VERSION ""

NS_ :

BS_:

BU_: wBMS

VAL_TABLE_ Cell_Balancing_Status 0 "IDLE" 1 "BALANCING" ;
VAL_TABLE_ Battery_Status 0 "INIT" 1 "READY" 2 "ACTIVE" 3 "FAILURE" ;

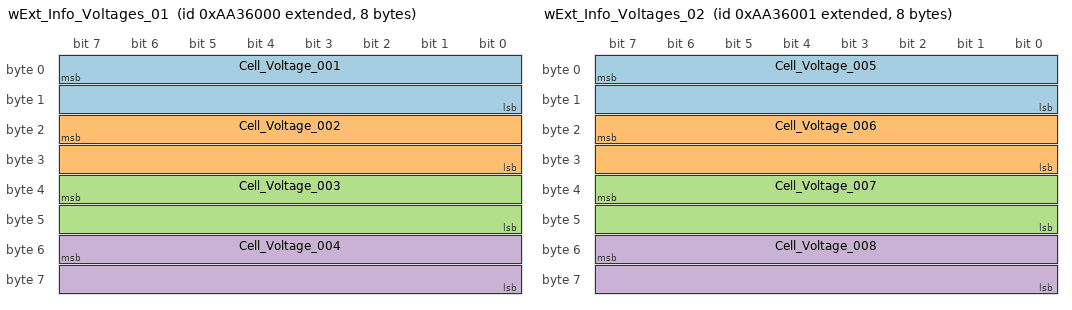
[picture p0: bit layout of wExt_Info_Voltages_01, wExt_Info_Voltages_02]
BO_ 2325962752 wExt_Info_Voltages_01: 8 wBMS
 SG_ Cell_Voltage_001 : 7|16@0+ (0.001,0) [0|0] "V" Vector__XXX
 SG_ Cell_Voltage_002 : 23|16@0+ (0.001,0) [0|0] "V" Vector__XXX
 SG_ Cell_Voltage_003 : 39|16@0+ (0.001,0) [0|0] "V" Vector__XXX
 SG_ Cell_Voltage_004 : 55|16@0+ (0.001,0) [0|0] "V" Vector__XXX

BO_ 2325962753 wExt_Info_Voltages_02: 8 wBMS
 SG_ Cell_Voltage_005 : 7|16@0+ (0.001,0) [0|0] "V" Vector__XXX
 SG_ Cell_Voltage_006 : 23|16@0+ (0.001,0) [0|0] "V" Vector__XXX
 SG_ Cell_Voltage_007 : 39|16@0+ (0.001,0) [0|0] "V" Vector__XXX
 SG_ Cell_Voltage_008 : 55|16@0+ (0.001,0) [0|0] "V" Vector__XXX

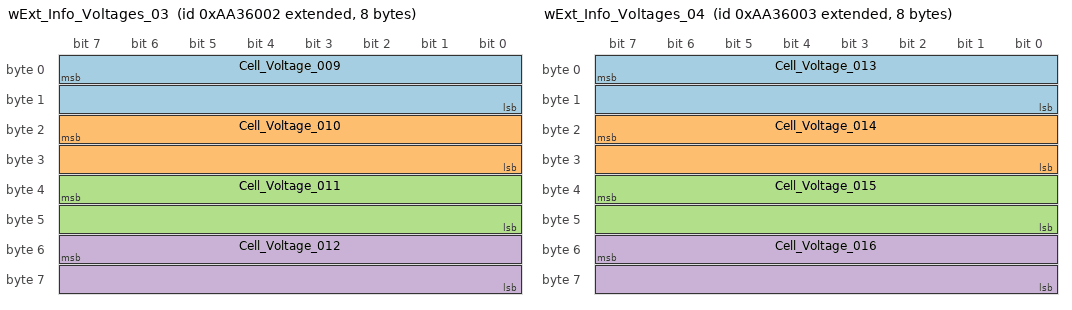
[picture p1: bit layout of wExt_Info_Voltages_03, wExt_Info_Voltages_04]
BO_ 2325962754 wExt_Info_Voltages_03: 8 wBMS
 SG_ Cell_Voltage_009 : 7|16@0+ (0.001,0) [0|0] "V" Vector__XXX
 SG_ Cell_Voltage_010 : 23|16@0+ (0.001,0) [0|0] "V" Vector__XXX
 SG_ Cell_Voltage_011 : 39|16@0+ (0.001,0) [0|0] "V" Vector__XXX
 SG_ Cell_Voltage_012 : 55|16@0+ (0.001,0) [0|0] "V" Vector__XXX

BO_ 2325962755 wExt_Info_Voltages_04: 8 wBMS
 SG_ Cell_Voltage_013 : 7|16@0+ (0.001,0) [0|0] "V" Vector__XXX
 SG_ Cell_Voltage_014 : 23|16@0+ (0.001,0) [0|0] "V" Vector__XXX
 SG_ Cell_Voltage_015 : 39|16@0+ (0.001,0) [0|0] "V" Vector__XXX
 SG_ Cell_Voltage_016 : 55|16@0+ (0.001,0) [0|0] "V" Vector__XXX

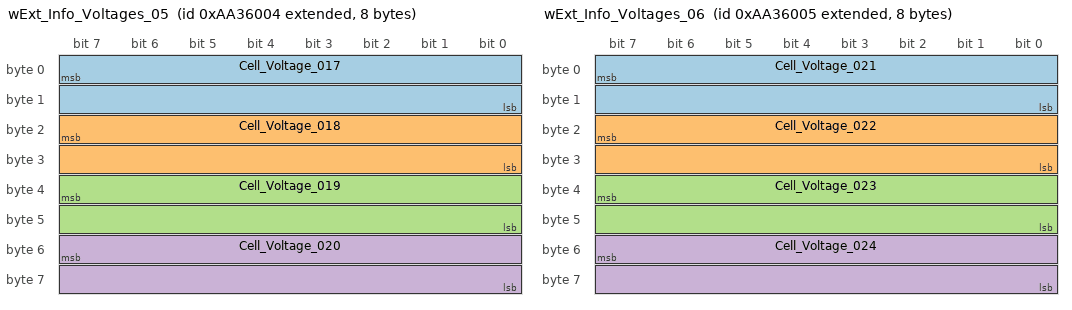
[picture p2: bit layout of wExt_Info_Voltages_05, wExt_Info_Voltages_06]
BO_ 2325962756 wExt_Info_Voltages_05: 8 wBMS
 SG_ Cell_Voltage_017 : 7|16@0+ (0.001,0) [0|0] "V" Vector__XXX
 SG_ Cell_Voltage_018 : 23|16@0+ (0.001,0) [0|0] "V" Vector__XXX
 SG_ Cell_Voltage_019 : 39|16@0+ (0.001,0) [0|0] "V" Vector__XXX
 SG_ Cell_Voltage_020 : 55|16@0+ (0.001,0) [0|0] "V" Vector__XXX

BO_ 2325962757 wExt_Info_Voltages_06: 8 wBMS
 SG_ Cell_Voltage_021 : 7|16@0+ (0.001,0) [0|0] "V" Vector__XXX
 SG_ Cell_Voltage_022 : 23|16@0+ (0.001,0) [0|0] "V" Vector__XXX
 SG_ Cell_Voltage_023 : 39|16@0+ (0.001,0) [0|0] "V" Vector__XXX
 SG_ Cell_Voltage_024 : 55|16@0+ (0.001,0) [0|0] "V" Vector__XXX

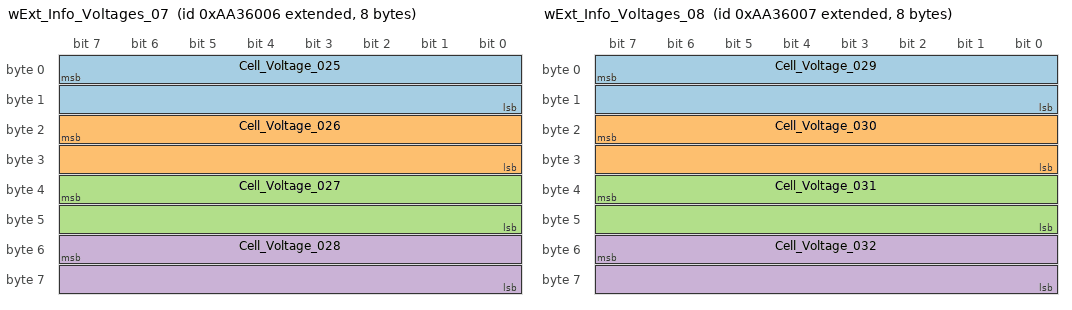
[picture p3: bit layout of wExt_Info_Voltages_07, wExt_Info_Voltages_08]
BO_ 2325962758 wExt_Info_Voltages_07: 8 wBMS
 SG_ Cell_Voltage_025 : 7|16@0+ (0.001,0) [0|0] "V" Vector__XXX
 SG_ Cell_Voltage_026 : 23|16@0+ (0.001,0) [0|0] "V" Vector__XXX
 SG_ Cell_Voltage_027 : 39|16@0+ (0.001,0) [0|0] "V" Vector__XXX
 SG_ Cell_Voltage_028 : 55|16@0+ (0.001,0) [0|0] "V" Vector__XXX

BO_ 2325962759 wExt_Info_Voltages_08: 8 wBMS
 SG_ Cell_Voltage_029 : 7|16@0+ (0.001,0) [0|0] "V" Vector__XXX
 SG_ Cell_Voltage_030 : 23|16@0+ (0.001,0) [0|0] "V" Vector__XXX
 SG_ Cell_Voltage_031 : 39|16@0+ (0.001,0) [0|0] "V" Vector__XXX
 SG_ Cell_Voltage_032 : 55|16@0+ (0.001,0) [0|0] "V" Vector__XXX

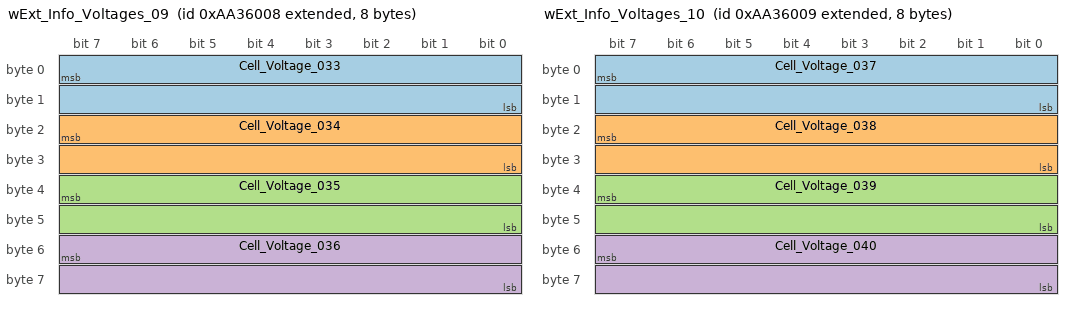
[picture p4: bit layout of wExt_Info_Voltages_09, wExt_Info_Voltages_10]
BO_ 2325962760 wExt_Info_Voltages_09: 8 wBMS
 SG_ Cell_Voltage_033 : 7|16@0+ (0.001,0) [0|0] "V" Vector__XXX
 SG_ Cell_Voltage_034 : 23|16@0+ (0.001,0) [0|0] "V" Vector__XXX
 SG_ Cell_Voltage_035 : 39|16@0+ (0.001,0) [0|0] "V" Vector__XXX
 SG_ Cell_Voltage_036 : 55|16@0+ (0.001,0) [0|0] "V" Vector__XXX

BO_ 2325962761 wExt_Info_Voltages_10: 8 wBMS
 SG_ Cell_Voltage_037 : 7|16@0+ (0.001,0) [0|0] "V" Vector__XXX
 SG_ Cell_Voltage_038 : 23|16@0+ (0.001,0) [0|0] "V" Vector__XXX
 SG_ Cell_Voltage_039 : 39|16@0+ (0.001,0) [0|0] "V" Vector__XXX
 SG_ Cell_Voltage_040 : 55|16@0+ (0.001,0) [0|0] "V" Vector__XXX

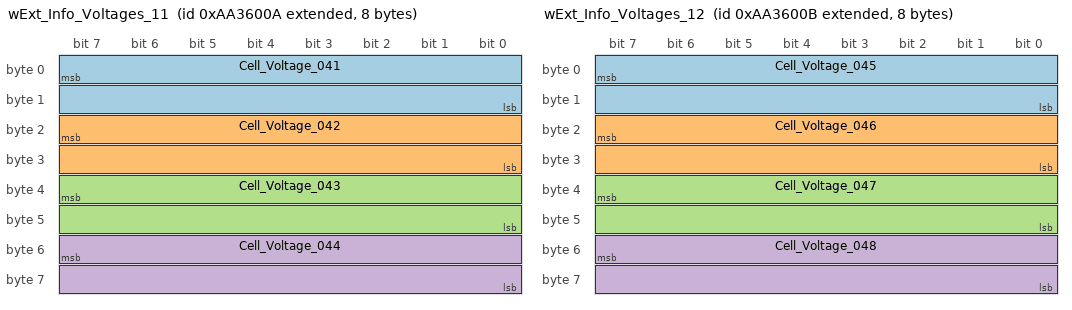
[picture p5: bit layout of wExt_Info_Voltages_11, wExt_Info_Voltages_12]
BO_ 2325962762 wExt_Info_Voltages_11: 8 wBMS
 SG_ Cell_Voltage_041 : 7|16@0+ (0.001,0) [0|0] "V" Vector__XXX
 SG_ Cell_Voltage_042 : 23|16@0+ (0.001,0) [0|0] "V" Vector__XXX
 SG_ Cell_Voltage_043 : 39|16@0+ (0.001,0) [0|0] "V" Vector__XXX
 SG_ Cell_Voltage_044 : 55|16@0+ (0.001,0) [0|0] "V" Vector__XXX

BO_ 2325962763 wExt_Info_Voltages_12: 8 wBMS
 SG_ Cell_Voltage_045 : 7|16@0+ (0.001,0) [0|0] "V" Vector__XXX
 SG_ Cell_Voltage_046 : 23|16@0+ (0.001,0) [0|0] "V" Vector__XXX
 SG_ Cell_Voltage_047 : 39|16@0+ (0.001,0) [0|0] "V" Vector__XXX
 SG_ Cell_Voltage_048 : 55|16@0+ (0.001,0) [0|0] "V" Vector__XXX

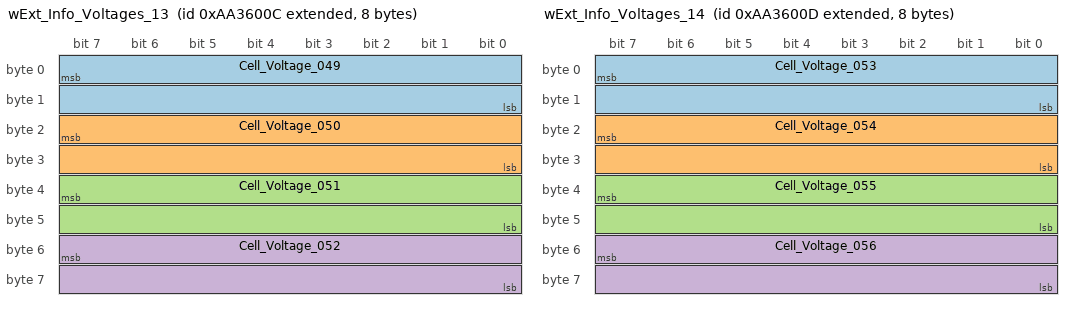
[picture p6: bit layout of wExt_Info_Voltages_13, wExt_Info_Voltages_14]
BO_ 2325962764 wExt_Info_Voltages_13: 8 wBMS
 SG_ Cell_Voltage_049 : 7|16@0+ (0.001,0) [0|0] "V" Vector__XXX
 SG_ Cell_Voltage_050 : 23|16@0+ (0.001,0) [0|0] "V" Vector__XXX
 SG_ Cell_Voltage_051 : 39|16@0+ (0.001,0) [0|0] "V" Vector__XXX
 SG_ Cell_Voltage_052 : 55|16@0+ (0.001,0) [0|0] "V" Vector__XXX

BO_ 2325962765 wExt_Info_Voltages_14: 8 wBMS
 SG_ Cell_Voltage_053 : 7|16@0+ (0.001,0) [0|0] "V" Vector__XXX
 SG_ Cell_Voltage_054 : 23|16@0+ (0.001,0) [0|0] "V" Vector__XXX
 SG_ Cell_Voltage_055 : 39|16@0+ (0.001,0) [0|0] "V" Vector__XXX
 SG_ Cell_Voltage_056 : 55|16@0+ (0.001,0) [0|0] "V" Vector__XXX

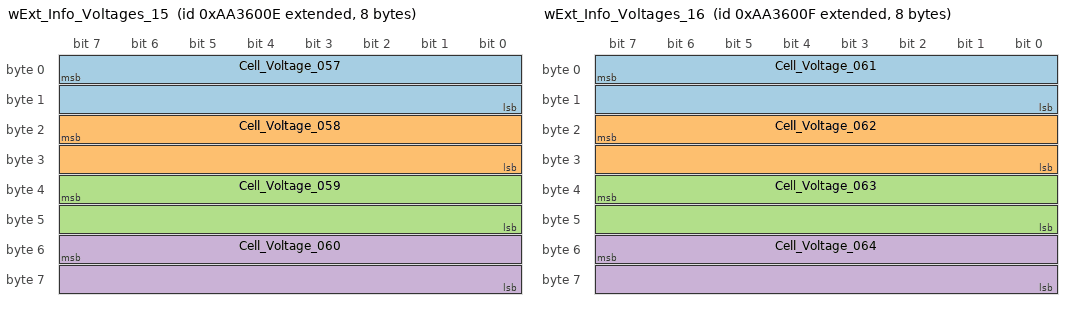
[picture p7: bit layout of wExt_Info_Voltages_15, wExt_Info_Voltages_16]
BO_ 2325962766 wExt_Info_Voltages_15: 8 wBMS
 SG_ Cell_Voltage_057 : 7|16@0+ (0.001,0) [0|0] "V" Vector__XXX
 SG_ Cell_Voltage_058 : 23|16@0+ (0.001,0) [0|0] "V" Vector__XXX
 SG_ Cell_Voltage_059 : 39|16@0+ (0.001,0) [0|0] "V" Vector__XXX
 SG_ Cell_Voltage_060 : 55|16@0+ (0.001,0) [0|0] "V" Vector__XXX

BO_ 2325962767 wExt_Info_Voltages_16: 8 wBMS
 SG_ Cell_Voltage_061 : 7|16@0+ (0.001,0) [0|0] "V" Vector__XXX
 SG_ Cell_Voltage_062 : 23|16@0+ (0.001,0) [0|0] "V" Vector__XXX
 SG_ Cell_Voltage_063 : 39|16@0+ (0.001,0) [0|0] "V" Vector__XXX
 SG_ Cell_Voltage_064 : 55|16@0+ (0.001,0) [0|0] "V" Vector__XXX

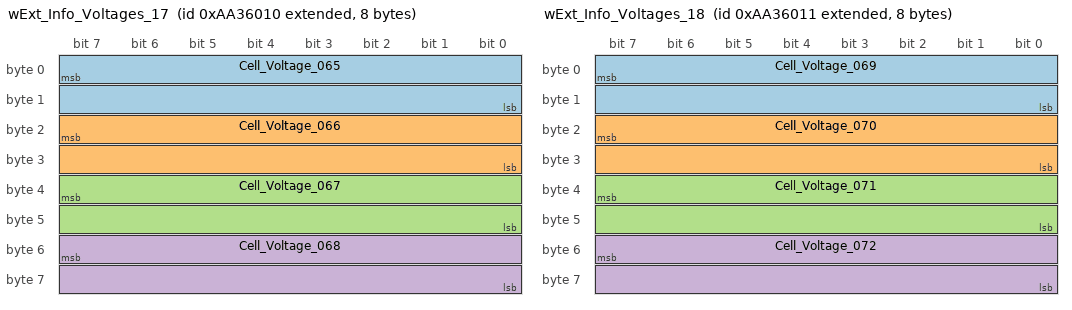
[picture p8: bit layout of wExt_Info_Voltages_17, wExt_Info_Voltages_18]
BO_ 2325962768 wExt_Info_Voltages_17: 8 wBMS
 SG_ Cell_Voltage_065 : 7|16@0+ (0.001,0) [0|0] "V" Vector__XXX
 SG_ Cell_Voltage_066 : 23|16@0+ (0.001,0) [0|0] "V" Vector__XXX
 SG_ Cell_Voltage_067 : 39|16@0+ (0.001,0) [0|0] "V" Vector__XXX
 SG_ Cell_Voltage_068 : 55|16@0+ (0.001,0) [0|0] "V" Vector__XXX

BO_ 2325962769 wExt_Info_Voltages_18: 8 wBMS
 SG_ Cell_Voltage_069 : 7|16@0+ (0.001,0) [0|0] "V" Vector__XXX
 SG_ Cell_Voltage_070 : 23|16@0+ (0.001,0) [0|0] "V" Vector__XXX
 SG_ Cell_Voltage_071 : 39|16@0+ (0.001,0) [0|0] "V" Vector__XXX
 SG_ Cell_Voltage_072 : 55|16@0+ (0.001,0) [0|0] "V" Vector__XXX

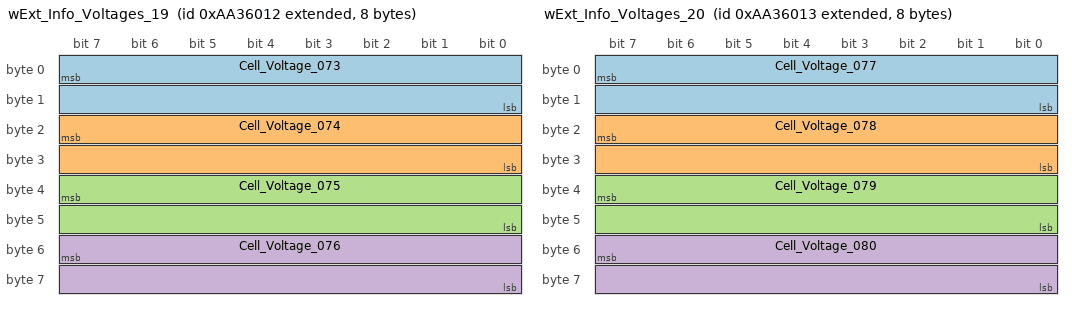
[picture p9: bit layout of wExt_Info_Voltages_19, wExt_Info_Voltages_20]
BO_ 2325962770 wExt_Info_Voltages_19: 8 wBMS
 SG_ Cell_Voltage_073 : 7|16@0+ (0.001,0) [0|0] "V" Vector__XXX
 SG_ Cell_Voltage_074 : 23|16@0+ (0.001,0) [0|0] "V" Vector__XXX
 SG_ Cell_Voltage_075 : 39|16@0+ (0.001,0) [0|0] "V" Vector__XXX
 SG_ Cell_Voltage_076 : 55|16@0+ (0.001,0) [0|0] "V" Vector__XXX

BO_ 2325962771 wExt_Info_Voltages_20: 8 wBMS
 SG_ Cell_Voltage_077 : 7|16@0+ (0.001,0) [0|0] "V" Vector__XXX
 SG_ Cell_Voltage_078 : 23|16@0+ (0.001,0) [0|0] "V" Vector__XXX
 SG_ Cell_Voltage_079 : 39|16@0+ (0.001,0) [0|0] "V" Vector__XXX
 SG_ Cell_Voltage_080 : 55|16@0+ (0.001,0) [0|0] "V" Vector__XXX

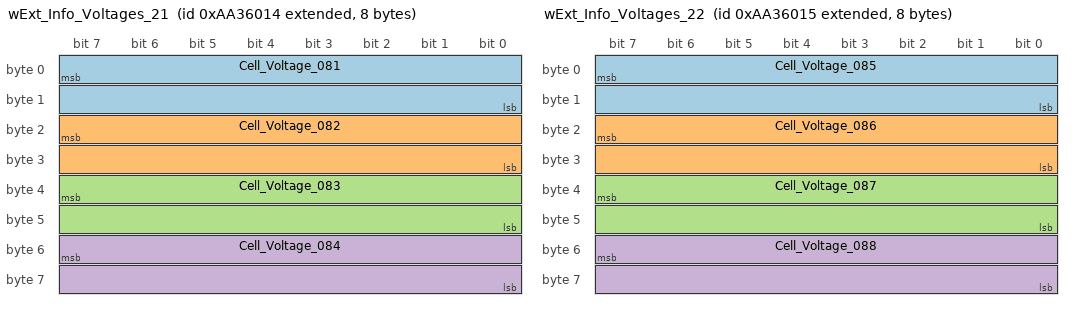
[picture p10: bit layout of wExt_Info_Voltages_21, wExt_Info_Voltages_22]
BO_ 2325962772 wExt_Info_Voltages_21: 8 wBMS
 SG_ Cell_Voltage_081 : 7|16@0+ (0.001,0) [0|0] "V" Vector__XXX
 SG_ Cell_Voltage_082 : 23|16@0+ (0.001,0) [0|0] "V" Vector__XXX
 SG_ Cell_Voltage_083 : 39|16@0+ (0.001,0) [0|0] "V" Vector__XXX
 SG_ Cell_Voltage_084 : 55|16@0+ (0.001,0) [0|0] "V" Vector__XXX

BO_ 2325962773 wExt_Info_Voltages_22: 8 wBMS
 SG_ Cell_Voltage_085 : 7|16@0+ (0.001,0) [0|0] "V" Vector__XXX
 SG_ Cell_Voltage_086 : 23|16@0+ (0.001,0) [0|0] "V" Vector__XXX
 SG_ Cell_Voltage_087 : 39|16@0+ (0.001,0) [0|0] "V" Vector__XXX
 SG_ Cell_Voltage_088 : 55|16@0+ (0.001,0) [0|0] "V" Vector__XXX

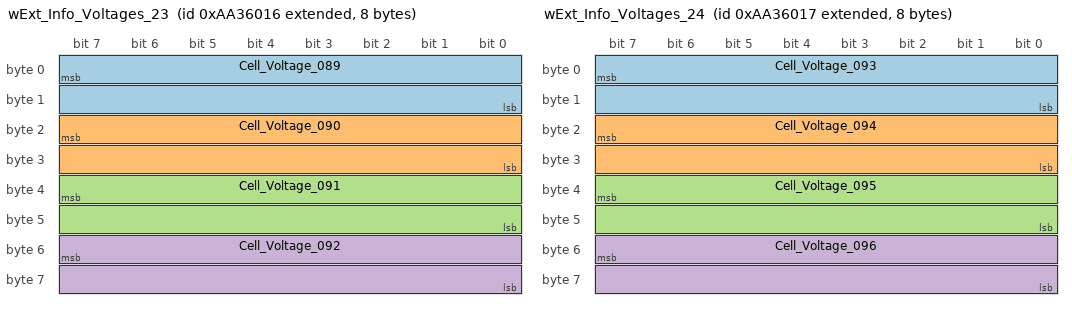
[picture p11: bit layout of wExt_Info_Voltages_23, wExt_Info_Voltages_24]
BO_ 2325962774 wExt_Info_Voltages_23: 8 wBMS
 SG_ Cell_Voltage_089 : 7|16@0+ (0.001,0) [0|0] "V" Vector__XXX
 SG_ Cell_Voltage_090 : 23|16@0+ (0.001,0) [0|0] "V" Vector__XXX
 SG_ Cell_Voltage_091 : 39|16@0+ (0.001,0) [0|0] "V" Vector__XXX
 SG_ Cell_Voltage_092 : 55|16@0+ (0.001,0) [0|0] "V" Vector__XXX

BO_ 2325962775 wExt_Info_Voltages_24: 8 wBMS
 SG_ Cell_Voltage_093 : 7|16@0+ (0.001,0) [0|0] "V" Vector__XXX
 SG_ Cell_Voltage_094 : 23|16@0+ (0.001,0) [0|0] "V" Vector__XXX
 SG_ Cell_Voltage_095 : 39|16@0+ (0.001,0) [0|0] "V" Vector__XXX
 SG_ Cell_Voltage_096 : 55|16@0+ (0.001,0) [0|0] "V" Vector__XXX

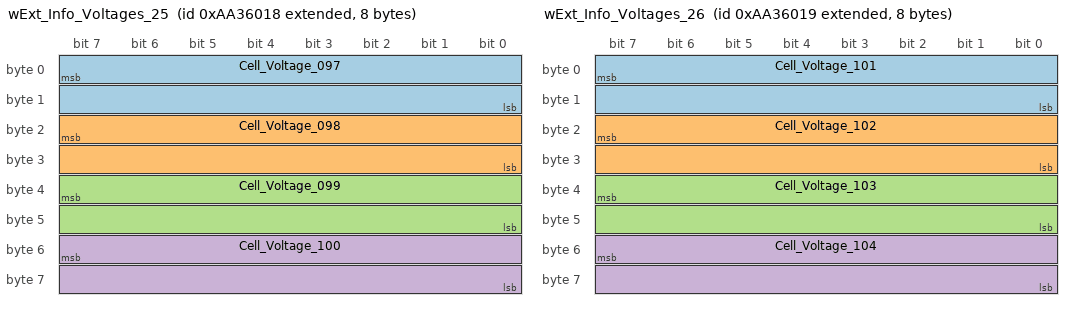
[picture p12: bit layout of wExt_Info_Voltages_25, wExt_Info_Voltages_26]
BO_ 2325962776 wExt_Info_Voltages_25: 8 wBMS
 SG_ Cell_Voltage_097 : 7|16@0+ (0.001,0) [0|0] "V" Vector__XXX
 SG_ Cell_Voltage_098 : 23|16@0+ (0.001,0) [0|0] "V" Vector__XXX
 SG_ Cell_Voltage_099 : 39|16@0+ (0.001,0) [0|0] "V" Vector__XXX
 SG_ Cell_Voltage_100 : 55|16@0+ (0.001,0) [0|0] "V" Vector__XXX

BO_ 2325962777 wExt_Info_Voltages_26: 8 wBMS
 SG_ Cell_Voltage_101 : 7|16@0+ (0.001,0) [0|0] "V" Vector__XXX
 SG_ Cell_Voltage_102 : 23|16@0+ (0.001,0) [0|0] "V" Vector__XXX
 SG_ Cell_Voltage_103 : 39|16@0+ (0.001,0) [0|0] "V" Vector__XXX
 SG_ Cell_Voltage_104 : 55|16@0+ (0.001,0) [0|0] "V" Vector__XXX

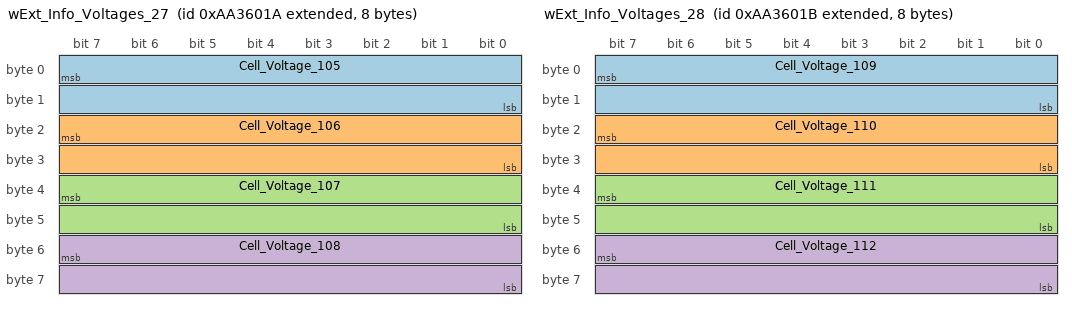
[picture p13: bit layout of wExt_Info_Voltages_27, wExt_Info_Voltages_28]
BO_ 2325962778 wExt_Info_Voltages_27: 8 wBMS
 SG_ Cell_Voltage_105 : 7|16@0+ (0.001,0) [0|0] "V" Vector__XXX
 SG_ Cell_Voltage_106 : 23|16@0+ (0.001,0) [0|0] "V" Vector__XXX
 SG_ Cell_Voltage_107 : 39|16@0+ (0.001,0) [0|0] "V" Vector__XXX
 SG_ Cell_Voltage_108 : 55|16@0+ (0.001,0) [0|0] "V" Vector__XXX

BO_ 2325962779 wExt_Info_Voltages_28: 8 wBMS
 SG_ Cell_Voltage_109 : 7|16@0+ (0.001,0) [0|0] "V" Vector__XXX
 SG_ Cell_Voltage_110 : 23|16@0+ (0.001,0) [0|0] "V" Vector__XXX
 SG_ Cell_Voltage_111 : 39|16@0+ (0.001,0) [0|0] "V" Vector__XXX
 SG_ Cell_Voltage_112 : 55|16@0+ (0.001,0) [0|0] "V" Vector__XXX

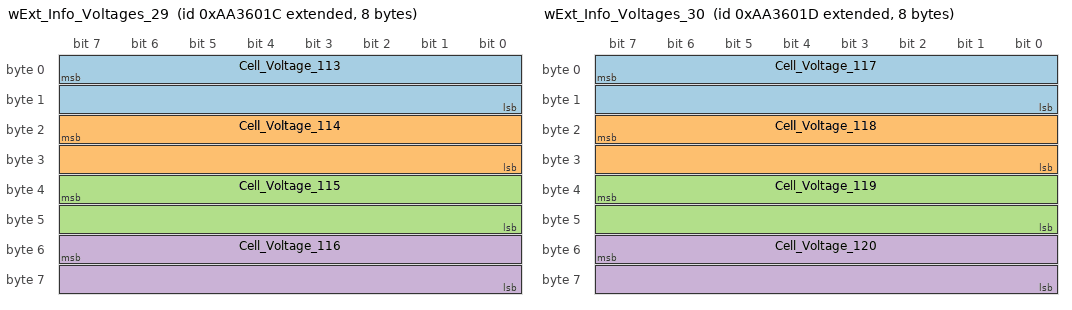
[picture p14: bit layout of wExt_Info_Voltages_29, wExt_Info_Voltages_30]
BO_ 2325962780 wExt_Info_Voltages_29: 8 wBMS
 SG_ Cell_Voltage_113 : 7|16@0+ (0.001,0) [0|0] "V" Vector__XXX
 SG_ Cell_Voltage_114 : 23|16@0+ (0.001,0) [0|0] "V" Vector__XXX
 SG_ Cell_Voltage_115 : 39|16@0+ (0.001,0) [0|0] "V" Vector__XXX
 SG_ Cell_Voltage_116 : 55|16@0+ (0.001,0) [0|0] "V" Vector__XXX

BO_ 2325962781 wExt_Info_Voltages_30: 8 wBMS
 SG_ Cell_Voltage_117 : 7|16@0+ (0.001,0) [0|0] "V" Vector__XXX
 SG_ Cell_Voltage_118 : 23|16@0+ (0.001,0) [0|0] "V" Vector__XXX
 SG_ Cell_Voltage_119 : 39|16@0+ (0.001,0) [0|0] "V" Vector__XXX
 SG_ Cell_Voltage_120 : 55|16@0+ (0.001,0) [0|0] "V" Vector__XXX

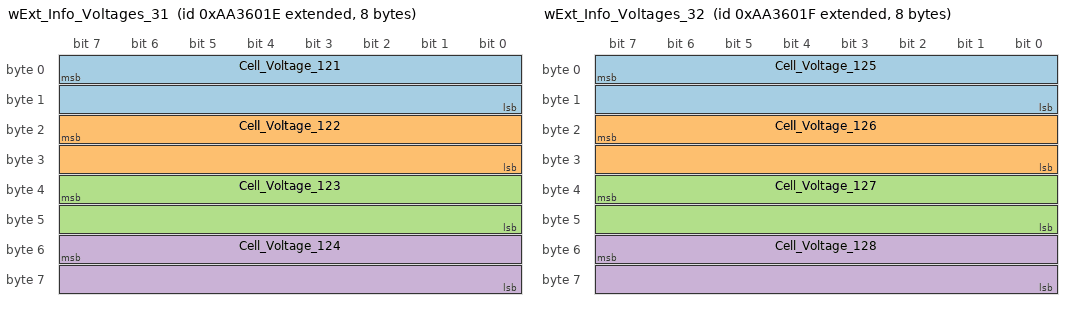
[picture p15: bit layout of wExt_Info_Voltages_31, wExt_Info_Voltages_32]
BO_ 2325962782 wExt_Info_Voltages_31: 8 wBMS
 SG_ Cell_Voltage_121 : 7|16@0+ (0.001,0) [0|0] "V" Vector__XXX
 SG_ Cell_Voltage_122 : 23|16@0+ (0.001,0) [0|0] "V" Vector__XXX
 SG_ Cell_Voltage_123 : 39|16@0+ (0.001,0) [0|0] "V" Vector__XXX
 SG_ Cell_Voltage_124 : 55|16@0+ (0.001,0) [0|0] "V" Vector__XXX

BO_ 2325962783 wExt_Info_Voltages_32: 8 wBMS
 SG_ Cell_Voltage_125 : 7|16@0+ (0.001,0) [0|0] "V" Vector__XXX
 SG_ Cell_Voltage_126 : 23|16@0+ (0.001,0) [0|0] "V" Vector__XXX
 SG_ Cell_Voltage_127 : 39|16@0+ (0.001,0) [0|0] "V" Vector__XXX
 SG_ Cell_Voltage_128 : 55|16@0+ (0.001,0) [0|0] "V" Vector__XXX

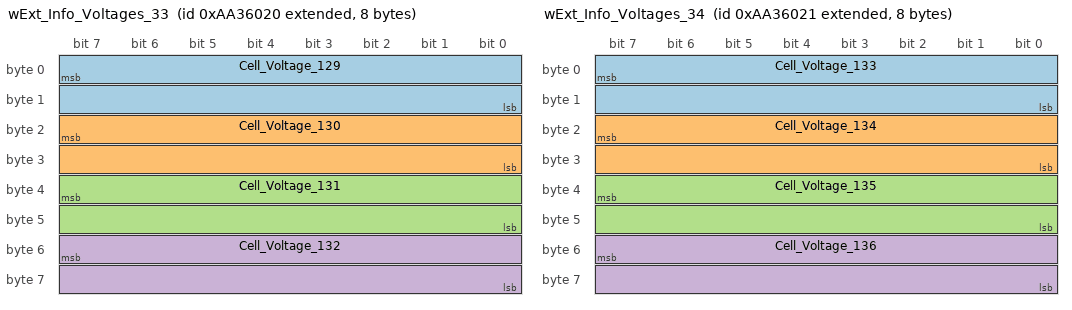
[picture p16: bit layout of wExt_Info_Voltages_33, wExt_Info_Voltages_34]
BO_ 2325962784 wExt_Info_Voltages_33: 8 wBMS
 SG_ Cell_Voltage_129 : 7|16@0+ (0.001,0) [0|0] "V" Vector__XXX
 SG_ Cell_Voltage_130 : 23|16@0+ (0.001,0) [0|0] "V" Vector__XXX
 SG_ Cell_Voltage_131 : 39|16@0+ (0.001,0) [0|0] "V" Vector__XXX
 SG_ Cell_Voltage_132 : 55|16@0+ (0.001,0) [0|0] "V" Vector__XXX

BO_ 2325962785 wExt_Info_Voltages_34: 8 wBMS
 SG_ Cell_Voltage_133 : 7|16@0+ (0.001,0) [0|0] "V" Vector__XXX
 SG_ Cell_Voltage_134 : 23|16@0+ (0.001,0) [0|0] "V" Vector__XXX
 SG_ Cell_Voltage_135 : 39|16@0+ (0.001,0) [0|0] "V" Vector__XXX
 SG_ Cell_Voltage_136 : 55|16@0+ (0.001,0) [0|0] "V" Vector__XXX

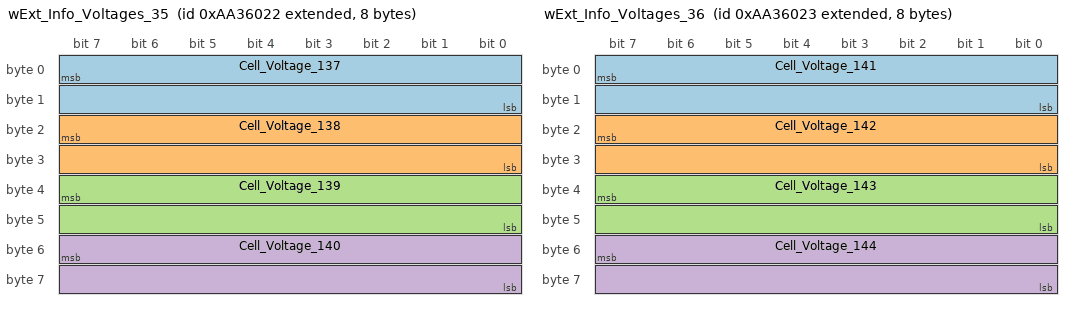
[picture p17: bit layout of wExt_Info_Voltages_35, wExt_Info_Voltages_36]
BO_ 2325962786 wExt_Info_Voltages_35: 8 wBMS
 SG_ Cell_Voltage_137 : 7|16@0+ (0.001,0) [0|0] "V" Vector__XXX
 SG_ Cell_Voltage_138 : 23|16@0+ (0.001,0) [0|0] "V" Vector__XXX
 SG_ Cell_Voltage_139 : 39|16@0+ (0.001,0) [0|0] "V" Vector__XXX
 SG_ Cell_Voltage_140 : 55|16@0+ (0.001,0) [0|0] "V" Vector__XXX

BO_ 2325962787 wExt_Info_Voltages_36: 8 wBMS
 SG_ Cell_Voltage_141 : 7|16@0+ (0.001,0) [0|0] "V" Vector__XXX
 SG_ Cell_Voltage_142 : 23|16@0+ (0.001,0) [0|0] "V" Vector__XXX
 SG_ Cell_Voltage_143 : 39|16@0+ (0.001,0) [0|0] "V" Vector__XXX
 SG_ Cell_Voltage_144 : 55|16@0+ (0.001,0) [0|0] "V" Vector__XXX

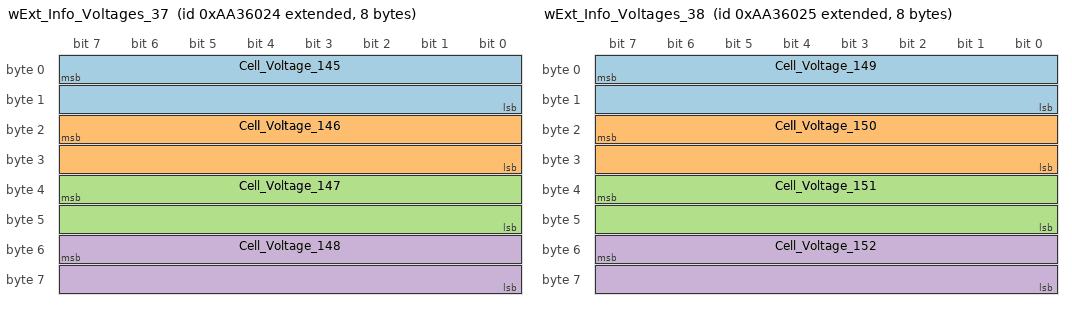
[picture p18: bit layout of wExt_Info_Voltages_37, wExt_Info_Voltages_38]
BO_ 2325962788 wExt_Info_Voltages_37: 8 wBMS
 SG_ Cell_Voltage_145 : 7|16@0+ (0.001,0) [0|0] "V" Vector__XXX
 SG_ Cell_Voltage_146 : 23|16@0+ (0.001,0) [0|0] "V" Vector__XXX
 SG_ Cell_Voltage_147 : 39|16@0+ (0.001,0) [0|0] "V" Vector__XXX
 SG_ Cell_Voltage_148 : 55|16@0+ (0.001,0) [0|0] "V" Vector__XXX

BO_ 2325962789 wExt_Info_Voltages_38: 8 wBMS
 SG_ Cell_Voltage_149 : 7|16@0+ (0.001,0) [0|0] "V" Vector__XXX
 SG_ Cell_Voltage_150 : 23|16@0+ (0.001,0) [0|0] "V" Vector__XXX
 SG_ Cell_Voltage_151 : 39|16@0+ (0.001,0) [0|0] "V" Vector__XXX
 SG_ Cell_Voltage_152 : 55|16@0+ (0.001,0) [0|0] "V" Vector__XXX

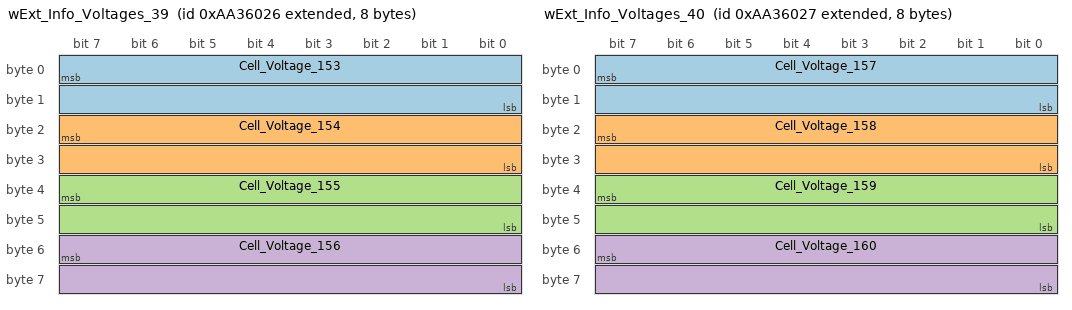
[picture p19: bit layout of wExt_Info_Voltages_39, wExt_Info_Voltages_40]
BO_ 2325962790 wExt_Info_Voltages_39: 8 wBMS
 SG_ Cell_Voltage_153 : 7|16@0+ (0.001,0) [0|0] "V" Vector__XXX
 SG_ Cell_Voltage_154 : 23|16@0+ (0.001,0) [0|0] "V" Vector__XXX
 SG_ Cell_Voltage_155 : 39|16@0+ (0.001,0) [0|0] "V" Vector__XXX
 SG_ Cell_Voltage_156 : 55|16@0+ (0.001,0) [0|0] "V" Vector__XXX

BO_ 2325962791 wExt_Info_Voltages_40: 8 wBMS
 SG_ Cell_Voltage_157 : 7|16@0+ (0.001,0) [0|0] "V" Vector__XXX
 SG_ Cell_Voltage_158 : 23|16@0+ (0.001,0) [0|0] "V" Vector__XXX
 SG_ Cell_Voltage_159 : 39|16@0+ (0.001,0) [0|0] "V" Vector__XXX
 SG_ Cell_Voltage_160 : 55|16@0+ (0.001,0) [0|0] "V" Vector__XXX

BO_ 2325962792 wExt_Info_Voltages_41: 8 wBMS
 SG_ Cell_Voltage_161 : 7|16@0+ (0.001,0) [0|0] "V" Vector__XXX
 SG_ Cell_Voltage_162 : 23|16@0+ (0.001,0) [0|0] "V" Vector__XXX
 SG_ Cell_Voltage_163 : 39|16@0+ (0.001,0) [0|0] "V" Vector__XXX
 SG_ Cell_Voltage_164 : 55|16@0+ (0.001,0) [0|0] "V" Vector__XXX

BO_ 2325962793 wExt_Info_Voltages_42: 8 wBMS
 SG_ Cell_Voltage_165 : 7|16@0+ (0.001,0) [0|0] "V" Vector__XXX
 SG_ Cell_Voltage_166 : 23|16@0+ (0.001,0) [0|0] "V" Vector__XXX
 SG_ Cell_Voltage_167 : 39|16@0+ (0.001,0) [0|0] "V" Vector__XXX
 SG_ Cell_Voltage_168 : 55|16@0+ (0.001,0) [0|0] "V" Vector__XXX

BO_ 2325962794 wExt_Info_Voltages_43: 8 wBMS
 SG_ Cell_Voltage_169 : 7|16@0+ (0.001,0) [0|0] "V" Vector__XXX
 SG_ Cell_Voltage_170 : 23|16@0+ (0.001,0) [0|0] "V" Vector__XXX
 SG_ Cell_Voltage_171 : 39|16@0+ (0.001,0) [0|0] "V" Vector__XXX
 SG_ Cell_Voltage_172 : 55|16@0+ (0.001,0) [0|0] "V" Vector__XXX

BO_ 2325962795 wExt_Info_Voltages_44: 8 wBMS
 SG_ Cell_Voltage_173 : 7|16@0+ (0.001,0) [0|0] "V" Vector__XXX
 SG_ Cell_Voltage_174 : 23|16@0+ (0.001,0) [0|0] "V" Vector__XXX
 SG_ Cell_Voltage_175 : 39|16@0+ (0.001,0) [0|0] "V" Vector__XXX
 SG_ Cell_Voltage_176 : 55|16@0+ (0.001,0) [0|0] "V" Vector__XXX

BO_ 2325962796 wExt_Info_Voltages_45: 8 wBMS
 SG_ Cell_Voltage_177 : 7|16@0+ (0.001,0) [0|0] "V" Vector__XXX
 SG_ Cell_Voltage_178 : 23|16@0+ (0.001,0) [0|0] "V" Vector__XXX
 SG_ Cell_Voltage_179 : 39|16@0+ (0.001,0) [0|0] "V" Vector__XXX
 SG_ Cell_Voltage_180 : 55|16@0+ (0.001,0) [0|0] "V" Vector__XXX

BO_ 2325962797 wExt_Info_Voltages_46: 8 wBMS
 SG_ Cell_Voltage_181 : 7|16@0+ (0.001,0) [0|0] "V" Vector__XXX
 SG_ Cell_Voltage_182 : 23|16@0+ (0.001,0) [0|0] "V" Vector__XXX
 SG_ Cell_Voltage_183 : 39|16@0+ (0.001,0) [0|0] "V" Vector__XXX
 SG_ Cell_Voltage_184 : 55|16@0+ (0.001,0) [0|0] "V" Vector__XXX

BO_ 2325962798 wExt_Info_Voltages_47: 8 wBMS
 SG_ Cell_Voltage_185 : 7|16@0+ (0.001,0) [0|0] "V" Vector__XXX
 SG_ Cell_Voltage_186 : 23|16@0+ (0.001,0) [0|0] "V" Vector__XXX
 SG_ Cell_Voltage_187 : 39|16@0+ (0.001,0) [0|0] "V" Vector__XXX
 SG_ Cell_Voltage_188 : 55|16@0+ (0.001,0) [0|0] "V" Vector__XXX

BO_ 2325962799 wExt_Info_Voltages_48: 8 wBMS
 SG_ Cell_Voltage_189 : 7|16@0+ (0.001,0) [0|0] "V" Vector__XXX
 SG_ Cell_Voltage_190 : 23|16@0+ (0.001,0) [0|0] "V" Vector__XXX
 SG_ Cell_Voltage_191 : 39|16@0+ (0.001,0) [0|0] "V" Vector__XXX
 SG_ Cell_Voltage_192 : 55|16@0+ (0.001,0) [0|0] "V" Vector__XXX

BO_ 2325962800 wExt_Info_Voltages_49: 8 wBMS
 SG_ Cell_Voltage_193 : 7|16@0+ (0.001,0) [0|0] "V" Vector__XXX
 SG_ Cell_Voltage_194 : 23|16@0+ (0.001,0) [0|0] "V" Vector__XXX
 SG_ Cell_Voltage_195 : 39|16@0+ (0.001,0) [0|0] "V" Vector__XXX
 SG_ Cell_Voltage_196 : 55|16@0+ (0.001,0) [0|0] "V" Vector__XXX

BO_ 2325962801 wExt_Info_Voltages_50: 8 wBMS
 SG_ Cell_Voltage_197 : 7|16@0+ (0.001,0) [0|0] "V" Vector__XXX
 SG_ Cell_Voltage_198 : 23|16@0+ (0.001,0) [0|0] "V" Vector__XXX
 SG_ Cell_Voltage_199 : 39|16@0+ (0.001,0) [0|0] "V" Vector__XXX
 SG_ Cell_Voltage_200 : 55|16@0+ (0.001,0) [0|0] "V" Vector__XXX

BO_ 2325962802 wExt_Info_Voltages_51: 8 wBMS
 SG_ Cell_Voltage_201 : 7|16@0+ (0.001,0) [0|0] "V" Vector__XXX
 SG_ Cell_Voltage_202 : 23|16@0+ (0.001,0) [0|0] "V" Vector__XXX
 SG_ Cell_Voltage_203 : 39|16@0+ (0.001,0) [0|0] "V" Vector__XXX
 SG_ Cell_Voltage_204 : 55|16@0+ (0.001,0) [0|0] "V" Vector__XXX

BO_ 2325962803 wExt_Info_Voltages_52: 8 wBMS
 SG_ Cell_Voltage_205 : 7|16@0+ (0.001,0) [0|0] "V" Vector__XXX
 SG_ Cell_Voltage_206 : 23|16@0+ (0.001,0) [0|0] "V" Vector__XXX
 SG_ Cell_Voltage_207 : 39|16@0+ (0.001,0) [0|0] "V" Vector__XXX
 SG_ Cell_Voltage_208 : 55|16@0+ (0.001,0) [0|0] "V" Vector__XXX

BO_ 2325962804 wExt_Info_Voltages_53: 8 wBMS
 SG_ Cell_Voltage_209 : 7|16@0+ (0.001,0) [0|0] "V" Vector__XXX
 SG_ Cell_Voltage_210 : 23|16@0+ (0.001,0) [0|0] "V" Vector__XXX
 SG_ Cell_Voltage_211 : 39|16@0+ (0.001,0) [0|0] "V" Vector__XXX
 SG_ Cell_Voltage_212 : 55|16@0+ (0.001,0) [0|0] "V" Vector__XXX

BO_ 2325962805 wExt_Info_Voltages_54: 8 wBMS
 SG_ Cell_Voltage_213 : 7|16@0+ (0.001,0) [0|0] "V" Vector__XXX
 SG_ Cell_Voltage_214 : 23|16@0+ (0.001,0) [0|0] "V" Vector__XXX
 SG_ Cell_Voltage_215 : 39|16@0+ (0.001,0) [0|0] "V" Vector__XXX
 SG_ Cell_Voltage_216 : 55|16@0+ (0.001,0) [0|0] "V" Vector__XXX

BO_ 2325962806 wExt_Info_Voltages_55: 8 wBMS
 SG_ Cell_Voltage_217 : 7|16@0+ (0.001,0) [0|0] "V" Vector__XXX
 SG_ Cell_Voltage_218 : 23|16@0+ (0.001,0) [0|0] "V" Vector__XXX
 SG_ Cell_Voltage_219 : 39|16@0+ (0.001,0) [0|0] "V" Vector__XXX
 SG_ Cell_Voltage_220 : 55|16@0+ (0.001,0) [0|0] "V" Vector__XXX

BO_ 2325962807 wExt_Info_Voltages_56: 8 wBMS
 SG_ Cell_Voltage_221 : 7|16@0+ (0.001,0) [0|0] "V" Vector__XXX
 SG_ Cell_Voltage_222 : 23|16@0+ (0.001,0) [0|0] "V" Vector__XXX
 SG_ Cell_Voltage_223 : 39|16@0+ (0.001,0) [0|0] "V" Vector__XXX
 SG_ Cell_Voltage_224 : 55|16@0+ (0.001,0) [0|0] "V" Vector__XXX

BO_ 2325962808 wExt_Info_Voltages_57: 8 wBMS
 SG_ Cell_Voltage_225 : 7|16@0+ (0.001,0) [0|0] "V" Vector__XXX
 SG_ Cell_Voltage_226 : 23|16@0+ (0.001,0) [0|0] "V" Vector__XXX
 SG_ Cell_Voltage_227 : 39|16@0+ (0.001,0) [0|0] "V" Vector__XXX
 SG_ Cell_Voltage_228 : 55|16@0+ (0.001,0) [0|0] "V" Vector__XXX

BO_ 2325962809 wExt_Info_Voltages_58: 8 wBMS
 SG_ Cell_Voltage_229 : 7|16@0+ (0.001,0) [0|0] "V" Vector__XXX
 SG_ Cell_Voltage_230 : 23|16@0+ (0.001,0) [0|0] "V" Vector__XXX
 SG_ Cell_Voltage_231 : 39|16@0+ (0.001,0) [0|0] "V" Vector__XXX
 SG_ Cell_Voltage_232 : 55|16@0+ (0.001,0) [0|0] "V" Vector__XXX

BO_ 2325962810 wExt_Info_Voltages_59: 8 wBMS
 SG_ Cell_Voltage_233 : 7|16@0+ (0.001,0) [0|0] "V" Vector__XXX
 SG_ Cell_Voltage_234 : 23|16@0+ (0.001,0) [0|0] "V" Vector__XXX
 SG_ Cell_Voltage_235 : 39|16@0+ (0.001,0) [0|0] "V" Vector__XXX
 SG_ Cell_Voltage_236 : 55|16@0+ (0.001,0) [0|0] "V" Vector__XXX

BO_ 2325962811 wExt_Info_Voltages_60: 8 wBMS
 SG_ Cell_Voltage_237 : 7|16@0+ (0.001,0) [0|0] "V" Vector__XXX
 SG_ Cell_Voltage_238 : 23|16@0+ (0.001,0) [0|0] "V" Vector__XXX
 SG_ Cell_Voltage_239 : 39|16@0+ (0.001,0) [0|0] "V" Vector__XXX
 SG_ Cell_Voltage_240 : 55|16@0+ (0.001,0) [0|0] "V" Vector__XXX

BO_ 2325962812 wExt_Info_Voltages_61: 8 wBMS
 SG_ Cell_Voltage_241 : 7|16@0+ (0.001,0) [0|0] "V" Vector__XXX
 SG_ Cell_Voltage_242 : 23|16@0+ (0.001,0) [0|0] "V" Vector__XXX
 SG_ Cell_Voltage_243 : 39|16@0+ (0.001,0) [0|0] "V" Vector__XXX
 SG_ Cell_Voltage_244 : 55|16@0+ (0.001,0) [0|0] "V" Vector__XXX

BO_ 2325962813 wExt_Info_Voltages_62: 8 wBMS
 SG_ Cell_Voltage_245 : 7|16@0+ (0.001,0) [0|0] "V" Vector__XXX
 SG_ Cell_Voltage_246 : 23|16@0+ (0.001,0) [0|0] "V" Vector__XXX
 SG_ Cell_Voltage_247 : 39|16@0+ (0.001,0) [0|0] "V" Vector__XXX
 SG_ Cell_Voltage_248 : 55|16@0+ (0.001,0) [0|0] "V" Vector__XXX

BO_ 2325962814 wExt_Info_Voltages_63: 8 wBMS
 SG_ Cell_Voltage_249 : 7|16@0+ (0.001,0) [0|0] "V" Vector__XXX
 SG_ Cell_Voltage_250 : 23|16@0+ (0.001,0) [0|0] "V" Vector__XXX
 SG_ Cell_Voltage_251 : 39|16@0+ (0.001,0) [0|0] "V" Vector__XXX
 SG_ Cell_Voltage_252 : 55|16@0+ (0.001,0) [0|0] "V" Vector__XXX

BO_ 2325962815 wExt_Info_Voltages_64: 8 wBMS
 SG_ Cell_Voltage_253 : 7|16@0+ (0.001,0) [0|0] "V" Vector__XXX
 SG_ Cell_Voltage_254 : 23|16@0+ (0.001,0) [0|0] "V" Vector__XXX
 SG_ Cell_Voltage_255 : 39|16@0+ (0.001,0) [0|0] "V" Vector__XXX
 SG_ Cell_Voltage_256 : 55|16@0+ (0.001,0) [0|0] "V" Vector__XXX

BO_ 2325962816 wExt_Info_Voltages_65: 8 wBMS
 SG_ Cell_Voltage_257 : 7|16@0+ (0.001,0) [0|0] "V" Vector__XXX
 SG_ Cell_Voltage_258 : 23|16@0+ (0.001,0) [0|0] "V" Vector__XXX
 SG_ Cell_Voltage_259 : 39|16@0+ (0.001,0) [0|0] "V" Vector__XXX
 SG_ Cell_Voltage_260 : 55|16@0+ (0.001,0) [0|0] "V" Vector__XXX

BO_ 2325962817 wExt_Info_Voltages_66: 8 wBMS
 SG_ Cell_Voltage_261 : 7|16@0+ (0.001,0) [0|0] "V" Vector__XXX
 SG_ Cell_Voltage_262 : 23|16@0+ (0.001,0) [0|0] "V" Vector__XXX
 SG_ Cell_Voltage_263 : 39|16@0+ (0.001,0) [0|0] "V" Vector__XXX
 SG_ Cell_Voltage_264 : 55|16@0+ (0.001,0) [0|0] "V" Vector__XXX

BO_ 2325962818 wExt_Info_Voltages_67: 8 wBMS
 SG_ Cell_Voltage_265 : 7|16@0+ (0.001,0) [0|0] "V" Vector__XXX
 SG_ Cell_Voltage_266 : 23|16@0+ (0.001,0) [0|0] "V" Vector__XXX
 SG_ Cell_Voltage_267 : 39|16@0+ (0.001,0) [0|0] "V" Vector__XXX
 SG_ Cell_Voltage_268 : 55|16@0+ (0.001,0) [0|0] "V" Vector__XXX

BO_ 2325962819 wExt_Info_Voltages_68: 8 wBMS
 SG_ Cell_Voltage_269 : 7|16@0+ (0.001,0) [0|0] "V" Vector__XXX
 SG_ Cell_Voltage_270 : 23|16@0+ (0.001,0) [0|0] "V" Vector__XXX
 SG_ Cell_Voltage_271 : 39|16@0+ (0.001,0) [0|0] "V" Vector__XXX
 SG_ Cell_Voltage_272 : 55|16@0+ (0.001,0) [0|0] "V" Vector__XXX

BO_ 2325962820 wExt_Info_Voltages_69: 8 wBMS
 SG_ Cell_Voltage_273 : 7|16@0+ (0.001,0) [0|0] "V" Vector__XXX
 SG_ Cell_Voltage_274 : 23|16@0+ (0.001,0) [0|0] "V" Vector__XXX
 SG_ Cell_Voltage_275 : 39|16@0+ (0.001,0) [0|0] "V" Vector__XXX
 SG_ Cell_Voltage_276 : 55|16@0+ (0.001,0) [0|0] "V" Vector__XXX

BO_ 2325962821 wExt_Info_Voltages_70: 8 wBMS
 SG_ Cell_Voltage_277 : 7|16@0+ (0.001,0) [0|0] "V" Vector__XXX
 SG_ Cell_Voltage_278 : 23|16@0+ (0.001,0) [0|0] "V" Vector__XXX
 SG_ Cell_Voltage_279 : 39|16@0+ (0.001,0) [0|0] "V" Vector__XXX
 SG_ Cell_Voltage_280 : 55|16@0+ (0.001,0) [0|0] "V" Vector__XXX

BO_ 2325962822 wExt_Info_Voltages_71: 8 wBMS
 SG_ Cell_Voltage_281 : 7|16@0+ (0.001,0) [0|0] "V" Vector__XXX
 SG_ Cell_Voltage_282 : 23|16@0+ (0.001,0) [0|0] "V" Vector__XXX
 SG_ Cell_Voltage_283 : 39|16@0+ (0.001,0) [0|0] "V" Vector__XXX
 SG_ Cell_Voltage_284 : 55|16@0+ (0.001,0) [0|0] "V" Vector__XXX

BO_ 2325962823 wExt_Info_Voltages_72: 8 wBMS
 SG_ Cell_Voltage_285 : 7|16@0+ (0.001,0) [0|0] "V" Vector__XXX
 SG_ Cell_Voltage_286 : 23|16@0+ (0.001,0) [0|0] "V" Vector__XXX
 SG_ Cell_Voltage_287 : 39|16@0+ (0.001,0) [0|0] "V" Vector__XXX
 SG_ Cell_Voltage_288 : 55|16@0+ (0.001,0) [0|0] "V" Vector__XXX

BO_ 2325962824 wExt_Info_Voltages_73: 8 wBMS
 SG_ Cell_Voltage_289 : 7|16@0+ (0.001,0) [0|0] "" Vector__XXX
 SG_ Cell_Voltage_290 : 23|16@0+ (0.001,0) [0|0] "" Vector__XXX
 SG_ Cell_Voltage_291 : 39|16@0+ (0.001,0) [0|0] "" Vector__XXX
 SG_ Cell_Voltage_292 : 55|16@0+ (0.001,0) [0|0] "" Vector__XXX

BO_ 2325962825 wExt_Info_Voltages_74: 8 wBMS
 SG_ Cell_Voltage_293 : 7|16@0+ (0.001,0) [0|0] "" Vector__XXX
 SG_ Cell_Voltage_294 : 23|16@0+ (0.001,0) [0|0] "" Vector__XXX
 SG_ Cell_Voltage_295 : 39|16@0+ (0.001,0) [0|0] "" Vector__XXX
 SG_ Cell_Voltage_296 : 55|16@0+ (0.001,0) [0|0] "" Vector__XXX

BO_ 2325962826 wExt_Info_Voltages_75: 8 wBMS
 SG_ Cell_Voltage_297 : 7|16@0+ (0.001,0) [0|0] "" Vector__XXX
 SG_ Cell_Voltage_298 : 23|16@0+ (0.001,0) [0|0] "" Vector__XXX
 SG_ Cell_Voltage_299 : 39|16@0+ (0.001,0) [0|0] "" Vector__XXX
 SG_ Cell_Voltage_300 : 55|16@0+ (0.001,0) [0|0] "" Vector__XXX

BO_ 2325962827 wExt_Info_Voltages_76: 8 wBMS
 SG_ Cell_Voltage_301 : 7|16@0+ (0.001,0) [0|0] "" Vector__XXX
 SG_ Cell_Voltage_302 : 23|16@0+ (0.001,0) [0|0] "" Vector__XXX
 SG_ Cell_Voltage_303 : 39|16@0+ (0.001,0) [0|0] "" Vector__XXX
 SG_ Cell_Voltage_304 : 55|16@0+ (0.001,0) [0|0] "" Vector__XXX

BO_ 2325962828 wExt_Info_Voltages_77: 8 wBMS
 SG_ Cell_Voltage_305 : 7|16@0+ (0.001,0) [0|0] "" Vector__XXX
 SG_ Cell_Voltage_306 : 23|16@0+ (0.001,0) [0|0] "" Vector__XXX
 SG_ Cell_Voltage_307 : 39|16@0+ (0.001,0) [0|0] "" Vector__XXX
 SG_ Cell_Voltage_308 : 55|16@0+ (0.001,0) [0|0] "" Vector__XXX

BO_ 2325962829 wExt_Info_Voltages_78: 8 wBMS
 SG_ Cell_Voltage_309 : 7|16@0+ (0.001,0) [0|0] "" Vector__XXX
 SG_ Cell_Voltage_310 : 23|16@0+ (0.001,0) [0|0] "" Vector__XXX
 SG_ Cell_Voltage_311 : 39|16@0+ (0.001,0) [0|0] "" Vector__XXX
 SG_ Cell_Voltage_312 : 55|16@0+ (0.001,0) [0|0] "" Vector__XXX

BO_ 2325962830 wExt_Info_Voltages_79: 8 wBMS
 SG_ Cell_Voltage_313 : 7|16@0+ (0.001,0) [0|0] "" Vector__XXX
 SG_ Cell_Voltage_314 : 23|16@0+ (0.001,0) [0|0] "" Vector__XXX
 SG_ Cell_Voltage_315 : 39|16@0+ (0.001,0) [0|0] "" Vector__XXX
 SG_ Cell_Voltage_316 : 55|16@0+ (0.001,0) [0|0] "" Vector__XXX

BO_ 2325962831 wExt_Info_Voltages_80: 8 wBMS
 SG_ Cell_Voltage_317 : 7|16@0+ (0.001,0) [0|0] "" Vector__XXX
 SG_ Cell_Voltage_318 : 23|16@0+ (0.001,0) [0|0] "" Vector__XXX
 SG_ Cell_Voltage_319 : 39|16@0+ (0.001,0) [0|0] "" Vector__XXX
 SG_ Cell_Voltage_320 : 55|16@0+ (0.001,0) [0|0] "" Vector__XXX

BO_ 2325962832 wExt_Info_Voltages_81: 8 wBMS
 SG_ Cell_Voltage_321 : 7|16@0+ (0.001,0) [0|0] "" Vector__XXX
 SG_ Cell_Voltage_322 : 23|16@0+ (0.001,0) [0|0] "" Vector__XXX
 SG_ Cell_Voltage_323 : 39|16@0+ (0.001,0) [0|0] "" Vector__XXX
 SG_ Cell_Voltage_324 : 55|16@0+ (0.001,0) [0|0] "" Vector__XXX

BO_ 2325962833 wExt_Info_Voltages_82: 8 wBMS
 SG_ Cell_Voltage_325 : 7|16@0+ (0.001,0) [0|0] "" Vector__XXX
 SG_ Cell_Voltage_326 : 23|16@0+ (0.001,0) [0|0] "" Vector__XXX
 SG_ Cell_Voltage_327 : 39|16@0+ (0.001,0) [0|0] "" Vector__XXX
 SG_ Cell_Voltage_328 : 55|16@0+ (0.001,0) [0|0] "" Vector__XXX

BO_ 2325962834 wExt_Info_Voltages_83: 8 wBMS
 SG_ Cell_Voltage_329 : 7|16@0+ (0.001,0) [0|0] "" Vector__XXX
 SG_ Cell_Voltage_330 : 23|16@0+ (0.001,0) [0|0] "" Vector__XXX
 SG_ Cell_Voltage_331 : 39|16@0+ (0.001,0) [0|0] "" Vector__XXX
 SG_ Cell_Voltage_332 : 55|16@0+ (0.001,0) [0|0] "" Vector__XXX

BO_ 2325962835 wExt_Info_Voltages_84: 8 wBMS
 SG_ Cell_Voltage_333 : 7|16@0+ (0.001,0) [0|0] "" Vector__XXX
 SG_ Cell_Voltage_334 : 23|16@0+ (0.001,0) [0|0] "" Vector__XXX
 SG_ Cell_Voltage_335 : 39|16@0+ (0.001,0) [0|0] "" Vector__XXX
 SG_ Cell_Voltage_336 : 55|16@0+ (0.001,0) [0|0] "" Vector__XXX

BO_ 2325962836 wExt_Info_Voltages_85: 8 wBMS
 SG_ Cell_Voltage_337 : 7|16@0+ (0.001,0) [0|0] "" Vector__XXX
 SG_ Cell_Voltage_338 : 23|16@0+ (0.001,0) [0|0] "" Vector__XXX
 SG_ Cell_Voltage_339 : 39|16@0+ (0.001,0) [0|0] "" Vector__XXX
 SG_ Cell_Voltage_340 : 55|16@0+ (0.001,0) [0|0] "" Vector__XXX

BO_ 2325962837 wExt_Info_Voltages_86: 8 wBMS
 SG_ Cell_Voltage_341 : 7|16@0+ (0.001,0) [0|0] "" Vector__XXX
 SG_ Cell_Voltage_342 : 23|16@0+ (0.001,0) [0|0] "" Vector__XXX
 SG_ Cell_Voltage_343 : 39|16@0+ (0.001,0) [0|0] "" Vector__XXX
 SG_ Cell_Voltage_344 : 55|16@0+ (0.001,0) [0|0] "" Vector__XXX

BO_ 2325962838 wExt_Info_Voltages_87: 8 wBMS
 SG_ Cell_Voltage_345 : 7|16@0+ (0.001,0) [0|0] "" Vector__XXX
 SG_ Cell_Voltage_346 : 23|16@0+ (0.001,0) [0|0] "" Vector__XXX
 SG_ Cell_Voltage_347 : 39|16@0+ (0.001,0) [0|0] "" Vector__XXX
 SG_ Cell_Voltage_348 : 55|16@0+ (0.001,0) [0|0] "" Vector__XXX

BO_ 2325962839 wExt_Info_Voltages_88: 8 wBMS
 SG_ Cell_Voltage_349 : 7|16@0+ (0.001,0) [0|0] "" Vector__XXX
 SG_ Cell_Voltage_350 : 23|16@0+ (0.001,0) [0|0] "" Vector__XXX
 SG_ Cell_Voltage_351 : 39|16@0+ (0.001,0) [0|0] "" Vector__XXX
 SG_ Cell_Voltage_352 : 55|16@0+ (0.001,0) [0|0] "" Vector__XXX

BO_ 2325962840 wExt_Info_Voltages_89: 8 wBMS
 SG_ Cell_Voltage_353 : 7|16@0+ (0.001,0) [0|0] "" Vector__XXX
 SG_ Cell_Voltage_354 : 23|16@0+ (0.001,0) [0|0] "" Vector__XXX
 SG_ Cell_Voltage_355 : 39|16@0+ (0.001,0) [0|0] "" Vector__XXX
 SG_ Cell_Voltage_356 : 55|16@0+ (0.001,0) [0|0] "" Vector__XXX

BO_ 2325962841 wExt_Info_Voltages_90: 8 wBMS
 SG_ Cell_Voltage_357 : 7|16@0+ (0.001,0) [0|0] "" Vector__XXX
 SG_ Cell_Voltage_358 : 23|16@0+ (0.001,0) [0|0] "" Vector__XXX
 SG_ Cell_Voltage_359 : 39|16@0+ (0.001,0) [0|0] "" Vector__XXX
 SG_ Cell_Voltage_360 : 55|16@0+ (0.001,0) [0|0] "" Vector__XXX

BO_ 2325962842 wExt_Info_Voltages_91: 8 wBMS
 SG_ Cell_Voltage_361 : 7|16@0+ (0.001,0) [0|0] "" Vector__XXX
 SG_ Cell_Voltage_362 : 23|16@0+ (0.001,0) [0|0] "" Vector__XXX
 SG_ Cell_Voltage_363 : 39|16@0+ (0.001,0) [0|0] "" Vector__XXX
 SG_ Cell_Voltage_364 : 55|16@0+ (0.001,0) [0|0] "" Vector__XXX

BO_ 2325962843 wExt_Info_Voltages_92: 8 wBMS
 SG_ Cell_Voltage_365 : 7|16@0+ (0.001,0) [0|0] "" Vector__XXX
 SG_ Cell_Voltage_366 : 23|16@0+ (0.001,0) [0|0] "" Vector__XXX
 SG_ Cell_Voltage_367 : 39|16@0+ (0.001,0) [0|0] "" Vector__XXX
 SG_ Cell_Voltage_368 : 55|16@0+ (0.001,0) [0|0] "" Vector__XXX

BO_ 2325962844 wExt_Info_Voltages_93: 8 wBMS
 SG_ Cell_Voltage_369 : 7|16@0+ (0.001,0) [0|0] "" Vector__XXX
 SG_ Cell_Voltage_370 : 23|16@0+ (0.001,0) [0|0] "" Vector__XXX
 SG_ Cell_Voltage_371 : 39|16@0+ (0.001,0) [0|0] "" Vector__XXX
 SG_ Cell_Voltage_372 : 55|16@0+ (0.001,0) [0|0] "" Vector__XXX

BO_ 2325962845 wExt_Info_Voltages_94: 8 wBMS
 SG_ Cell_Voltage_373 : 7|16@0+ (0.001,0) [0|0] "" Vector__XXX
 SG_ Cell_Voltage_374 : 23|16@0+ (0.001,0) [0|0] "" Vector__XXX
 SG_ Cell_Voltage_375 : 39|16@0+ (0.001,0) [0|0] "" Vector__XXX
 SG_ Cell_Voltage_376 : 55|16@0+ (0.001,0) [0|0] "" Vector__XXX

BO_ 2325962846 wExt_Info_Voltages_95: 8 wBMS
 SG_ Cell_Voltage_377 : 7|16@0+ (0.001,0) [0|0] "" Vector__XXX
 SG_ Cell_Voltage_378 : 23|16@0+ (0.001,0) [0|0] "" Vector__XXX
 SG_ Cell_Voltage_379 : 39|16@0+ (0.001,0) [0|0] "" Vector__XXX
 SG_ Cell_Voltage_380 : 55|16@0+ (0.001,0) [0|0] "" Vector__XXX

BO_ 2325962847 wExt_Info_Voltages_96: 8 wBMS
 SG_ Cell_Voltage_381 : 7|16@0+ (0.001,0) [0|0] "" Vector__XXX
 SG_ Cell_Voltage_382 : 23|16@0+ (0.001,0) [0|0] "" Vector__XXX
 SG_ Cell_Voltage_383 : 39|16@0+ (0.001,0) [0|0] "" Vector__XXX
 SG_ Cell_Voltage_384 : 55|16@0+ (0.001,0) [0|0] "" Vector__XXX

BO_ 2325962848 wExt_Info_Voltages_97: 8 wBMS
 SG_ Cell_Voltage_385 : 7|16@0+ (0.001,0) [0|0] "" Vector__XXX
 SG_ Cell_Voltage_386 : 23|16@0+ (0.001,0) [0|0] "" Vector__XXX
 SG_ Cell_Voltage_387 : 39|16@0+ (0.001,0) [0|0] "" Vector__XXX
 SG_ Cell_Voltage_388 : 55|16@0+ (0.001,0) [0|0] "" Vector__XXX

BO_ 2325962849 wExt_Info_Voltages_98: 8 wBMS
 SG_ Cell_Voltage_389 : 7|16@0+ (0.001,0) [0|0] "" Vector__XXX
 SG_ Cell_Voltage_390 : 23|16@0+ (0.001,0) [0|0] "" Vector__XXX
 SG_ Cell_Voltage_391 : 39|16@0+ (0.001,0) [0|0] "" Vector__XXX
 SG_ Cell_Voltage_392 : 55|16@0+ (0.001,0) [0|0] "" Vector__XXX

BO_ 2325962850 wExt_Info_Voltages_99: 8 wBMS
 SG_ Cell_Voltage_393 : 7|16@0+ (0.001,0) [0|0] "" Vector__XXX
 SG_ Cell_Voltage_394 : 23|16@0+ (0.001,0) [0|0] "" Vector__XXX
 SG_ Cell_Voltage_395 : 39|16@0+ (0.001,0) [0|0] "" Vector__XXX
 SG_ Cell_Voltage_396 : 55|16@0+ (0.001,0) [0|0] "" Vector__XXX

BO_ 2325962851 wExt_Info_Voltages_100: 8 wBMS
 SG_ Cell_Voltage_397 : 7|16@0+ (0.001,0) [0|0] "" Vector__XXX
 SG_ Cell_Voltage_398 : 23|16@0+ (0.001,0) [0|0] "" Vector__XXX
 SG_ Cell_Voltage_399 : 39|16@0+ (0.001,0) [0|0] "" Vector__XXX
 SG_ Cell_Voltage_400 : 55|16@0+ (0.001,0) [0|0] "" Vector__XXX

BO_ 2325962852 wExt_Info_Voltages_101: 8 wBMS
 SG_ Cell_Voltage_401 : 7|16@0+ (0.001,0) [0|0] "" Vector__XXX
 SG_ Cell_Voltage_402 : 23|16@0+ (0.001,0) [0|0] "" Vector__XXX
 SG_ Cell_Voltage_403 : 39|16@0+ (0.001,0) [0|0] "" Vector__XXX
 SG_ Cell_Voltage_404 : 55|16@0+ (0.001,0) [0|0] "" Vector__XXX

BO_ 2325962853 wExt_Info_Voltages_102: 8 wBMS
 SG_ Cell_Voltage_405 : 7|16@0+ (0.001,0) [0|0] "" Vector__XXX
 SG_ Cell_Voltage_406 : 23|16@0+ (0.001,0) [0|0] "" Vector__XXX
 SG_ Cell_Voltage_407 : 39|16@0+ (0.001,0) [0|0] "" Vector__XXX
 SG_ Cell_Voltage_408 : 55|16@0+ (0.001,0) [0|0] "" Vector__XXX

BO_ 2325962854 wExt_Info_Voltages_103: 8 wBMS
 SG_ Cell_Voltage_409 : 7|16@0+ (0.001,0) [0|0] "" Vector__XXX
 SG_ Cell_Voltage_410 : 23|16@0+ (0.001,0) [0|0] "" Vector__XXX
 SG_ Cell_Voltage_411 : 39|16@0+ (0.001,0) [0|0] "" Vector__XXX
 SG_ Cell_Voltage_412 : 55|16@0+ (0.001,0) [0|0] "" Vector__XXX

BO_ 2325962855 wExt_Info_Voltages_104: 8 wBMS
 SG_ Cell_Voltage_413 : 7|16@0+ (0.001,0) [0|0] "" Vector__XXX
 SG_ Cell_Voltage_414 : 23|16@0+ (0.001,0) [0|0] "" Vector__XXX
 SG_ Cell_Voltage_415 : 39|16@0+ (0.001,0) [0|0] "" Vector__XXX
 SG_ Cell_Voltage_416 : 55|16@0+ (0.001,0) [0|0] "" Vector__XXX

BO_ 2325962856 wExt_Info_Voltages_105: 8 wBMS
 SG_ Cell_Voltage_417 : 7|16@0+ (0.001,0) [0|0] "" Vector__XXX
 SG_ Cell_Voltage_418 : 23|16@0+ (0.001,0) [0|0] "" Vector__XXX
 SG_ Cell_Voltage_419 : 39|16@0+ (0.001,0) [0|0] "" Vector__XXX
 SG_ Cell_Voltage_420 : 55|16@0+ (0.001,0) [0|0] "" Vector__XXX

BO_ 2325962857 wExt_Info_Voltages_106: 8 wBMS
 SG_ Cell_Voltage_421 : 7|16@0+ (0.001,0) [0|0] "" Vector__XXX
 SG_ Cell_Voltage_422 : 23|16@0+ (0.001,0) [0|0] "" Vector__XXX
 SG_ Cell_Voltage_423 : 39|16@0+ (0.001,0) [0|0] "" Vector__XXX
 SG_ Cell_Voltage_424 : 55|16@0+ (0.001,0) [0|0] "" Vector__XXX

BO_ 2325962858 wExt_Info_Voltages_107: 8 wBMS
 SG_ Cell_Voltage_425 : 7|16@0+ (0.001,0) [0|0] "" Vector__XXX
 SG_ Cell_Voltage_426 : 23|16@0+ (0.001,0) [0|0] "" Vector__XXX
 SG_ Cell_Voltage_427 : 39|16@0+ (0.001,0) [0|0] "" Vector__XXX
 SG_ Cell_Voltage_428 : 55|16@0+ (0.001,0) [0|0] "" Vector__XXX

BO_ 2325962859 wExt_Info_Voltages_108: 8 wBMS
 SG_ Cell_Voltage_429 : 7|16@0+ (0.001,0) [0|0] "" Vector__XXX
 SG_ Cell_Voltage_430 : 23|16@0+ (0.001,0) [0|0] "" Vector__XXX
 SG_ Cell_Voltage_431 : 39|16@0+ (0.001,0) [0|0] "" Vector__XXX
 SG_ Cell_Voltage_432 : 55|16@0+ (0.001,0) [0|0] "" Vector__XXX

BO_ 2325962860 wExt_Info_Voltages_109: 8 wBMS
 SG_ Cell_Voltage_433 : 7|16@0+ (0.001,0) [0|0] "" Vector__XXX
 SG_ Cell_Voltage_434 : 23|16@0+ (0.001,0) [0|0] "" Vector__XXX
 SG_ Cell_Voltage_435 : 39|16@0+ (0.001,0) [0|0] "" Vector__XXX
 SG_ Cell_Voltage_436 : 55|16@0+ (0.001,0) [0|0] "" Vector__XXX

BO_ 2325962861 wExt_Info_Voltages_110: 8 wBMS
 SG_ Cell_Voltage_437 : 7|16@0+ (0.001,0) [0|0] "" Vector__XXX
 SG_ Cell_Voltage_438 : 23|16@0+ (0.001,0) [0|0] "" Vector__XXX
 SG_ Cell_Voltage_439 : 39|16@0+ (0.001,0) [0|0] "" Vector__XXX
 SG_ Cell_Voltage_440 : 55|16@0+ (0.001,0) [0|0] "" Vector__XXX

BO_ 2325962862 wExt_Info_Voltages_111: 8 wBMS
 SG_ Cell_Voltage_441 : 7|16@0+ (0.001,0) [0|0] "" Vector__XXX
 SG_ Cell_Voltage_442 : 23|16@0+ (0.001,0) [0|0] "" Vector__XXX
 SG_ Cell_Voltage_443 : 39|16@0+ (0.001,0) [0|0] "" Vector__XXX
 SG_ Cell_Voltage_444 : 55|16@0+ (0.001,0) [0|0] "" Vector__XXX

BO_ 2325962863 wExt_Info_Voltages_112: 8 wBMS
 SG_ Cell_Voltage_445 : 7|16@0+ (0.001,0) [0|0] "" Vector__XXX
 SG_ Cell_Voltage_446 : 23|16@0+ (0.001,0) [0|0] "" Vector__XXX
 SG_ Cell_Voltage_447 : 39|16@0+ (0.001,0) [0|0] "" Vector__XXX
 SG_ Cell_Voltage_448 : 55|16@0+ (0.001,0) [0|0] "" Vector__XXX

BO_ 2325962864 wExt_Info_Voltages_113: 8 wBMS
 SG_ Cell_Voltage_449 : 7|16@0+ (0.001,0) [0|0] "" Vector__XXX
 SG_ Cell_Voltage_450 : 23|16@0+ (0.001,0) [0|0] "" Vector__XXX
 SG_ Cell_Voltage_451 : 39|16@0+ (0.001,0) [0|0] "" Vector__XXX
 SG_ Cell_Voltage_452 : 55|16@0+ (0.001,0) [0|0] "" Vector__XXX

BO_ 2325962865 wExt_Info_Voltages_114: 8 wBMS
 SG_ Cell_Voltage_453 : 7|16@0+ (0.001,0) [0|0] "" Vector__XXX
 SG_ Cell_Voltage_454 : 23|16@0+ (0.001,0) [0|0] "" Vector__XXX
 SG_ Cell_Voltage_455 : 39|16@0+ (0.001,0) [0|0] "" Vector__XXX
 SG_ Cell_Voltage_456 : 55|16@0+ (0.001,0) [0|0] "" Vector__XXX

BO_ 2325962866 wExt_Info_Voltages_115: 8 wBMS
 SG_ Cell_Voltage_457 : 7|16@0+ (0.001,0) [0|0] "" Vector__XXX
 SG_ Cell_Voltage_458 : 23|16@0+ (0.001,0) [0|0] "" Vector__XXX
 SG_ Cell_Voltage_459 : 39|16@0+ (0.001,0) [0|0] "" Vector__XXX
 SG_ Cell_Voltage_460 : 55|16@0+ (0.001,0) [0|0] "" Vector__XXX

BO_ 2325962867 wExt_Info_Voltages_116: 8 wBMS
 SG_ Cell_Voltage_461 : 7|16@0+ (0.001,0) [0|0] "" Vector__XXX
 SG_ Cell_Voltage_462 : 23|16@0+ (0.001,0) [0|0] "" Vector__XXX
 SG_ Cell_Voltage_463 : 39|16@0+ (0.001,0) [0|0] "" Vector__XXX
 SG_ Cell_Voltage_464 : 55|16@0+ (0.001,0) [0|0] "" Vector__XXX

BO_ 2325962868 wExt_Info_Voltages_117: 8 wBMS
 SG_ Cell_Voltage_465 : 7|16@0+ (0.001,0) [0|0] "" Vector__XXX
 SG_ Cell_Voltage_466 : 23|16@0+ (0.001,0) [0|0] "" Vector__XXX
 SG_ Cell_Voltage_467 : 39|16@0+ (0.001,0) [0|0] "" Vector__XXX
 SG_ Cell_Voltage_468 : 55|16@0+ (0.001,0) [0|0] "" Vector__XXX

BO_ 2325962869 wExt_Info_Voltages_118: 8 wBMS
 SG_ Cell_Voltage_469 : 7|16@0+ (0.001,0) [0|0] "" Vector__XXX
 SG_ Cell_Voltage_470 : 23|16@0+ (0.001,0) [0|0] "" Vector__XXX
 SG_ Cell_Voltage_471 : 39|16@0+ (0.001,0) [0|0] "" Vector__XXX
 SG_ Cell_Voltage_472 : 55|16@0+ (0.001,0) [0|0] "" Vector__XXX

BO_ 2325962870 wExt_Info_Voltages_119: 8 wBMS
 SG_ Cell_Voltage_473 : 7|16@0+ (0.001,0) [0|0] "" Vector__XXX
 SG_ Cell_Voltage_474 : 23|16@0+ (0.001,0) [0|0] "" Vector__XXX
 SG_ Cell_Voltage_475 : 39|16@0+ (0.001,0) [0|0] "" Vector__XXX
 SG_ Cell_Voltage_476 : 55|16@0+ (0.001,0) [0|0] "" Vector__XXX

BO_ 2325962871 wExt_Info_Voltages_120: 8 wBMS
 SG_ Cell_Voltage_477 : 7|16@0+ (0.001,0) [0|0] "" Vector__XXX
 SG_ Cell_Voltage_478 : 23|16@0+ (0.001,0) [0|0] "" Vector__XXX
 SG_ Cell_Voltage_479 : 39|16@0+ (0.001,0) [0|0] "" Vector__XXX
 SG_ Cell_Voltage_480 : 55|16@0+ (0.001,0) [0|0] "" Vector__XXX

BO_ 2325962872 wExt_Info_Voltages_121: 8 wBMS
 SG_ Cell_Voltage_481 : 7|16@0+ (0.001,0) [0|0] "" Vector__XXX
 SG_ Cell_Voltage_482 : 23|16@0+ (0.001,0) [0|0] "" Vector__XXX
 SG_ Cell_Voltage_483 : 39|16@0+ (0.001,0) [0|0] "" Vector__XXX
 SG_ Cell_Voltage_484 : 55|16@0+ (0.001,0) [0|0] "" Vector__XXX

BO_ 2325962873 wExt_Info_Voltages_122: 8 wBMS
 SG_ Cell_Voltage_485 : 7|16@0+ (0.001,0) [0|0] "" Vector__XXX
 SG_ Cell_Voltage_486 : 23|16@0+ (0.001,0) [0|0] "" Vector__XXX
 SG_ Cell_Voltage_487 : 39|16@0+ (0.001,0) [0|0] "" Vector__XXX
 SG_ Cell_Voltage_488 : 55|16@0+ (0.001,0) [0|0] "" Vector__XXX

BO_ 2325962874 wExt_Info_Voltages_123: 8 wBMS
 SG_ Cell_Voltage_489 : 7|16@0+ (0.001,0) [0|0] "" Vector__XXX
 SG_ Cell_Voltage_490 : 23|16@0+ (0.001,0) [0|0] "" Vector__XXX
 SG_ Cell_Voltage_491 : 39|16@0+ (0.001,0) [0|0] "" Vector__XXX
 SG_ Cell_Voltage_492 : 55|16@0+ (0.001,0) [0|0] "" Vector__XXX

BO_ 2325962875 wExt_Info_Voltages_124: 8 wBMS
 SG_ Cell_Voltage_493 : 7|16@0+ (0.001,0) [0|0] "" Vector__XXX
 SG_ Cell_Voltage_494 : 23|16@0+ (0.001,0) [0|0] "" Vector__XXX
 SG_ Cell_Voltage_495 : 39|16@0+ (0.001,0) [0|0] "" Vector__XXX
 SG_ Cell_Voltage_496 : 55|16@0+ (0.001,0) [0|0] "" Vector__XXX

BO_ 2325962876 wExt_Info_Voltages_125: 8 wBMS
 SG_ Cell_Voltage_497 : 7|16@0+ (0.001,0) [0|0] "" Vector__XXX
 SG_ Cell_Voltage_498 : 23|16@0+ (0.001,0) [0|0] "" Vector__XXX
 SG_ Cell_Voltage_499 : 39|16@0+ (0.001,0) [0|0] "" Vector__XXX
 SG_ Cell_Voltage_500 : 55|16@0+ (0.001,0) [0|0] "" Vector__XXX

BO_ 2325962877 wExt_Info_Voltages_126: 8 wBMS
 SG_ Cell_Voltage_501 : 7|16@0+ (0.001,0) [0|0] "" Vector__XXX
 SG_ Cell_Voltage_502 : 23|16@0+ (0.001,0) [0|0] "" Vector__XXX
 SG_ Cell_Voltage_503 : 39|16@0+ (0.001,0) [0|0] "" Vector__XXX
 SG_ Cell_Voltage_504 : 55|16@0+ (0.001,0) [0|0] "" Vector__XXX

BO_ 2325962878 wExt_Info_Voltages_127: 8 wBMS
 SG_ Cell_Voltage_505 : 7|16@0+ (0.001,0) [0|0] "" Vector__XXX
 SG_ Cell_Voltage_506 : 23|16@0+ (0.001,0) [0|0] "" Vector__XXX
 SG_ Cell_Voltage_507 : 39|16@0+ (0.001,0) [0|0] "" Vector__XXX
 SG_ Cell_Voltage_508 : 55|16@0+ (0.001,0) [0|0] "" Vector__XXX

BO_ 2325962879 wExt_Info_Voltages_128: 8 wBMS
 SG_ Cell_Voltage_509 : 7|16@0+ (0.001,0) [0|0] "" Vector__XXX
 SG_ Cell_Voltage_510 : 23|16@0+ (0.001,0) [0|0] "" Vector__XXX
 SG_ Cell_Voltage_511 : 39|16@0+ (0.001,0) [0|0] "" Vector__XXX
 SG_ Cell_Voltage_512 : 55|16@0+ (0.001,0) [0|0] "" Vector__XXX

BO_ 2325962880 wExt_Info_Voltages_129: 8 wBMS
 SG_ Cell_Voltage_513 : 7|16@0+ (0.001,0) [0|0] "" Vector__XXX
 SG_ Cell_Voltage_514 : 23|16@0+ (0.001,0) [0|0] "" Vector__XXX
 SG_ Cell_Voltage_515 : 39|16@0+ (0.001,0) [0|0] "" Vector__XXX
 SG_ Cell_Voltage_516 : 55|16@0+ (0.001,0) [0|0] "" Vector__XXX

BO_ 2325962881 wExt_Info_Voltages_130: 8 wBMS
 SG_ Cell_Voltage_517 : 7|16@0+ (0.001,0) [0|0] "" Vector__XXX
 SG_ Cell_Voltage_518 : 23|16@0+ (0.001,0) [0|0] "" Vector__XXX
 SG_ Cell_Voltage_519 : 39|16@0+ (0.001,0) [0|0] "" Vector__XXX
 SG_ Cell_Voltage_520 : 55|16@0+ (0.001,0) [0|0] "" Vector__XXX

BO_ 2325962882 wExt_Info_Voltages_131: 8 wBMS
 SG_ Cell_Voltage_521 : 7|16@0+ (0.001,0) [0|0] "" Vector__XXX
 SG_ Cell_Voltage_522 : 23|16@0+ (0.001,0) [0|0] "" Vector__XXX
 SG_ Cell_Voltage_523 : 39|16@0+ (0.001,0) [0|0] "" Vector__XXX
 SG_ Cell_Voltage_524 : 55|16@0+ (0.001,0) [0|0] "" Vector__XXX

BO_ 2325962883 wExt_Info_Voltages_132: 8 wBMS
 SG_ Cell_Voltage_525 : 7|16@0+ (0.001,0) [0|0] "" Vector__XXX
 SG_ Cell_Voltage_526 : 23|16@0+ (0.001,0) [0|0] "" Vector__XXX
 SG_ Cell_Voltage_527 : 39|16@0+ (0.001,0) [0|0] "" Vector__XXX
 SG_ Cell_Voltage_528 : 55|16@0+ (0.001,0) [0|0] "" Vector__XXX

BO_ 2325962884 wExt_Info_Voltages_133: 8 wBMS
 SG_ Cell_Voltage_529 : 7|16@0+ (0.001,0) [0|0] "" Vector__XXX
 SG_ Cell_Voltage_530 : 23|16@0+ (0.001,0) [0|0] "" Vector__XXX
 SG_ Cell_Voltage_531 : 39|16@0+ (0.001,0) [0|0] "" Vector__XXX
 SG_ Cell_Voltage_532 : 55|16@0+ (0.001,0) [0|0] "" Vector__XXX

BO_ 2325962885 wExt_Info_Voltages_134: 8 wBMS
 SG_ Cell_Voltage_533 : 7|16@0+ (0.001,0) [0|0] "" Vector__XXX
 SG_ Cell_Voltage_534 : 23|16@0+ (0.001,0) [0|0] "" Vector__XXX
 SG_ Cell_Voltage_535 : 39|16@0+ (0.001,0) [0|0] "" Vector__XXX
 SG_ Cell_Voltage_536 : 55|16@0+ (0.001,0) [0|0] "" Vector__XXX

BO_ 2325962886 wExt_Info_Voltages_135: 8 wBMS
 SG_ Cell_Voltage_537 : 7|16@0+ (0.001,0) [0|0] "" Vector__XXX
 SG_ Cell_Voltage_538 : 23|16@0+ (0.001,0) [0|0] "" Vector__XXX
 SG_ Cell_Voltage_539 : 39|16@0+ (0.001,0) [0|0] "" Vector__XXX
 SG_ Cell_Voltage_540 : 55|16@0+ (0.001,0) [0|0] "" Vector__XXX

BO_ 2325962887 wExt_Info_Voltages_136: 8 wBMS
 SG_ Cell_Voltage_541 : 7|16@0+ (0.001,0) [0|0] "" Vector__XXX
 SG_ Cell_Voltage_542 : 23|16@0+ (0.001,0) [0|0] "" Vector__XXX
 SG_ Cell_Voltage_543 : 39|16@0+ (0.001,0) [0|0] "" Vector__XXX
 SG_ Cell_Voltage_544 : 55|16@0+ (0.001,0) [0|0] "" Vector__XXX

BO_ 2325962888 wExt_Info_Voltages_137: 8 wBMS
 SG_ Cell_Voltage_545 : 7|16@0+ (0.001,0) [0|0] "" Vector__XXX
 SG_ Cell_Voltage_546 : 23|16@0+ (0.001,0) [0|0] "" Vector__XXX
 SG_ Cell_Voltage_547 : 39|16@0+ (0.001,0) [0|0] "" Vector__XXX
 SG_ Cell_Voltage_548 : 55|16@0+ (0.001,0) [0|0] "" Vector__XXX

BO_ 2325962889 wExt_Info_Voltages_138: 8 wBMS
 SG_ Cell_Voltage_549 : 7|16@0+ (0.001,0) [0|0] "" Vector__XXX
 SG_ Cell_Voltage_550 : 23|16@0+ (0.001,0) [0|0] "" Vector__XXX
 SG_ Cell_Voltage_551 : 39|16@0+ (0.001,0) [0|0] "" Vector__XXX
 SG_ Cell_Voltage_552 : 55|16@0+ (0.001,0) [0|0] "" Vector__XXX

BO_ 2325962890 wExt_Info_Voltages_139: 8 wBMS
 SG_ Cell_Voltage_553 : 7|16@0+ (0.001,0) [0|0] "" Vector__XXX
 SG_ Cell_Voltage_554 : 23|16@0+ (0.001,0) [0|0] "" Vector__XXX
 SG_ Cell_Voltage_555 : 39|16@0+ (0.001,0) [0|0] "" Vector__XXX
 SG_ Cell_Voltage_556 : 55|16@0+ (0.001,0) [0|0] "" Vector__XXX

BO_ 2325962891 wExt_Info_Voltages_140: 8 wBMS
 SG_ Cell_Voltage_557 : 7|16@0+ (0.001,0) [0|0] "" Vector__XXX
 SG_ Cell_Voltage_558 : 23|16@0+ (0.001,0) [0|0] "" Vector__XXX
 SG_ Cell_Voltage_559 : 39|16@0+ (0.001,0) [0|0] "" Vector__XXX
 SG_ Cell_Voltage_560 : 55|16@0+ (0.001,0) [0|0] "" Vector__XXX

BO_ 2325962892 wExt_Info_Voltages_141: 8 wBMS
 SG_ Cell_Voltage_561 : 7|16@0+ (0.001,0) [0|0] "" Vector__XXX
 SG_ Cell_Voltage_562 : 23|16@0+ (0.001,0) [0|0] "" Vector__XXX
 SG_ Cell_Voltage_563 : 39|16@0+ (0.001,0) [0|0] "" Vector__XXX
 SG_ Cell_Voltage_564 : 55|16@0+ (0.001,0) [0|0] "" Vector__XXX

BO_ 2325962893 wExt_Info_Voltages_142: 8 wBMS
 SG_ Cell_Voltage_565 : 7|16@0+ (0.001,0) [0|0] "" Vector__XXX
 SG_ Cell_Voltage_566 : 23|16@0+ (0.001,0) [0|0] "" Vector__XXX
 SG_ Cell_Voltage_567 : 39|16@0+ (0.001,0) [0|0] "" Vector__XXX
 SG_ Cell_Voltage_568 : 55|16@0+ (0.001,0) [0|0] "" Vector__XXX

BO_ 2325962894 wExt_Info_Voltages_143: 8 wBMS
 SG_ Cell_Voltage_569 : 7|16@0+ (0.001,0) [0|0] "" Vector__XXX
 SG_ Cell_Voltage_570 : 23|16@0+ (0.001,0) [0|0] "" Vector__XXX
 SG_ Cell_Voltage_571 : 39|16@0+ (0.001,0) [0|0] "" Vector__XXX
 SG_ Cell_Voltage_572 : 55|16@0+ (0.001,0) [0|0] "" Vector__XXX

BO_ 2325962895 wExt_Info_Voltages_144: 8 wBMS
 SG_ Cell_Voltage_573 : 7|16@0+ (0.001,0) [0|0] "" Vector__XXX
 SG_ Cell_Voltage_574 : 23|16@0+ (0.001,0) [0|0] "" Vector__XXX
 SG_ Cell_Voltage_575 : 39|16@0+ (0.001,0) [0|0] "" Vector__XXX
 SG_ Cell_Voltage_576 : 55|16@0+ (0.001,0) [0|0] "" Vector__XXX

BO_ 2325962896 wExt_Info_Voltages_145: 8 wBMS
 SG_ Cell_Voltage_577 : 7|16@0+ (0.001,0) [0|0] "" Vector__XXX
 SG_ Cell_Voltage_578 : 23|16@0+ (0.001,0) [0|0] "" Vector__XXX
 SG_ Cell_Voltage_579 : 39|16@0+ (0.001,0) [0|0] "" Vector__XXX
 SG_ Cell_Voltage_580 : 55|16@0+ (0.001,0) [0|0] "" Vector__XXX

BO_ 2325962897 wExt_Info_Voltages_146: 8 wBMS
 SG_ Cell_Voltage_581 : 7|16@0+ (0.001,0) [0|0] "" Vector__XXX
 SG_ Cell_Voltage_582 : 23|16@0+ (0.001,0) [0|0] "" Vector__XXX
 SG_ Cell_Voltage_583 : 39|16@0+ (0.001,0) [0|0] "" Vector__XXX
 SG_ Cell_Voltage_584 : 55|16@0+ (0.001,0) [0|0] "" Vector__XXX

BO_ 2325962898 wExt_Info_Voltages_147: 8 wBMS
 SG_ Cell_Voltage_585 : 7|16@0+ (0.001,0) [0|0] "" Vector__XXX
 SG_ Cell_Voltage_586 : 23|16@0+ (0.001,0) [0|0] "" Vector__XXX
 SG_ Cell_Voltage_587 : 39|16@0+ (0.001,0) [0|0] "" Vector__XXX
 SG_ Cell_Voltage_588 : 55|16@0+ (0.001,0) [0|0] "" Vector__XXX

BO_ 2325962899 wExt_Info_Voltages_148: 8 wBMS
 SG_ Cell_Voltage_589 : 7|16@0+ (0.001,0) [0|0] "" Vector__XXX
 SG_ Cell_Voltage_590 : 23|16@0+ (0.001,0) [0|0] "" Vector__XXX
 SG_ Cell_Voltage_591 : 39|16@0+ (0.001,0) [0|0] "" Vector__XXX
 SG_ Cell_Voltage_592 : 55|16@0+ (0.001,0) [0|0] "" Vector__XXX

BO_ 2325962900 wExt_Info_Voltages_149: 8 wBMS
 SG_ Cell_Voltage_593 : 7|16@0+ (0.001,0) [0|0] "" Vector__XXX
 SG_ Cell_Voltage_594 : 23|16@0+ (0.001,0) [0|0] "" Vector__XXX
 SG_ Cell_Voltage_595 : 39|16@0+ (0.001,0) [0|0] "" Vector__XXX
 SG_ Cell_Voltage_596 : 55|16@0+ (0.001,0) [0|0] "" Vector__XXX

BO_ 2325962901 wExt_Info_Voltages_150: 8 wBMS
 SG_ Cell_Voltage_597 : 7|16@0+ (0.001,0) [0|0] "" Vector__XXX
 SG_ Cell_Voltage_598 : 23|16@0+ (0.001,0) [0|0] "" Vector__XXX
 SG_ Cell_Voltage_599 : 39|16@0+ (0.001,0) [0|0] "" Vector__XXX
 SG_ Cell_Voltage_600 : 55|16@0+ (0.001,0) [0|0] "" Vector__XXX

BO_ 2325962902 wExt_Info_Voltages_151: 8 wBMS
 SG_ Cell_Voltage_601 : 7|16@0+ (0.001,0) [0|0] "" Vector__XXX
 SG_ Cell_Voltage_602 : 23|16@0+ (0.001,0) [0|0] "" Vector__XXX
 SG_ Cell_Voltage_603 : 39|16@0+ (0.001,0) [0|0] "" Vector__XXX
 SG_ Cell_Voltage_604 : 55|16@0+ (0.001,0) [0|0] "" Vector__XXX

BO_ 2325962903 wExt_Info_Voltages_152: 8 wBMS
 SG_ Cell_Voltage_605 : 7|16@0+ (0.001,0) [0|0] "" Vector__XXX
 SG_ Cell_Voltage_606 : 23|16@0+ (0.001,0) [0|0] "" Vector__XXX
 SG_ Cell_Voltage_607 : 39|16@0+ (0.001,0) [0|0] "" Vector__XXX
 SG_ Cell_Voltage_608 : 55|16@0+ (0.001,0) [0|0] "" Vector__XXX

BO_ 2325962904 wExt_Info_Voltages_153: 8 wBMS
 SG_ Cell_Voltage_609 : 7|16@0+ (0.001,0) [0|0] "" Vector__XXX
 SG_ Cell_Voltage_610 : 23|16@0+ (0.001,0) [0|0] "" Vector__XXX
 SG_ Cell_Voltage_611 : 39|16@0+ (0.001,0) [0|0] "" Vector__XXX
 SG_ Cell_Voltage_612 : 55|16@0+ (0.001,0) [0|0] "" Vector__XXX

BO_ 2325962905 wExt_Info_Voltages_154: 8 wBMS
 SG_ Cell_Voltage_613 : 7|16@0+ (0.001,0) [0|0] "" Vector__XXX
 SG_ Cell_Voltage_614 : 23|16@0+ (0.001,0) [0|0] "" Vector__XXX
 SG_ Cell_Voltage_615 : 39|16@0+ (0.001,0) [0|0] "" Vector__XXX
 SG_ Cell_Voltage_616 : 55|16@0+ (0.001,0) [0|0] "" Vector__XXX

BO_ 2325962906 wExt_Info_Voltages_155: 8 wBMS
 SG_ Cell_Voltage_617 : 7|16@0+ (0.001,0) [0|0] "" Vector__XXX
 SG_ Cell_Voltage_618 : 23|16@0+ (0.001,0) [0|0] "" Vector__XXX
 SG_ Cell_Voltage_619 : 39|16@0+ (0.001,0) [0|0] "" Vector__XXX
 SG_ Cell_Voltage_620 : 55|16@0+ (0.001,0) [0|0] "" Vector__XXX

BO_ 2325962907 wExt_Info_Voltages_156: 8 wBMS
 SG_ Cell_Voltage_621 : 7|16@0+ (0.001,0) [0|0] "" Vector__XXX
 SG_ Cell_Voltage_622 : 23|16@0+ (0.001,0) [0|0] "" Vector__XXX
 SG_ Cell_Voltage_623 : 39|16@0+ (0.001,0) [0|0] "" Vector__XXX
 SG_ Cell_Voltage_624 : 55|16@0+ (0.001,0) [0|0] "" Vector__XXX

BO_ 2325962908 wExt_Info_Voltages_157: 8 wBMS
 SG_ Cell_Voltage_625 : 7|16@0+ (0.001,0) [0|0] "" Vector__XXX
 SG_ Cell_Voltage_626 : 23|16@0+ (0.001,0) [0|0] "" Vector__XXX
 SG_ Cell_Voltage_627 : 39|16@0+ (0.001,0) [0|0] "" Vector__XXX
 SG_ Cell_Voltage_628 : 55|16@0+ (0.001,0) [0|0] "" Vector__XXX

BO_ 2325962909 wExt_Info_Voltages_158: 8 wBMS
 SG_ Cell_Voltage_629 : 7|16@0+ (0.001,0) [0|0] "" Vector__XXX
 SG_ Cell_Voltage_630 : 23|16@0+ (0.001,0) [0|0] "" Vector__XXX
 SG_ Cell_Voltage_631 : 39|16@0+ (0.001,0) [0|0] "" Vector__XXX
 SG_ Cell_Voltage_632 : 55|16@0+ (0.001,0) [0|0] "" Vector__XXX

BO_ 2325962910 wExt_Info_Voltages_159: 8 wBMS
 SG_ Cell_Voltage_633 : 7|16@0+ (0.001,0) [0|0] "" Vector__XXX
 SG_ Cell_Voltage_634 : 23|16@0+ (0.001,0) [0|0] "" Vector__XXX
 SG_ Cell_Voltage_635 : 39|16@0+ (0.001,0) [0|0] "" Vector__XXX
 SG_ Cell_Voltage_636 : 55|16@0+ (0.001,0) [0|0] "" Vector__XXX

BO_ 2325962911 wExt_Info_Voltages_160: 8 wBMS
 SG_ Cell_Voltage_637 : 7|16@0+ (0.001,0) [0|0] "" Vector__XXX
 SG_ Cell_Voltage_638 : 23|16@0+ (0.001,0) [0|0] "" Vector__XXX
 SG_ Cell_Voltage_639 : 39|16@0+ (0.001,0) [0|0] "" Vector__XXX
 SG_ Cell_Voltage_640 : 55|16@0+ (0.001,0) [0|0] "" Vector__XXX

BO_ 2325962912 wExt_Info_Voltages_161: 8 wBMS
 SG_ Cell_Voltage_641 : 7|16@0+ (0.001,0) [0|0] "" Vector__XXX
 SG_ Cell_Voltage_642 : 23|16@0+ (0.001,0) [0|0] "" Vector__XXX
 SG_ Cell_Voltage_643 : 39|16@0+ (0.001,0) [0|0] "" Vector__XXX
 SG_ Cell_Voltage_644 : 55|16@0+ (0.001,0) [0|0] "" Vector__XXX

BO_ 2325962913 wExt_Info_Voltages_162: 8 wBMS
 SG_ Cell_Voltage_645 : 7|16@0+ (0.001,0) [0|0] "" Vector__XXX
 SG_ Cell_Voltage_646 : 23|16@0+ (0.001,0) [0|0] "" Vector__XXX
 SG_ Cell_Voltage_647 : 39|16@0+ (0.001,0) [0|0] "" Vector__XXX
 SG_ Cell_Voltage_648 : 55|16@0+ (0.001,0) [0|0] "" Vector__XXX

BO_ 2325962914 wExt_Info_Voltages_163: 8 wBMS
 SG_ Cell_Voltage_649 : 7|16@0+ (0.001,0) [0|0] "" Vector__XXX
 SG_ Cell_Voltage_650 : 23|16@0+ (0.001,0) [0|0] "" Vector__XXX
 SG_ Cell_Voltage_651 : 39|16@0+ (0.001,0) [0|0] "" Vector__XXX
 SG_ Cell_Voltage_652 : 55|16@0+ (0.001,0) [0|0] "" Vector__XXX

BO_ 2325962915 wExt_Info_Voltages_164: 8 wBMS
 SG_ Cell_Voltage_653 : 7|16@0+ (0.001,0) [0|0] "" Vector__XXX
 SG_ Cell_Voltage_654 : 23|16@0+ (0.001,0) [0|0] "" Vector__XXX
 SG_ Cell_Voltage_655 : 39|16@0+ (0.001,0) [0|0] "" Vector__XXX
 SG_ Cell_Voltage_656 : 55|16@0+ (0.001,0) [0|0] "" Vector__XXX

BO_ 2325962916 wExt_Info_Voltages_165: 8 wBMS
 SG_ Cell_Voltage_657 : 7|16@0+ (0.001,0) [0|0] "" Vector__XXX
 SG_ Cell_Voltage_658 : 23|16@0+ (0.001,0) [0|0] "" Vector__XXX
 SG_ Cell_Voltage_659 : 39|16@0+ (0.001,0) [0|0] "" Vector__XXX
 SG_ Cell_Voltage_660 : 55|16@0+ (0.001,0) [0|0] "" Vector__XXX

BO_ 2325962917 wExt_Info_Voltages_166: 8 wBMS
 SG_ Cell_Voltage_661 : 7|16@0+ (0.001,0) [0|0] "" Vector__XXX
 SG_ Cell_Voltage_662 : 23|16@0+ (0.001,0) [0|0] "" Vector__XXX
 SG_ Cell_Voltage_663 : 39|16@0+ (0.001,0) [0|0] "" Vector__XXX
 SG_ Cell_Voltage_664 : 55|16@0+ (0.001,0) [0|0] "" Vector__XXX

BO_ 2325962918 wExt_Info_Voltages_167: 8 wBMS
 SG_ Cell_Voltage_665 : 7|16@0+ (0.001,0) [0|0] "" Vector__XXX
 SG_ Cell_Voltage_666 : 23|16@0+ (0.001,0) [0|0] "" Vector__XXX
 SG_ Cell_Voltage_667 : 39|16@0+ (0.001,0) [0|0] "" Vector__XXX
 SG_ Cell_Voltage_668 : 55|16@0+ (0.001,0) [0|0] "" Vector__XXX

BO_ 2325962919 wExt_Info_Voltages_168: 8 wBMS
 SG_ Cell_Voltage_669 : 7|16@0+ (0.001,0) [0|0] "" Vector__XXX
 SG_ Cell_Voltage_670 : 23|16@0+ (0.001,0) [0|0] "" Vector__XXX
 SG_ Cell_Voltage_671 : 39|16@0+ (0.001,0) [0|0] "" Vector__XXX
 SG_ Cell_Voltage_672 : 55|16@0+ (0.001,0) [0|0] "" Vector__XXX

BO_ 2325962920 wExt_Info_Voltages_169: 8 wBMS
 SG_ Cell_Voltage_673 : 7|16@0+ (0.001,0) [0|0] "" Vector__XXX
 SG_ Cell_Voltage_674 : 23|16@0+ (0.001,0) [0|0] "" Vector__XXX
 SG_ Cell_Voltage_675 : 39|16@0+ (0.001,0) [0|0] "" Vector__XXX
 SG_ Cell_Voltage_676 : 55|16@0+ (0.001,0) [0|0] "" Vector__XXX

BO_ 2325962921 wExt_Info_Voltages_170: 8 wBMS
 SG_ Cell_Voltage_677 : 7|16@0+ (0.001,0) [0|0] "" Vector__XXX
 SG_ Cell_Voltage_678 : 23|16@0+ (0.001,0) [0|0] "" Vector__XXX
 SG_ Cell_Voltage_679 : 39|16@0+ (0.001,0) [0|0] "" Vector__XXX
 SG_ Cell_Voltage_680 : 55|16@0+ (0.001,0) [0|0] "" Vector__XXX

BO_ 2325962922 wExt_Info_Voltages_171: 8 wBMS
 SG_ Cell_Voltage_681 : 7|16@0+ (0.001,0) [0|0] "" Vector__XXX
 SG_ Cell_Voltage_682 : 23|16@0+ (0.001,0) [0|0] "" Vector__XXX
 SG_ Cell_Voltage_683 : 39|16@0+ (0.001,0) [0|0] "" Vector__XXX
 SG_ Cell_Voltage_684 : 55|16@0+ (0.001,0) [0|0] "" Vector__XXX

BO_ 2325962923 wExt_Info_Voltages_172: 8 wBMS
 SG_ Cell_Voltage_685 : 7|16@0+ (0.001,0) [0|0] "" Vector__XXX
 SG_ Cell_Voltage_686 : 23|16@0+ (0.001,0) [0|0] "" Vector__XXX
 SG_ Cell_Voltage_687 : 39|16@0+ (0.001,0) [0|0] "" Vector__XXX
 SG_ Cell_Voltage_688 : 55|16@0+ (0.001,0) [0|0] "" Vector__XXX

BO_ 2325962924 wExt_Info_Voltages_173: 8 wBMS
 SG_ Cell_Voltage_689 : 7|16@0+ (0.001,0) [0|0] "" Vector__XXX
 SG_ Cell_Voltage_690 : 23|16@0+ (0.001,0) [0|0] "" Vector__XXX
 SG_ Cell_Voltage_691 : 39|16@0+ (0.001,0) [0|0] "" Vector__XXX
 SG_ Cell_Voltage_692 : 55|16@0+ (0.001,0) [0|0] "" Vector__XXX

BO_ 2325962925 wExt_Info_Voltages_174: 8 wBMS
 SG_ Cell_Voltage_693 : 7|16@0+ (0.001,0) [0|0] "" Vector__XXX
 SG_ Cell_Voltage_694 : 23|16@0+ (0.001,0) [0|0] "" Vector__XXX
 SG_ Cell_Voltage_695 : 39|16@0+ (0.001,0) [0|0] "" Vector__XXX
 SG_ Cell_Voltage_696 : 55|16@0+ (0.001,0) [0|0] "" Vector__XXX

BO_ 2325962926 wExt_Info_Voltages_175: 8 wBMS
 SG_ Cell_Voltage_697 : 7|16@0+ (0.001,0) [0|0] "" Vector__XXX
 SG_ Cell_Voltage_698 : 23|16@0+ (0.001,0) [0|0] "" Vector__XXX
 SG_ Cell_Voltage_699 : 39|16@0+ (0.001,0) [0|0] "" Vector__XXX
 SG_ Cell_Voltage_700 : 55|16@0+ (0.001,0) [0|0] "" Vector__XXX

BO_ 2325962927 wExt_Info_Voltages_176: 8 wBMS
 SG_ Cell_Voltage_701 : 7|16@0+ (0.001,0) [0|0] "" Vector__XXX
 SG_ Cell_Voltage_702 : 23|16@0+ (0.001,0) [0|0] "" Vector__XXX
 SG_ Cell_Voltage_703 : 39|16@0+ (0.001,0) [0|0] "" Vector__XXX
 SG_ Cell_Voltage_704 : 55|16@0+ (0.001,0) [0|0] "" Vector__XXX

BO_ 2325962928 wExt_Info_Voltages_177: 8 wBMS
 SG_ Cell_Voltage_705 : 7|16@0+ (0.001,0) [0|0] "" Vector__XXX
 SG_ Cell_Voltage_706 : 23|16@0+ (0.001,0) [0|0] "" Vector__XXX
 SG_ Cell_Voltage_707 : 39|16@0+ (0.001,0) [0|0] "" Vector__XXX
 SG_ Cell_Voltage_708 : 55|16@0+ (0.001,0) [0|0] "" Vector__XXX

BO_ 2325962929 wExt_Info_Voltages_178: 8 wBMS
 SG_ Cell_Voltage_709 : 7|16@0+ (0.001,0) [0|0] "" Vector__XXX
 SG_ Cell_Voltage_710 : 23|16@0+ (0.001,0) [0|0] "" Vector__XXX
 SG_ Cell_Voltage_711 : 39|16@0+ (0.001,0) [0|0] "" Vector__XXX
 SG_ Cell_Voltage_712 : 55|16@0+ (0.001,0) [0|0] "" Vector__XXX

BO_ 2325962930 wExt_Info_Voltages_179: 8 wBMS
 SG_ Cell_Voltage_713 : 7|16@0+ (0.001,0) [0|0] "" Vector__XXX
 SG_ Cell_Voltage_714 : 23|16@0+ (0.001,0) [0|0] "" Vector__XXX
 SG_ Cell_Voltage_715 : 39|16@0+ (0.001,0) [0|0] "" Vector__XXX
 SG_ Cell_Voltage_716 : 55|16@0+ (0.001,0) [0|0] "" Vector__XXX

BO_ 2325962931 wExt_Info_Voltages_180: 8 wBMS
 SG_ Cell_Voltage_717 : 7|16@0+ (0.001,0) [0|0] "" Vector__XXX
 SG_ Cell_Voltage_718 : 23|16@0+ (0.001,0) [0|0] "" Vector__XXX
 SG_ Cell_Voltage_719 : 39|16@0+ (0.001,0) [0|0] "" Vector__XXX
 SG_ Cell_Voltage_720 : 55|16@0+ (0.001,0) [0|0] "" Vector__XXX

BO_ 2325962932 wExt_Info_Voltages_181: 8 wBMS
 SG_ Cell_Voltage_721 : 7|16@0+ (0.001,0) [0|0] "" Vector__XXX
 SG_ Cell_Voltage_722 : 23|16@0+ (0.001,0) [0|0] "" Vector__XXX
 SG_ Cell_Voltage_723 : 39|16@0+ (0.001,0) [0|0] "" Vector__XXX
 SG_ Cell_Voltage_724 : 55|16@0+ (0.001,0) [0|0] "" Vector__XXX

BO_ 2325962933 wExt_Info_Voltages_182: 8 wBMS
 SG_ Cell_Voltage_725 : 7|16@0+ (0.001,0) [0|0] "" Vector__XXX
 SG_ Cell_Voltage_726 : 23|16@0+ (0.001,0) [0|0] "" Vector__XXX
 SG_ Cell_Voltage_727 : 39|16@0+ (0.001,0) [0|0] "" Vector__XXX
 SG_ Cell_Voltage_728 : 55|16@0+ (0.001,0) [0|0] "" Vector__XXX

BO_ 2325962934 wExt_Info_Voltages_183: 8 wBMS
 SG_ Cell_Voltage_729 : 7|16@0+ (0.001,0) [0|0] "" Vector__XXX
 SG_ Cell_Voltage_730 : 23|16@0+ (0.001,0) [0|0] "" Vector__XXX
 SG_ Cell_Voltage_731 : 39|16@0+ (0.001,0) [0|0] "" Vector__XXX
 SG_ Cell_Voltage_732 : 55|16@0+ (0.001,0) [0|0] "" Vector__XXX

BO_ 2325962935 wExt_Info_Voltages_184: 8 wBMS
 SG_ Cell_Voltage_733 : 7|16@0+ (0.001,0) [0|0] "" Vector__XXX
 SG_ Cell_Voltage_734 : 23|16@0+ (0.001,0) [0|0] "" Vector__XXX
 SG_ Cell_Voltage_735 : 39|16@0+ (0.001,0) [0|0] "" Vector__XXX
 SG_ Cell_Voltage_736 : 55|16@0+ (0.001,0) [0|0] "" Vector__XXX

BO_ 2325962936 wExt_Info_Voltages_185: 8 wBMS
 SG_ Cell_Voltage_737 : 7|16@0+ (0.001,0) [0|0] "" Vector__XXX
 SG_ Cell_Voltage_738 : 23|16@0+ (0.001,0) [0|0] "" Vector__XXX
 SG_ Cell_Voltage_739 : 39|16@0+ (0.001,0) [0|0] "" Vector__XXX
 SG_ Cell_Voltage_740 : 55|16@0+ (0.001,0) [0|0] "" Vector__XXX

BO_ 2325962937 wExt_Info_Voltages_186: 8 wBMS
 SG_ Cell_Voltage_741 : 7|16@0+ (0.001,0) [0|0] "" Vector__XXX
 SG_ Cell_Voltage_742 : 23|16@0+ (0.001,0) [0|0] "" Vector__XXX
 SG_ Cell_Voltage_743 : 39|16@0+ (0.001,0) [0|0] "" Vector__XXX
 SG_ Cell_Voltage_744 : 55|16@0+ (0.001,0) [0|0] "" Vector__XXX

BO_ 2325962938 wExt_Info_Voltages_187: 8 wBMS
 SG_ Cell_Voltage_745 : 7|16@0+ (0.001,0) [0|0] "" Vector__XXX
 SG_ Cell_Voltage_746 : 23|16@0+ (0.001,0) [0|0] "" Vector__XXX
 SG_ Cell_Voltage_747 : 39|16@0+ (0.001,0) [0|0] "" Vector__XXX
 SG_ Cell_Voltage_748 : 55|16@0+ (0.001,0) [0|0] "" Vector__XXX

BO_ 2325962939 wExt_Info_Voltages_188: 8 wBMS
 SG_ Cell_Voltage_749 : 7|16@0+ (0.001,0) [0|0] "" Vector__XXX
 SG_ Cell_Voltage_750 : 23|16@0+ (0.001,0) [0|0] "" Vector__XXX
 SG_ Cell_Voltage_751 : 39|16@0+ (0.001,0) [0|0] "" Vector__XXX
 SG_ Cell_Voltage_752 : 55|16@0+ (0.001,0) [0|0] "" Vector__XXX

BO_ 2325962940 wExt_Info_Voltages_189: 8 wBMS
 SG_ Cell_Voltage_753 : 7|16@0+ (0.001,0) [0|0] "" Vector__XXX
 SG_ Cell_Voltage_754 : 23|16@0+ (0.001,0) [0|0] "" Vector__XXX
 SG_ Cell_Voltage_755 : 39|16@0+ (0.001,0) [0|0] "" Vector__XXX
 SG_ Cell_Voltage_756 : 55|16@0+ (0.001,0) [0|0] "" Vector__XXX

BO_ 2325962941 wExt_Info_Voltages_190: 8 wBMS
 SG_ Cell_Voltage_757 : 7|16@0+ (0.001,0) [0|0] "" Vector__XXX
 SG_ Cell_Voltage_758 : 23|16@0+ (0.001,0) [0|0] "" Vector__XXX
 SG_ Cell_Voltage_759 : 39|16@0+ (0.001,0) [0|0] "" Vector__XXX
 SG_ Cell_Voltage_760 : 55|16@0+ (0.001,0) [0|0] "" Vector__XXX

BO_ 2325962942 wExt_Info_Voltages_191: 8 wBMS
 SG_ Cell_Voltage_761 : 7|16@0+ (0.001,0) [0|0] "" Vector__XXX
 SG_ Cell_Voltage_762 : 23|16@0+ (0.001,0) [0|0] "" Vector__XXX
 SG_ Cell_Voltage_763 : 39|16@0+ (0.001,0) [0|0] "" Vector__XXX
 SG_ Cell_Voltage_764 : 55|16@0+ (0.001,0) [0|0] "" Vector__XXX

BO_ 2325962943 wExt_Info_Voltages_192: 8 wBMS
 SG_ Cell_Voltage_765 : 7|16@0+ (0.001,0) [0|0] "" Vector__XXX
 SG_ Cell_Voltage_766 : 23|16@0+ (0.001,0) [0|0] "" Vector__XXX
 SG_ Cell_Voltage_767 : 39|16@0+ (0.001,0) [0|0] "" Vector__XXX
 SG_ Cell_Voltage_768 : 55|16@0+ (0.001,0) [0|0] "" Vector__XXX

BO_ 2325962944 wExt_Info_Voltages_193: 8 wBMS
 SG_ Cell_Voltage_769 : 7|16@0+ (0.001,0) [0|0] "" Vector__XXX
 SG_ Cell_Voltage_770 : 23|16@0+ (0.001,0) [0|0] "" Vector__XXX
 SG_ Cell_Voltage_771 : 39|16@0+ (0.001,0) [0|0] "" Vector__XXX
 SG_ Cell_Voltage_772 : 55|16@0+ (0.001,0) [0|0] "" Vector__XXX

BO_ 2325962945 wExt_Info_Voltages_194: 8 wBMS
 SG_ Cell_Voltage_773 : 7|16@0+ (0.001,0) [0|0] "" Vector__XXX
 SG_ Cell_Voltage_774 : 23|16@0+ (0.001,0) [0|0] "" Vector__XXX
 SG_ Cell_Voltage_775 : 39|16@0+ (0.001,0) [0|0] "" Vector__XXX
 SG_ Cell_Voltage_776 : 55|16@0+ (0.001,0) [0|0] "" Vector__XXX

BO_ 2325962946 wExt_Info_Voltages_195: 8 wBMS
 SG_ Cell_Voltage_777 : 7|16@0+ (0.001,0) [0|0] "" Vector__XXX
 SG_ Cell_Voltage_778 : 23|16@0+ (0.001,0) [0|0] "" Vector__XXX
 SG_ Cell_Voltage_779 : 39|16@0+ (0.001,0) [0|0] "" Vector__XXX
 SG_ Cell_Voltage_780 : 55|16@0+ (0.001,0) [0|0] "" Vector__XXX

BO_ 2325962947 wExt_Info_Voltages_196: 8 wBMS
 SG_ Cell_Voltage_781 : 7|16@0+ (0.001,0) [0|0] "" Vector__XXX
 SG_ Cell_Voltage_782 : 23|16@0+ (0.001,0) [0|0] "" Vector__XXX
 SG_ Cell_Voltage_783 : 39|16@0+ (0.001,0) [0|0] "" Vector__XXX
 SG_ Cell_Voltage_784 : 55|16@0+ (0.001,0) [0|0] "" Vector__XXX

BO_ 2325962948 wExt_Info_Voltages_197: 8 wBMS
 SG_ Cell_Voltage_785 : 7|16@0+ (0.001,0) [0|0] "" Vector__XXX
 SG_ Cell_Voltage_786 : 23|16@0+ (0.001,0) [0|0] "" Vector__XXX
 SG_ Cell_Voltage_787 : 39|16@0+ (0.001,0) [0|0] "" Vector__XXX
 SG_ Cell_Voltage_788 : 55|16@0+ (0.001,0) [0|0] "" Vector__XXX

BO_ 2325962949 wExt_Info_Voltages_198: 8 wBMS
 SG_ Cell_Voltage_789 : 7|16@0+ (0.001,0) [0|0] "" Vector__XXX
 SG_ Cell_Voltage_790 : 23|16@0+ (0.001,0) [0|0] "" Vector__XXX
 SG_ Cell_Voltage_791 : 39|16@0+ (0.001,0) [0|0] "" Vector__XXX
 SG_ Cell_Voltage_792 : 55|16@0+ (0.001,0) [0|0] "" Vector__XXX

BO_ 2325962950 wExt_Info_Voltages_199: 8 wBMS
 SG_ Cell_Voltage_793 : 7|16@0+ (0.001,0) [0|0] "" Vector__XXX
 SG_ Cell_Voltage_794 : 23|16@0+ (0.001,0) [0|0] "" Vector__XXX
 SG_ Cell_Voltage_795 : 39|16@0+ (0.001,0) [0|0] "" Vector__XXX
 SG_ Cell_Voltage_796 : 55|16@0+ (0.001,0) [0|0] "" Vector__XXX

BO_ 2325962951 wExt_Info_Voltages_200: 8 wBMS
 SG_ Cell_Voltage_797 : 7|16@0+ (0.001,0) [0|0] "" Vector__XXX
 SG_ Cell_Voltage_798 : 23|16@0+ (0.001,0) [0|0] "" Vector__XXX
 SG_ Cell_Voltage_799 : 39|16@0+ (0.001,0) [0|0] "" Vector__XXX
 SG_ Cell_Voltage_800 : 55|16@0+ (0.001,0) [0|0] "" Vector__XXX

BO_ 2325962952 wExt_Info_Voltages_201: 8 wBMS
 SG_ Cell_Voltage_801 : 7|16@0+ (0.001,0) [0|0] "" Vector__XXX
 SG_ Cell_Voltage_802 : 23|16@0+ (0.001,0) [0|0] "" Vector__XXX
 SG_ Cell_Voltage_803 : 39|16@0+ (0.001,0) [0|0] "" Vector__XXX
 SG_ Cell_Voltage_804 : 55|16@0+ (0.001,0) [0|0] "" Vector__XXX

BO_ 2325962953 wExt_Info_Voltages_202: 8 wBMS
 SG_ Cell_Voltage_805 : 7|16@0+ (0.001,0) [0|0] "" Vector__XXX
 SG_ Cell_Voltage_806 : 23|16@0+ (0.001,0) [0|0] "" Vector__XXX
 SG_ Cell_Voltage_807 : 39|16@0+ (0.001,0) [0|0] "" Vector__XXX
 SG_ Cell_Voltage_808 : 55|16@0+ (0.001,0) [0|0] "" Vector__XXX

BO_ 2325962954 wExt_Info_Voltages_203: 8 wBMS
 SG_ Cell_Voltage_809 : 7|16@0+ (0.001,0) [0|0] "" Vector__XXX
 SG_ Cell_Voltage_810 : 23|16@0+ (0.001,0) [0|0] "" Vector__XXX
 SG_ Cell_Voltage_811 : 39|16@0+ (0.001,0) [0|0] "" Vector__XXX
 SG_ Cell_Voltage_812 : 55|16@0+ (0.001,0) [0|0] "" Vector__XXX

BO_ 2325962955 wExt_Info_Voltages_204: 8 wBMS
 SG_ Cell_Voltage_813 : 7|16@0+ (0.001,0) [0|0] "" Vector__XXX
 SG_ Cell_Voltage_814 : 23|16@0+ (0.001,0) [0|0] "" Vector__XXX
 SG_ Cell_Voltage_815 : 39|16@0+ (0.001,0) [0|0] "" Vector__XXX
 SG_ Cell_Voltage_816 : 55|16@0+ (0.001,0) [0|0] "" Vector__XXX

BO_ 2325962956 wExt_Info_Voltages_205: 8 wBMS
 SG_ Cell_Voltage_817 : 7|16@0+ (0.001,0) [0|0] "" Vector__XXX
 SG_ Cell_Voltage_818 : 23|16@0+ (0.001,0) [0|0] "" Vector__XXX
 SG_ Cell_Voltage_819 : 39|16@0+ (0.001,0) [0|0] "" Vector__XXX
 SG_ Cell_Voltage_820 : 55|16@0+ (0.001,0) [0|0] "" Vector__XXX

BO_ 2325962957 wExt_Info_Voltages_206: 8 wBMS
 SG_ Cell_Voltage_821 : 7|16@0+ (0.001,0) [0|0] "" Vector__XXX
 SG_ Cell_Voltage_822 : 23|16@0+ (0.001,0) [0|0] "" Vector__XXX
 SG_ Cell_Voltage_823 : 39|16@0+ (0.001,0) [0|0] "" Vector__XXX
 SG_ Cell_Voltage_824 : 55|16@0+ (0.001,0) [0|0] "" Vector__XXX

BO_ 2325962958 wExt_Info_Voltages_207: 8 wBMS
 SG_ Cell_Voltage_825 : 7|16@0+ (0.001,0) [0|0] "" Vector__XXX
 SG_ Cell_Voltage_826 : 23|16@0+ (0.001,0) [0|0] "" Vector__XXX
 SG_ Cell_Voltage_827 : 39|16@0+ (0.001,0) [0|0] "" Vector__XXX
 SG_ Cell_Voltage_828 : 55|16@0+ (0.001,0) [0|0] "" Vector__XXX

BO_ 2325962959 wExt_Info_Voltages_208: 8 wBMS
 SG_ Cell_Voltage_829 : 7|16@0+ (0.001,0) [0|0] "" Vector__XXX
 SG_ Cell_Voltage_830 : 23|16@0+ (0.001,0) [0|0] "" Vector__XXX
 SG_ Cell_Voltage_831 : 39|16@0+ (0.001,0) [0|0] "" Vector__XXX
 SG_ Cell_Voltage_832 : 55|16@0+ (0.001,0) [0|0] "" Vector__XXX

BO_ 2325962960 wExt_Info_Voltages_209: 8 wBMS
 SG_ Cell_Voltage_833 : 7|16@0+ (0.001,0) [0|0] "" Vector__XXX
 SG_ Cell_Voltage_834 : 23|16@0+ (0.001,0) [0|0] "" Vector__XXX
 SG_ Cell_Voltage_835 : 39|16@0+ (0.001,0) [0|0] "" Vector__XXX
 SG_ Cell_Voltage_836 : 55|16@0+ (0.001,0) [0|0] "" Vector__XXX

BO_ 2325962961 wExt_Info_Voltages_210: 8 wBMS
 SG_ Cell_Voltage_837 : 7|16@0+ (0.001,0) [0|0] "" Vector__XXX
 SG_ Cell_Voltage_838 : 23|16@0+ (0.001,0) [0|0] "" Vector__XXX
 SG_ Cell_Voltage_839 : 39|16@0+ (0.001,0) [0|0] "" Vector__XXX
 SG_ Cell_Voltage_840 : 55|16@0+ (0.001,0) [0|0] "" Vector__XXX

BO_ 2325962962 wExt_Info_Voltages_211: 8 wBMS
 SG_ Cell_Voltage_841 : 7|16@0+ (0.001,0) [0|0] "" Vector__XXX
 SG_ Cell_Voltage_842 : 23|16@0+ (0.001,0) [0|0] "" Vector__XXX
 SG_ Cell_Voltage_843 : 39|16@0+ (0.001,0) [0|0] "" Vector__XXX
 SG_ Cell_Voltage_844 : 55|16@0+ (0.001,0) [0|0] "" Vector__XXX

BO_ 2325962963 wExt_Info_Voltages_212: 8 wBMS
 SG_ Cell_Voltage_845 : 7|16@0+ (0.001,0) [0|0] "" Vector__XXX
 SG_ Cell_Voltage_846 : 23|16@0+ (0.001,0) [0|0] "" Vector__XXX
 SG_ Cell_Voltage_847 : 39|16@0+ (0.001,0) [0|0] "" Vector__XXX
 SG_ Cell_Voltage_848 : 55|16@0+ (0.001,0) [0|0] "" Vector__XXX

BO_ 2325962964 wExt_Info_Voltages_213: 8 wBMS
 SG_ Cell_Voltage_849 : 7|16@0+ (0.001,0) [0|0] "" Vector__XXX
 SG_ Cell_Voltage_850 : 23|16@0+ (0.001,0) [0|0] "" Vector__XXX
 SG_ Cell_Voltage_851 : 39|16@0+ (0.001,0) [0|0] "" Vector__XXX
 SG_ Cell_Voltage_852 : 55|16@0+ (0.001,0) [0|0] "" Vector__XXX

BO_ 2325962965 wExt_Info_Voltages_214: 8 wBMS
 SG_ Cell_Voltage_853 : 7|16@0+ (0.001,0) [0|0] "" Vector__XXX
 SG_ Cell_Voltage_854 : 23|16@0+ (0.001,0) [0|0] "" Vector__XXX
 SG_ Cell_Voltage_855 : 39|16@0+ (0.001,0) [0|0] "" Vector__XXX
 SG_ Cell_Voltage_856 : 55|16@0+ (0.001,0) [0|0] "" Vector__XXX

BO_ 2325962966 wExt_Info_Voltages_215: 8 wBMS
 SG_ Cell_Voltage_857 : 7|16@0+ (0.001,0) [0|0] "" Vector__XXX
 SG_ Cell_Voltage_858 : 23|16@0+ (0.001,0) [0|0] "" Vector__XXX
 SG_ Cell_Voltage_859 : 39|16@0+ (0.001,0) [0|0] "" Vector__XXX
 SG_ Cell_Voltage_860 : 55|16@0+ (0.001,0) [0|0] "" Vector__XXX

BO_ 2325962967 wExt_Info_Voltages_216: 8 wBMS
 SG_ Cell_Voltage_861 : 7|16@0+ (0.001,0) [0|0] "" Vector__XXX
 SG_ Cell_Voltage_662 : 23|16@0+ (0.001,0) [0|0] "" Vector__XXX
 SG_ Cell_Voltage_863 : 39|16@0+ (0.001,0) [0|0] "" Vector__XXX
 SG_ Cell_Voltage_864 : 55|16@0+ (0.001,0) [0|0] "" Vector__XXX

BO_ 2327011328 wExt_Info_Temperatures_01: 8 wBMS
 SG_ Cell_Temperature_001 : 7|16@0- (0.01,0) [0|0] "ºC" Vector__XXX
 SG_ Cell_Temperature_002 : 23|16@0- (0.01,0) [0|0] "ºC" Vector__XXX
 SG_ Cell_Temperature_003 : 39|16@0- (0.01,0) [0|0] "ºC" Vector__XXX
 SG_ Cell_Temperature_004 : 55|16@0- (0.01,0) [0|0] "ºC" Vector__XXX

BO_ 2327011329 wExt_Info_Temperatures_02: 8 wBMS
 SG_ Cell_Temperature_005 : 7|16@0- (0.01,0) [0|0] "ºC" Vector__XXX
 SG_ Cell_Temperature_006 : 23|16@0- (0.01,0) [0|0] "ºC" Vector__XXX
 SG_ Cell_Temperature_007 : 39|16@0- (0.01,0) [0|0] "ºC" Vector__XXX
 SG_ Cell_Temperature_008 : 55|16@0- (0.01,0) [0|0] "ºC" Vector__XXX

BO_ 2327011330 wExt_Info_Temperatures_03: 8 wBMS
 SG_ Cell_Temperature_009 : 7|16@0- (0.01,0) [0|0] "ºC" Vector__XXX
 SG_ Cell_Temperature_010 : 23|16@0- (0.01,0) [0|0] "ºC" Vector__XXX
 SG_ Cell_Temperature_011 : 39|16@0- (0.01,0) [0|0] "ºC" Vector__XXX
 SG_ Cell_Temperature_012 : 55|16@0- (0.01,0) [0|0] "ºC" Vector__XXX

BO_ 2327011331 wExt_Info_Temperatures_04: 8 wBMS
 SG_ Cell_Temperature_013 : 7|16@0- (0.01,0) [0|0] "ºC" Vector__XXX
 SG_ Cell_Temperature_014 : 23|16@0- (0.01,0) [0|0] "ºC" Vector__XXX
 SG_ Cell_Temperature_015 : 39|16@0- (0.01,0) [0|0] "ºC" Vector__XXX
 SG_ Cell_Temperature_016 : 55|16@0- (0.01,0) [0|0] "ºC" Vector__XXX

BO_ 2327011332 wExt_Info_Temperatures_05: 8 wBMS
 SG_ Cell_Temperature_017 : 7|16@0- (0.01,0) [0|0] "ºC" Vector__XXX
 SG_ Cell_Temperature_018 : 23|16@0- (0.01,0) [0|0] "ºC" Vector__XXX
 SG_ Cell_Temperature_019 : 39|16@0- (0.01,0) [0|0] "ºC" Vector__XXX
 SG_ Cell_Temperature_020 : 55|16@0- (0.01,0) [0|0] "ºC" Vector__XXX

BO_ 2327011333 wExt_Info_Temperatures_06: 8 wBMS
 SG_ Cell_Temperature_021 : 7|16@0- (0.01,0) [0|0] "ºC" Vector__XXX
 SG_ Cell_Temperature_022 : 23|16@0- (0.01,0) [0|0] "ºC" Vector__XXX
 SG_ Cell_Temperature_023 : 39|16@0- (0.01,0) [0|0] "ºC" Vector__XXX
 SG_ Cell_Temperature_024 : 55|16@0- (0.01,0) [0|0] "ºC" Vector__XXX

BO_ 2327011334 wExt_Info_Temperatures_07: 8 wBMS
 SG_ Cell_Temperature_025 : 7|16@0- (0.01,0) [0|0] "ºC" Vector__XXX
 SG_ Cell_Temperature_026 : 23|16@0- (0.01,0) [0|0] "ºC" Vector__XXX
 SG_ Cell_Temperature_027 : 39|16@0- (0.01,0) [0|0] "ºC" Vector__XXX
 SG_ Cell_Temperature_028 : 55|16@0- (0.01,0) [0|0] "ºC" Vector__XXX

BO_ 2327011335 wExt_Info_Temperatures_08: 8 wBMS
 SG_ Cell_Temperature_029 : 7|16@0- (0.01,0) [0|0] "ºC" Vector__XXX
 SG_ Cell_Temperature_030 : 23|16@0- (0.01,0) [0|0] "ºC" Vector__XXX
 SG_ Cell_Temperature_031 : 39|16@0- (0.01,0) [0|0] "ºC" Vector__XXX
 SG_ Cell_Temperature_032 : 55|16@0- (0.01,0) [0|0] "ºC" Vector__XXX

BO_ 2327011336 wExt_Info_Temperatures_09: 8 wBMS
 SG_ Cell_Temperature_033 : 7|16@0- (0.01,0) [0|0] "ºC" Vector__XXX
 SG_ Cell_Temperature_034 : 23|16@0- (0.01,0) [0|0] "ºC" Vector__XXX
 SG_ Cell_Temperature_035 : 39|16@0- (0.01,0) [0|0] "ºC" Vector__XXX
 SG_ Cell_Temperature_036 : 55|16@0- (0.01,0) [0|0] "ºC" Vector__XXX

BO_ 2327011337 wExt_Info_Temperatures_10: 8 wBMS
 SG_ Cell_Temperature_037 : 7|16@0- (0.01,0) [0|0] "ºC" Vector__XXX
 SG_ Cell_Temperature_038 : 23|16@0- (0.01,0) [0|0] "ºC" Vector__XXX
 SG_ Cell_Temperature_039 : 39|16@0- (0.01,0) [0|0] "ºC" Vector__XXX
 SG_ Cell_Temperature_040 : 55|16@0- (0.01,0) [0|0] "ºC" Vector__XXX

BO_ 2327011338 wExt_Info_Temperatures_11: 8 wBMS
 SG_ Cell_Temperature_041 : 7|16@0- (0.01,0) [0|0] "ºC" Vector__XXX
 SG_ Cell_Temperature_042 : 23|16@0- (0.01,0) [0|0] "ºC" Vector__XXX
 SG_ Cell_Temperature_043 : 39|16@0- (0.01,0) [0|0] "ºC" Vector__XXX
 SG_ Cell_Temperature_044 : 55|16@0- (0.01,0) [0|0] "ºC" Vector__XXX

BO_ 2327011339 wExt_Info_Temperatures_12: 8 wBMS
 SG_ Cell_Temperature_045 : 7|16@0- (0.01,0) [0|0] "ºC" Vector__XXX
 SG_ Cell_Temperature_046 : 23|16@0- (0.01,0) [0|0] "ºC" Vector__XXX
 SG_ Cell_Temperature_047 : 39|16@0- (0.01,0) [0|0] "ºC" Vector__XXX
 SG_ Cell_Temperature_048 : 55|16@0- (0.01,0) [0|0] "ºC" Vector__XXX

BO_ 2327011340 wExt_Info_Temperatures_13: 8 wBMS
 SG_ Cell_Temperature_049 : 7|16@0- (0.01,0) [0|0] "ºC" Vector__XXX
 SG_ Cell_Temperature_050 : 23|16@0- (0.01,0) [0|0] "ºC" Vector__XXX
 SG_ Cell_Temperature_051 : 39|16@0- (0.01,0) [0|0] "ºC" Vector__XXX
 SG_ Cell_Temperature_052 : 55|16@0- (0.01,0) [0|0] "ºC" Vector__XXX

BO_ 2327011341 wExt_Info_Temperatures_14: 8 wBMS
 SG_ Cell_Temperature_053 : 7|16@0- (0.01,0) [0|0] "ºC" Vector__XXX
 SG_ Cell_Temperature_054 : 23|16@0- (0.01,0) [0|0] "ºC" Vector__XXX
 SG_ Cell_Temperature_055 : 39|16@0- (0.01,0) [0|0] "ºC" Vector__XXX
 SG_ Cell_Temperature_056 : 55|16@0- (0.01,0) [0|0] "ºC" Vector__XXX

BO_ 2327011342 wExt_Info_Temperatures_15: 8 wBMS
 SG_ Cell_Temperature_057 : 7|16@0- (0.01,0) [0|0] "ºC" Vector__XXX
 SG_ Cell_Temperature_058 : 23|16@0- (0.01,0) [0|0] "ºC" Vector__XXX
 SG_ Cell_Temperature_059 : 39|16@0- (0.01,0) [0|0] "ºC" Vector__XXX
 SG_ Cell_Temperature_060 : 55|16@0- (0.01,0) [0|0] "ºC" Vector__XXX

BO_ 2327011343 wExt_Info_Temperatures_16: 8 wBMS
 SG_ Cell_Temperature_061 : 7|16@0- (0.01,0) [0|0] "ºC" Vector__XXX
 SG_ Cell_Temperature_062 : 23|16@0- (0.01,0) [0|0] "ºC" Vector__XXX
 SG_ Cell_Temperature_063 : 39|16@0- (0.01,0) [0|0] "ºC" Vector__XXX
 SG_ Cell_Temperature_064 : 55|16@0- (0.01,0) [0|0] "ºC" Vector__XXX

BO_ 2327011344 wExt_Info_Temperatures_17: 8 wBMS
 SG_ Cell_Temperature_065 : 7|16@0- (0.01,0) [0|0] "ºC" Vector__XXX
 SG_ Cell_Temperature_066 : 23|16@0- (0.01,0) [0|0] "ºC" Vector__XXX
 SG_ Cell_Temperature_067 : 39|16@0- (0.01,0) [0|0] "ºC" Vector__XXX
 SG_ Cell_Temperature_068 : 55|16@0- (0.01,0) [0|0] "ºC" Vector__XXX

BO_ 2327011345 wExt_Info_Temperatures_18: 8 wBMS
 SG_ Cell_Temperature_069 : 7|16@0- (0.01,0) [0|0] "ºC" Vector__XXX
 SG_ Cell_Temperature_070 : 23|16@0- (0.01,0) [0|0] "ºC" Vector__XXX
 SG_ Cell_Temperature_071 : 39|16@0- (0.01,0) [0|0] "ºC" Vector__XXX
 SG_ Cell_Temperature_072 : 55|16@0- (0.01,0) [0|0] "ºC" Vector__XXX

BO_ 2327011346 wExt_Info_Temperatures_19: 8 wBMS
 SG_ Cell_Temperature_073 : 7|16@0- (0.01,0) [0|0] "" Vector__XXX
 SG_ Cell_Temperature_074 : 23|16@0- (0.01,0) [0|0] "" Vector__XXX
 SG_ Cell_Temperature_075 : 39|16@0- (0.01,0) [0|0] "" Vector__XXX
 SG_ Cell_Temperature_076 : 55|16@0- (0.01,0) [0|0] "" Vector__XXX

BO_ 2327011347 wExt_Info_Temperatures_20: 8 wBMS
 SG_ Cell_Temperature_077 : 7|16@0- (0.01,0) [0|0] "" Vector__XXX
 SG_ Cell_Temperature_078 : 23|16@0- (0.01,0) [0|0] "" Vector__XXX
 SG_ Cell_Temperature_079 : 39|16@0- (0.01,0) [0|0] "" Vector__XXX
 SG_ Cell_Temperature_080 : 55|16@0- (0.01,0) [0|0] "" Vector__XXX

BO_ 2327011348 wExt_Info_Temperatures_21: 8 wBMS
 SG_ Cell_Temperature_081 : 7|16@0- (0.01,0) [0|0] "" Vector__XXX
 SG_ Cell_Temperature_082 : 23|16@0- (0.01,0) [0|0] "" Vector__XXX
 SG_ Cell_Temperature_083 : 39|16@0- (0.01,0) [0|0] "" Vector__XXX
 SG_ Cell_Temperature_084 : 55|16@0- (0.01,0) [0|0] "" Vector__XXX

BO_ 2327011349 wExt_Info_Temperatures_22: 8 wBMS
 SG_ Cell_Temperature_085 : 7|16@0- (0.01,0) [0|0] "" Vector__XXX
 SG_ Cell_Temperature_086 : 23|16@0- (0.01,0) [0|0] "" Vector__XXX
 SG_ Cell_Temperature_087 : 39|16@0- (0.01,0) [0|0] "" Vector__XXX
 SG_ Cell_Temperature_088 : 55|16@0- (0.01,0) [0|0] "" Vector__XXX

BO_ 2327011350 wExt_Info_Temperatures_23: 8 wBMS
 SG_ Cell_Temperature_089 : 7|16@0- (0.01,0) [0|0] "" Vector__XXX
 SG_ Cell_Temperature_090 : 23|16@0- (0.01,0) [0|0] "" Vector__XXX
 SG_ Cell_Temperature_091 : 39|16@0- (0.01,0) [0|0] "" Vector__XXX
 SG_ Cell_Temperature_092 : 55|16@0- (0.01,0) [0|0] "" Vector__XXX

BO_ 2327011351 wExt_Info_Temperatures_24: 8 wBMS
 SG_ Cell_Temperature_093 : 7|16@0- (0.01,0) [0|0] "" Vector__XXX
 SG_ Cell_Temperature_094 : 23|16@0- (0.01,0) [0|0] "" Vector__XXX
 SG_ Cell_Temperature_095 : 39|16@0- (0.01,0) [0|0] "" Vector__XXX
 SG_ Cell_Temperature_096 : 55|16@0- (0.01,0) [0|0] "" Vector__XXX

BO_ 2327011352 wExt_Info_Temperatures_25: 8 wBMS
 SG_ Cell_Temperature_097 : 7|16@0- (0.01,0) [0|0] "" Vector__XXX
 SG_ Cell_Temperature_098 : 23|16@0- (0.01,0) [0|0] "" Vector__XXX
 SG_ Cell_Temperature_099 : 39|16@0- (0.01,0) [0|0] "" Vector__XXX
 SG_ Cell_Temperature_100 : 55|16@0- (0.01,0) [0|0] "" Vector__XXX

BO_ 2327011353 wExt_Info_Temperatures_26: 8 wBMS
 SG_ Cell_Temperature_101 : 7|16@0- (0.01,0) [0|0] "" Vector__XXX
 SG_ Cell_Temperature_102 : 23|16@0- (0.01,0) [0|0] "" Vector__XXX
 SG_ Cell_Temperature_103 : 39|16@0- (0.01,0) [0|0] "" Vector__XXX
 SG_ Cell_Temperature_104 : 55|16@0- (0.01,0) [0|0] "" Vector__XXX

BO_ 2327011354 wExt_Info_Temperatures_27: 8 wBMS
 SG_ Cell_Temperature_105 : 7|16@0- (0.01,0) [0|0] "" Vector__XXX
 SG_ Cell_Temperature_106 : 23|16@0- (0.01,0) [0|0] "" Vector__XXX
 SG_ Cell_Temperature_107 : 39|16@0- (0.01,0) [0|0] "" Vector__XXX
 SG_ Cell_Temperature_108 : 55|16@0- (0.01,0) [0|0] "" Vector__XXX

BO_ 2327011355 wExt_Info_Temperatures_28: 8 wBMS
 SG_ Cell_Temperature_109 : 7|16@0- (0.01,0) [0|0] "" Vector__XXX
 SG_ Cell_Temperature_110 : 23|16@0- (0.01,0) [0|0] "" Vector__XXX
 SG_ Cell_Temperature_111 : 39|16@0- (0.01,0) [0|0] "" Vector__XXX
 SG_ Cell_Temperature_112 : 55|16@0- (0.01,0) [0|0] "" Vector__XXX

BO_ 2327011356 wExt_Info_Temperatures_29: 8 wBMS
 SG_ Cell_Temperature_113 : 7|16@0- (0.01,0) [0|0] "" Vector__XXX
 SG_ Cell_Temperature_114 : 23|16@0- (0.01,0) [0|0] "" Vector__XXX
 SG_ Cell_Temperature_115 : 39|16@0- (0.01,0) [0|0] "" Vector__XXX
 SG_ Cell_Temperature_116 : 55|16@0- (0.01,0) [0|0] "" Vector__XXX

BO_ 2327011357 wExt_Info_Temperatures_30: 8 wBMS
 SG_ Cell_Temperature_117 : 7|16@0- (0.01,0) [0|0] "" Vector__XXX
 SG_ Cell_Temperature_118 : 23|16@0- (0.01,0) [0|0] "" Vector__XXX
 SG_ Cell_Temperature_119 : 39|16@0- (0.01,0) [0|0] "" Vector__XXX
 SG_ Cell_Temperature_120 : 55|16@0- (0.01,0) [0|0] "" Vector__XXX

BO_ 2327011358 wExt_Info_Temperatures_31: 8 wBMS
 SG_ Cell_Temperature_121 : 7|16@0- (0.01,0) [0|0] "" Vector__XXX
 SG_ Cell_Temperature_122 : 23|16@0- (0.01,0) [0|0] "" Vector__XXX
 SG_ Cell_Temperature_123 : 39|16@0- (0.01,0) [0|0] "" Vector__XXX
 SG_ Cell_Temperature_124 : 55|16@0- (0.01,0) [0|0] "" Vector__XXX

BO_ 2327011359 wExt_Info_Temperatures_32: 8 wBMS
 SG_ Cell_Temperature_125 : 7|16@0- (0.01,0) [0|0] "" Vector__XXX
 SG_ Cell_Temperature_126 : 23|16@0- (0.01,0) [0|0] "" Vector__XXX
 SG_ Cell_Temperature_127 : 39|16@0- (0.01,0) [0|0] "" Vector__XXX
 SG_ Cell_Temperature_128 : 55|16@0- (0.01,0) [0|0] "" Vector__XXX

BO_ 2327011360 wExt_Info_Temperatures_33: 8 wBMS
 SG_ Cell_Temperature_129 : 7|16@0- (0.01,0) [0|0] "" Vector__XXX
 SG_ Cell_Temperature_130 : 23|16@0- (0.01,0) [0|0] "" Vector__XXX
 SG_ Cell_Temperature_131 : 39|16@0- (0.01,0) [0|0] "" Vector__XXX
 SG_ Cell_Temperature_132 : 55|16@0- (0.01,0) [0|0] "" Vector__XXX

BO_ 2327011361 wExt_Info_Temperatures_34: 8 wBMS
 SG_ Cell_Temperature_133 : 7|16@0- (0.01,0) [0|0] "" Vector__XXX
 SG_ Cell_Temperature_134 : 23|16@0- (0.01,0) [0|0] "" Vector__XXX
 SG_ Cell_Temperature_135 : 39|16@0- (0.01,0) [0|0] "" Vector__XXX
 SG_ Cell_Temperature_136 : 55|16@0- (0.01,0) [0|0] "" Vector__XXX

BO_ 2327011362 wExt_Info_Temperatures_35: 8 wBMS
 SG_ Cell_Temperature_137 : 7|16@0- (0.01,0) [0|0] "" Vector__XXX
 SG_ Cell_Temperature_138 : 23|16@0- (0.01,0) [0|0] "" Vector__XXX
 SG_ Cell_Temperature_139 : 39|16@0- (0.01,0) [0|0] "" Vector__XXX
 SG_ Cell_Temperature_140 : 55|16@0- (0.01,0) [0|0] "" Vector__XXX

BO_ 2327011363 wExt_Info_Temperatures_36: 8 wBMS
 SG_ Cell_Temperature_141 : 7|16@0- (0.01,0) [0|0] "" Vector__XXX
 SG_ Cell_Temperature_142 : 23|16@0- (0.01,0) [0|0] "" Vector__XXX
 SG_ Cell_Temperature_143 : 39|16@0- (0.01,0) [0|0] "" Vector__XXX
 SG_ Cell_Temperature_144 : 55|16@0- (0.01,0) [0|0] "" Vector__XXX

BO_ 2327011364 wExt_Info_Temperatures_37: 8 wBMS
 SG_ Cell_Temperature_145 : 7|16@0- (0.01,0) [0|0] "" Vector__XXX
 SG_ Cell_Temperature_146 : 23|16@0- (0.01,0) [0|0] "" Vector__XXX
 SG_ Cell_Temperature_147 : 39|16@0- (0.01,0) [0|0] "" Vector__XXX
 SG_ Cell_Temperature_148 : 55|16@0- (0.01,0) [0|0] "" Vector__XXX

BO_ 2327011365 wExt_Info_Temperatures_38: 8 wBMS
 SG_ Cell_Temperature_149 : 7|16@0- (0.01,0) [0|0] "" Vector__XXX
 SG_ Cell_Temperature_150 : 23|16@0- (0.01,0) [0|0] "" Vector__XXX
 SG_ Cell_Temperature_151 : 39|16@0- (0.01,0) [0|0] "" Vector__XXX
 SG_ Cell_Temperature_152 : 55|16@0- (0.01,0) [0|0] "" Vector__XXX

BO_ 2327011366 wExt_Info_Temperatures_39: 8 wBMS
 SG_ Cell_Temperature_153 : 7|16@0- (0.01,0) [0|0] "" Vector__XXX
 SG_ Cell_Temperature_154 : 23|16@0- (0.01,0) [0|0] "" Vector__XXX
 SG_ Cell_Temperature_155 : 39|16@0- (0.01,0) [0|0] "" Vector__XXX
 SG_ Cell_Temperature_156 : 55|16@0- (0.01,0) [0|0] "" Vector__XXX

BO_ 2327011367 wExt_Info_Temperatures_40: 8 wBMS
 SG_ Cell_Temperature_157 : 7|16@0- (0.01,0) [0|0] "" Vector__XXX
 SG_ Cell_Temperature_158 : 23|16@0- (0.01,0) [0|0] "" Vector__XXX
 SG_ Cell_Temperature_159 : 39|16@0- (0.01,0) [0|0] "" Vector__XXX
 SG_ Cell_Temperature_160 : 55|16@0- (0.01,0) [0|0] "" Vector__XXX

BO_ 2327011368 wExt_Info_Temperatures_41: 8 wBMS
 SG_ Cell_Temperature_161 : 7|16@0- (0.01,0) [0|0] "" Vector__XXX
 SG_ Cell_Temperature_162 : 23|16@0- (0.01,0) [0|0] "" Vector__XXX
 SG_ Cell_Temperature_163 : 39|16@0- (0.01,0) [0|0] "" Vector__XXX
 SG_ Cell_Temperature_164 : 55|16@0- (0.01,0) [0|0] "" Vector__XXX

BO_ 2327011369 wExt_Info_Temperatures_42: 8 wBMS
 SG_ Cell_Temperature_165 : 7|16@0- (0.01,0) [0|0] "" Vector__XXX
 SG_ Cell_Temperature_166 : 23|16@0- (0.01,0) [0|0] "" Vector__XXX
 SG_ Cell_Temperature_167 : 39|16@0- (0.01,0) [0|0] "" Vector__XXX
 SG_ Cell_Temperature_168 : 55|16@0- (0.01,0) [0|0] "" Vector__XXX

BO_ 2327011370 wExt_Info_Temperatures_43: 8 wBMS
 SG_ Cell_Temperature_169 : 7|16@0- (0.01,0) [0|0] "" Vector__XXX
 SG_ Cell_Temperature_170 : 23|16@0- (0.01,0) [0|0] "" Vector__XXX
 SG_ Cell_Temperature_171 : 39|16@0- (0.01,0) [0|0] "" Vector__XXX
 SG_ Cell_Temperature_172 : 55|16@0- (0.01,0) [0|0] "" Vector__XXX

BO_ 2327011371 wExt_Info_Temperatures_44: 8 wBMS
 SG_ Cell_Temperature_173 : 7|16@0- (0.01,0) [0|0] "" Vector__XXX
 SG_ Cell_Temperature_174 : 23|16@0- (0.01,0) [0|0] "" Vector__XXX
 SG_ Cell_Temperature_175 : 39|16@0- (0.01,0) [0|0] "" Vector__XXX
 SG_ Cell_Temperature_176 : 55|16@0- (0.01,0) [0|0] "" Vector__XXX

BO_ 2327011372 wExt_Info_Temperatures_45: 8 wBMS
 SG_ Cell_Temperature_177 : 7|16@0- (0.01,0) [0|0] "" Vector__XXX
 SG_ Cell_Temperature_178 : 23|16@0- (0.01,0) [0|0] "" Vector__XXX
 SG_ Cell_Temperature_179 : 39|16@0- (0.01,0) [0|0] "" Vector__XXX
 SG_ Cell_Temperature_180 : 55|16@0- (0.01,0) [0|0] "" Vector__XXX

BO_ 2327011373 wExt_Info_Temperatures_46: 8 wBMS
 SG_ Cell_Temperature_181 : 7|16@0- (0.01,0) [0|0] "" Vector__XXX
 SG_ Cell_Temperature_182 : 23|16@0- (0.01,0) [0|0] "" Vector__XXX
 SG_ Cell_Temperature_183 : 39|16@0- (0.01,0) [0|0] "" Vector__XXX
 SG_ Cell_Temperature_184 : 55|16@0- (0.01,0) [0|0] "" Vector__XXX

BO_ 2327011374 wExt_Info_Temperatures_47: 8 wBMS
 SG_ Cell_Temperature_185 : 7|16@0- (0.01,0) [0|0] "" Vector__XXX
 SG_ Cell_Temperature_186 : 23|16@0- (0.01,0) [0|0] "" Vector__XXX
 SG_ Cell_Temperature_187 : 39|16@0- (0.01,0) [0|0] "" Vector__XXX
 SG_ Cell_Temperature_188 : 55|16@0- (0.01,0) [0|0] "" Vector__XXX

BO_ 2327011375 wExt_Info_Temperatures_48: 8 wBMS
 SG_ Cell_Temperature_189 : 7|16@0- (0.01,0) [0|0] "" Vector__XXX
 SG_ Cell_Temperature_190 : 23|16@0- (0.01,0) [0|0] "" Vector__XXX
 SG_ Cell_Temperature_191 : 39|16@0- (0.01,0) [0|0] "" Vector__XXX
 SG_ Cell_Temperature_192 : 55|16@0- (0.01,0) [0|0] "" Vector__XXX

BO_ 2327011376 wExt_Info_Temperatures_49: 8 wBMS
 SG_ Cell_Temperature_193 : 7|16@0- (0.01,0) [0|0] "" Vector__XXX
 SG_ Cell_Temperature_194 : 23|16@0- (0.01,0) [0|0] "" Vector__XXX
 SG_ Cell_Temperature_195 : 39|16@0- (0.01,0) [0|0] "" Vector__XXX
 SG_ Cell_Temperature_196 : 55|16@0- (0.01,0) [0|0] "" Vector__XXX

BO_ 2327011377 wExt_Info_Temperatures_50: 8 wBMS
 SG_ Cell_Temperature_197 : 7|16@0- (0.01,0) [0|0] "" Vector__XXX
 SG_ Cell_Temperature_198 : 23|16@0- (0.01,0) [0|0] "" Vector__XXX
 SG_ Cell_Temperature_199 : 39|16@0- (0.01,0) [0|0] "" Vector__XXX
 SG_ Cell_Temperature_200 : 55|16@0- (0.01,0) [0|0] "" Vector__XXX

BO_ 2327011378 wExt_Info_Temperatures_51: 8 wBMS
 SG_ Cell_Temperature_201 : 7|16@0- (0.01,0) [0|0] "" Vector__XXX
 SG_ Cell_Temperature_202 : 23|16@0- (0.01,0) [0|0] "" Vector__XXX
 SG_ Cell_Temperature_203 : 39|16@0- (0.01,0) [0|0] "" Vector__XXX
 SG_ Cell_Temperature_204 : 55|16@0- (0.01,0) [0|0] "" Vector__XXX

BO_ 2327011379 wExt_Info_Temperatures_52: 8 wBMS
 SG_ Cell_Temperature_205 : 7|16@0- (0.01,0) [0|0] "" Vector__XXX
 SG_ Cell_Temperature_206 : 23|16@0- (0.01,0) [0|0] "" Vector__XXX
 SG_ Cell_Temperature_207 : 39|16@0- (0.01,0) [0|0] "" Vector__XXX
 SG_ Cell_Temperature_208 : 55|16@0- (0.01,0) [0|0] "" Vector__XXX

BO_ 2327011380 wExt_Info_Temperatures_53: 8 wBMS
 SG_ Cell_Temperature_209 : 7|16@0- (0.01,0) [0|0] "" Vector__XXX
 SG_ Cell_Temperature_210 : 23|16@0- (0.01,0) [0|0] "" Vector__XXX
 SG_ Cell_Temperature_211 : 39|16@0- (0.01,0) [0|0] "" Vector__XXX
 SG_ Cell_Temperature_212 : 55|16@0- (0.01,0) [0|0] "" Vector__XXX

BO_ 2327011381 wExt_Info_Temperatures_54: 8 wBMS
 SG_ Cell_Temperature_213 : 7|16@0- (0.01,0) [0|0] "" Vector__XXX
 SG_ Cell_Temperature_214 : 23|16@0- (0.01,0) [0|0] "" Vector__XXX
 SG_ Cell_Temperature_215 : 39|16@0- (0.01,0) [0|0] "" Vector__XXX
 SG_ Cell_Temperature_216 : 55|16@0- (0.01,0) [0|0] "" Vector__XXX

BO_ 2327011382 wExt_Info_Temperatures_55: 8 wBMS
 SG_ Cell_Temperature_217 : 7|16@0- (0.01,0) [0|0] "" Vector__XXX
 SG_ Cell_Temperature_218 : 23|16@0- (0.01,0) [0|0] "" Vector__XXX
 SG_ Cell_Temperature_219 : 39|16@0- (0.01,0) [0|0] "" Vector__XXX
 SG_ Cell_Temperature_220 : 55|16@0- (0.01,0) [0|0] "" Vector__XXX

BO_ 2327011383 wExt_Info_Temperatures_56: 8 wBMS
 SG_ Cell_Temperature_221 : 7|16@0- (0.01,0) [0|0] "" Vector__XXX
 SG_ Cell_Temperature_222 : 23|16@0- (0.01,0) [0|0] "" Vector__XXX
 SG_ Cell_Temperature_223 : 39|16@0- (0.01,0) [0|0] "" Vector__XXX
 SG_ Cell_Temperature_224 : 55|16@0- (0.01,0) [0|0] "" Vector__XXX

BO_ 2327011384 wExt_Info_Temperatures_57: 8 wBMS
 SG_ Cell_Temperature_225 : 7|16@0- (0.01,0) [0|0] "" Vector__XXX
 SG_ Cell_Temperature_226 : 23|16@0- (0.01,0) [0|0] "" Vector__XXX
 SG_ Cell_Temperature_227 : 39|16@0- (0.01,0) [0|0] "" Vector__XXX
 SG_ Cell_Temperature_228 : 55|16@0- (0.01,0) [0|0] "" Vector__XXX

BO_ 2327011385 wExt_Info_Temperatures_58: 8 wBMS
 SG_ Cell_Temperature_229 : 7|16@0- (0.01,0) [0|0] "" Vector__XXX
 SG_ Cell_Temperature_230 : 23|16@0- (0.01,0) [0|0] "" Vector__XXX
 SG_ Cell_Temperature_231 : 39|16@0- (0.01,0) [0|0] "" Vector__XXX
 SG_ Cell_Temperature_232 : 55|16@0- (0.01,0) [0|0] "" Vector__XXX

BO_ 2327011386 wExt_Info_Temperatures_59: 8 wBMS
 SG_ Cell_Temperature_233 : 7|16@0- (0.01,0) [0|0] "" Vector__XXX
 SG_ Cell_Temperature_234 : 23|16@0- (0.01,0) [0|0] "" Vector__XXX
 SG_ Cell_Temperature_235 : 39|16@0- (0.01,0) [0|0] "" Vector__XXX
 SG_ Cell_Temperature_236 : 55|16@0- (0.01,0) [0|0] "" Vector__XXX

BO_ 2327011387 wExt_Info_Temperatures_60: 8 wBMS
 SG_ Cell_Temperature_237 : 7|16@0- (0.01,0) [0|0] "" Vector__XXX
 SG_ Cell_Temperature_238 : 23|16@0- (0.01,0) [0|0] "" Vector__XXX
 SG_ Cell_Temperature_239 : 39|16@0- (0.01,0) [0|0] "" Vector__XXX
 SG_ Cell_Temperature_240 : 55|16@0- (0.01,0) [0|0] "" Vector__XXX

BO_ 2327011388 wExt_Info_Temperatures_61: 8 wBMS
 SG_ Cell_Temperature_241 : 7|16@0- (0.01,0) [0|0] "" Vector__XXX
 SG_ Cell_Temperature_242 : 23|16@0- (0.01,0) [0|0] "" Vector__XXX
 SG_ Cell_Temperature_243 : 39|16@0- (0.01,0) [0|0] "" Vector__XXX
 SG_ Cell_Temperature_244 : 55|16@0- (0.01,0) [0|0] "" Vector__XXX

BO_ 2327011389 wExt_Info_Temperatures_62: 8 wBMS
 SG_ Cell_Temperature_245 : 7|16@0- (0.01,0) [0|0] "" Vector__XXX
 SG_ Cell_Temperature_246 : 23|16@0- (0.01,0) [0|0] "" Vector__XXX
 SG_ Cell_Temperature_247 : 39|16@0- (0.01,0) [0|0] "" Vector__XXX
 SG_ Cell_Temperature_248 : 55|16@0- (0.01,0) [0|0] "" Vector__XXX

BO_ 2327011390 wExt_Info_Temperatures_63: 8 wBMS
 SG_ Cell_Temperature_249 : 7|16@0- (0.01,0) [0|0] "" Vector__XXX
 SG_ Cell_Temperature_250 : 23|16@0- (0.01,0) [0|0] "" Vector__XXX
 SG_ Cell_Temperature_251 : 39|16@0- (0.01,0) [0|0] "" Vector__XXX
 SG_ Cell_Temperature_252 : 55|16@0- (0.01,0) [0|0] "" Vector__XXX

BO_ 2327011391 wExt_Info_Temperatures_64: 8 wBMS
 SG_ Cell_Temperature_253 : 7|16@0- (0.01,0) [0|0] "" Vector__XXX
 SG_ Cell_Temperature_254 : 23|16@0- (0.01,0) [0|0] "" Vector__XXX
 SG_ Cell_Temperature_255 : 39|16@0- (0.01,0) [0|0] "" Vector__XXX
 SG_ Cell_Temperature_256 : 55|16@0- (0.01,0) [0|0] "" Vector__XXX

BO_ 2327011392 wExt_Info_Temperatures_65: 8 wBMS
 SG_ Cell_Temperature_257 : 7|16@0- (0.01,0) [0|0] "" Vector__XXX
 SG_ Cell_Temperature_258 : 23|16@0- (0.01,0) [0|0] "" Vector__XXX
 SG_ Cell_Temperature_259 : 39|16@0- (0.01,0) [0|0] "" Vector__XXX
 SG_ Cell_Temperature_260 : 55|16@0- (0.01,0) [0|0] "" Vector__XXX

BO_ 2327011393 wExt_Info_Temperatures_66: 8 wBMS
 SG_ Cell_Temperature_261 : 7|16@0- (0.01,0) [0|0] "" Vector__XXX
 SG_ Cell_Temperature_262 : 23|16@0- (0.01,0) [0|0] "" Vector__XXX
 SG_ Cell_Temperature_263 : 39|16@0- (0.01,0) [0|0] "" Vector__XXX
 SG_ Cell_Temperature_264 : 55|16@0- (0.01,0) [0|0] "" Vector__XXX

BO_ 2327011394 wExt_Info_Temperatures_67: 8 wBMS
 SG_ Cell_Temperature_265 : 7|16@0- (0.01,0) [0|0] "" Vector__XXX
 SG_ Cell_Temperature_266 : 23|16@0- (0.01,0) [0|0] "" Vector__XXX
 SG_ Cell_Temperature_267 : 39|16@0- (0.01,0) [0|0] "" Vector__XXX
 SG_ Cell_Temperature_268 : 55|16@0- (0.01,0) [0|0] "" Vector__XXX

BO_ 2327011395 wExt_Info_Temperatures_68: 8 wBMS
 SG_ Cell_Temperature_269 : 7|16@0- (0.01,0) [0|0] "" Vector__XXX
 SG_ Cell_Temperature_270 : 23|16@0- (0.01,0) [0|0] "" Vector__XXX
 SG_ Cell_Temperature_271 : 39|16@0- (0.01,0) [0|0] "" Vector__XXX
 SG_ Cell_Temperature_272 : 55|16@0- (0.01,0) [0|0] "" Vector__XXX

BO_ 2327011396 wExt_Info_Temperatures_69: 8 wBMS
 SG_ Cell_Temperature_273 : 7|16@0- (0.01,0) [0|0] "" Vector__XXX
 SG_ Cell_Temperature_274 : 23|16@0- (0.01,0) [0|0] "" Vector__XXX
 SG_ Cell_Temperature_275 : 39|16@0- (0.01,0) [0|0] "" Vector__XXX
 SG_ Cell_Temperature_276 : 55|16@0- (0.01,0) [0|0] "" Vector__XXX

BO_ 2327011397 wExt_Info_Temperatures_70: 8 wBMS
 SG_ Cell_Temperature_277 : 7|16@0- (0.01,0) [0|0] "" Vector__XXX
 SG_ Cell_Temperature_278 : 23|16@0- (0.01,0) [0|0] "" Vector__XXX
 SG_ Cell_Temperature_279 : 39|16@0- (0.01,0) [0|0] "" Vector__XXX
 SG_ Cell_Temperature_280 : 55|16@0- (0.01,0) [0|0] "" Vector__XXX

BO_ 2327011398 wExt_Info_Temperatures_71: 8 wBMS
 SG_ Cell_Temperature_281 : 7|16@0- (0.01,0) [0|0] "" Vector__XXX
 SG_ Cell_Temperature_282 : 23|16@0- (0.01,0) [0|0] "" Vector__XXX
 SG_ Cell_Temperature_283 : 39|16@0- (0.01,0) [0|0] "" Vector__XXX
 SG_ Cell_Temperature_284 : 55|16@0- (0.01,0) [0|0] "" Vector__XXX

BO_ 2327011399 wExt_Info_Temperatures_72: 8 wBMS
 SG_ Cell_Temperature_285 : 7|16@0- (0.01,0) [0|0] "" Vector__XXX
 SG_ Cell_Temperature_286 : 23|16@0- (0.01,0) [0|0] "" Vector__XXX
 SG_ Cell_Temperature_287 : 39|16@0- (0.01,0) [0|0] "" Vector__XXX
 SG_ Cell_Temperature_288 : 55|16@0- (0.01,0) [0|0] "" Vector__XXX

BO_ 2327011400 wExt_Info_Temperatures_73: 8 wBMS
 SG_ Cell_Temperature_289 : 7|16@0- (0.01,0) [0|0] "" Vector__XXX
 SG_ Cell_Temperature_290 : 23|16@0- (0.01,0) [0|0] "" Vector__XXX
 SG_ Cell_Temperature_291 : 39|16@0- (0.01,0) [0|0] "" Vector__XXX
 SG_ Cell_Temperature_292 : 55|16@0- (0.01,0) [0|0] "" Vector__XXX

BO_ 2327011401 wExt_Info_Temperatures_74: 8 wBMS
 SG_ Cell_Temperature_293 : 7|16@0- (0.01,0) [0|0] "" Vector__XXX
 SG_ Cell_Temperature_294 : 23|16@0- (0.01,0) [0|0] "" Vector__XXX
 SG_ Cell_Temperature_295 : 39|16@0- (0.01,0) [0|0] "" Vector__XXX
 SG_ Cell_Temperature_296 : 55|16@0- (0.01,0) [0|0] "" Vector__XXX

BO_ 2327011402 wExt_Info_Temperatures_75: 8 wBMS
 SG_ Cell_Temperature_297 : 7|16@0- (0.01,0) [0|0] "" Vector__XXX
 SG_ Cell_Temperature_298 : 23|16@0- (0.01,0) [0|0] "" Vector__XXX
 SG_ Cell_Temperature_299 : 39|16@0- (0.01,0) [0|0] "" Vector__XXX
 SG_ Cell_Temperature_300 : 55|16@0- (0.01,0) [0|0] "" Vector__XXX

BO_ 2327011403 wExt_Info_Temperatures_76: 8 wBMS
 SG_ Cell_Temperature_301 : 7|16@0- (0.01,0) [0|0] "" Vector__XXX
 SG_ Cell_Temperature_302 : 23|16@0- (0.01,0) [0|0] "" Vector__XXX
 SG_ Cell_Temperature_303 : 39|16@0- (0.01,0) [0|0] "" Vector__XXX
 SG_ Cell_Temperature_304 : 55|16@0- (0.01,0) [0|0] "" Vector__XXX

BO_ 2327011404 wExt_Info_Temperatures_77: 8 wBMS
 SG_ Cell_Temperature_305 : 7|16@0- (0.01,0) [0|0] "" Vector__XXX
 SG_ Cell_Temperature_306 : 23|16@0- (0.01,0) [0|0] "" Vector__XXX
 SG_ Cell_Temperature_307 : 39|16@0- (0.01,0) [0|0] "" Vector__XXX
 SG_ Cell_Temperature_308 : 55|16@0- (0.01,0) [0|0] "" Vector__XXX

BO_ 2327011405 wExt_Info_Temperatures_78: 8 wBMS
 SG_ Cell_Temperature_309 : 7|16@0- (0.01,0) [0|0] "" Vector__XXX
 SG_ Cell_Temperature_310 : 23|16@0- (0.01,0) [0|0] "" Vector__XXX
 SG_ Cell_Temperature_311 : 39|16@0- (0.01,0) [0|0] "" Vector__XXX
 SG_ Cell_Temperature_312 : 55|16@0- (0.01,0) [0|0] "" Vector__XXX

BO_ 2327011406 wExt_Info_Temperatures_79: 8 wBMS
 SG_ Cell_Temperature_313 : 7|16@0- (0.01,0) [0|0] "" Vector__XXX
 SG_ Cell_Temperature_314 : 23|16@0- (0.01,0) [0|0] "" Vector__XXX
 SG_ Cell_Temperature_315 : 39|16@0- (0.01,0) [0|0] "" Vector__XXX
 SG_ Cell_Temperature_316 : 55|16@0- (0.01,0) [0|0] "" Vector__XXX

BO_ 2327011407 wExt_Info_Temperatures_80: 8 wBMS
 SG_ Cell_Temperature_317 : 7|16@0- (0.01,0) [0|0] "" Vector__XXX
 SG_ Cell_Temperature_318 : 23|16@0- (0.01,0) [0|0] "" Vector__XXX
 SG_ Cell_Temperature_319 : 39|16@0- (0.01,0) [0|0] "" Vector__XXX
 SG_ Cell_Temperature_320 : 55|16@0- (0.01,0) [0|0] "" Vector__XXX

BO_ 2327011408 wExt_Info_Temperatures_81: 8 wBMS
 SG_ Cell_Temperature_321 : 7|16@0- (0.01,0) [0|0] "" Vector__XXX
 SG_ Cell_Temperature_322 : 23|16@0- (0.01,0) [0|0] "" Vector__XXX
 SG_ Cell_Temperature_323 : 39|16@0- (0.01,0) [0|0] "" Vector__XXX
 SG_ Cell_Temperature_324 : 55|16@0- (0.01,0) [0|0] "" Vector__XXX

BO_ 2327011409 wExt_Info_Temperatures_82: 8 wBMS
 SG_ Cell_Temperature_325 : 7|16@0- (0.01,0) [0|0] "" Vector__XXX
 SG_ Cell_Temperature_326 : 23|16@0- (0.01,0) [0|0] "" Vector__XXX
 SG_ Cell_Temperature_327 : 39|16@0- (0.01,0) [0|0] "" Vector__XXX
 SG_ Cell_Temperature_328 : 55|16@0- (0.01,0) [0|0] "" Vector__XXX

BO_ 2327011410 wExt_Info_Temperatures_83: 8 wBMS
 SG_ Cell_Temperature_329 : 7|16@0- (0.01,0) [0|0] "" Vector__XXX
 SG_ Cell_Temperature_330 : 23|16@0- (0.01,0) [0|0] "" Vector__XXX
 SG_ Cell_Temperature_331 : 39|16@0- (0.01,0) [0|0] "" Vector__XXX
 SG_ Cell_Temperature_332 : 55|16@0- (0.01,0) [0|0] "" Vector__XXX

BO_ 2327011411 wExt_Info_Temperatures_84: 8 wBMS
 SG_ Cell_Temperature_333 : 7|16@0- (0.01,0) [0|0] "" Vector__XXX
 SG_ Cell_Temperature_334 : 23|16@0- (0.01,0) [0|0] "" Vector__XXX
 SG_ Cell_Temperature_335 : 39|16@0- (0.01,0) [0|0] "" Vector__XXX
 SG_ Cell_Temperature_336 : 55|16@0- (0.01,0) [0|0] "" Vector__XXX

BO_ 2327011412 wExt_Info_Temperatures_85: 8 wBMS
 SG_ Cell_Temperature_337 : 7|16@0- (0.01,0) [0|0] "" Vector__XXX
 SG_ Cell_Temperature_338 : 23|16@0- (0.01,0) [0|0] "" Vector__XXX
 SG_ Cell_Temperature_339 : 39|16@0- (0.01,0) [0|0] "" Vector__XXX
 SG_ Cell_Temperature_340 : 55|16@0- (0.01,0) [0|0] "" Vector__XXX

BO_ 2327011413 wExt_Info_Temperatures_86: 8 wBMS
 SG_ Cell_Temperature_341 : 7|16@0- (0.01,0) [0|0] "" Vector__XXX
 SG_ Cell_Temperature_342 : 23|16@0- (0.01,0) [0|0] "" Vector__XXX
 SG_ Cell_Temperature_343 : 39|16@0- (0.01,0) [0|0] "" Vector__XXX
 SG_ Cell_Temperature_344 : 55|16@0- (0.01,0) [0|0] "" Vector__XXX

BO_ 2327011414 wExt_Info_Temperatures_87: 8 wBMS
 SG_ Cell_Temperature_345 : 7|16@0- (0.01,0) [0|0] "" Vector__XXX
 SG_ Cell_Temperature_346 : 23|16@0- (0.01,0) [0|0] "" Vector__XXX
 SG_ Cell_Temperature_347 : 39|16@0- (0.01,0) [0|0] "" Vector__XXX
 SG_ Cell_Temperature_348 : 55|16@0- (0.01,0) [0|0] "" Vector__XXX

BO_ 2327011415 wExt_Info_Temperatures_88: 8 wBMS
 SG_ Cell_Temperature_349 : 7|16@0- (0.01,0) [0|0] "" Vector__XXX
 SG_ Cell_Temperature_350 : 23|16@0- (0.01,0) [0|0] "" Vector__XXX
 SG_ Cell_Temperature_351 : 39|16@0- (0.01,0) [0|0] "" Vector__XXX
 SG_ Cell_Temperature_352 : 55|16@0- (0.01,0) [0|0] "" Vector__XXX

BO_ 2327011416 wExt_Info_Temperatures_89: 8 wBMS
 SG_ Cell_Temperature_353 : 7|16@0- (0.01,0) [0|0] "" Vector__XXX
 SG_ Cell_Temperature_354 : 23|16@0- (0.01,0) [0|0] "" Vector__XXX
 SG_ Cell_Temperature_355 : 39|16@0- (0.01,0) [0|0] "" Vector__XXX
 SG_ Cell_Temperature_356 : 55|16@0- (0.01,0) [0|0] "" Vector__XXX

BO_ 2327011417 wExt_Info_Temperatures_90: 8 wBMS
 SG_ Cell_Temperature_357 : 7|16@0- (0.01,0) [0|0] "" Vector__XXX
 SG_ Cell_Temperature_358 : 23|16@0- (0.01,0) [0|0] "" Vector__XXX
 SG_ Cell_Temperature_359 : 39|16@0- (0.01,0) [0|0] "" Vector__XXX
 SG_ Cell_Temperature_360 : 55|16@0- (0.01,0) [0|0] "" Vector__XXX

BO_ 2327011418 wExt_Info_Temperatures_91: 8 wBMS
 SG_ Cell_Temperature_361 : 7|16@0- (0.01,0) [0|0] "" Vector__XXX
 SG_ Cell_Temperature_362 : 23|16@0- (0.01,0) [0|0] "" Vector__XXX
 SG_ Cell_Temperature_363 : 39|16@0- (0.01,0) [0|0] "" Vector__XXX
 SG_ Cell_Temperature_364 : 55|16@0- (0.01,0) [0|0] "" Vector__XXX

BO_ 2327011419 wExt_Info_Temperatures_92: 8 wBMS
 SG_ Cell_Temperature_365 : 7|16@0- (0.01,0) [0|0] "" Vector__XXX
 SG_ Cell_Temperature_366 : 23|16@0- (0.01,0) [0|0] "" Vector__XXX
 SG_ Cell_Temperature_367 : 39|16@0- (0.01,0) [0|0] "" Vector__XXX
 SG_ Cell_Temperature_368 : 55|16@0- (0.01,0) [0|0] "" Vector__XXX

BO_ 2327011420 wExt_Info_Temperatures_93: 8 wBMS
 SG_ Cell_Temperature_369 : 7|16@0- (0.01,0) [0|0] "" Vector__XXX
 SG_ Cell_Temperature_370 : 23|16@0- (0.01,0) [0|0] "" Vector__XXX
 SG_ Cell_Temperature_371 : 39|16@0- (0.01,0) [0|0] "" Vector__XXX
 SG_ Cell_Temperature_372 : 55|16@0- (0.01,0) [0|0] "" Vector__XXX

BO_ 2327011421 wExt_Info_Temperatures_94: 8 wBMS
 SG_ Cell_Temperature_373 : 7|16@0- (0.01,0) [0|0] "" Vector__XXX
 SG_ Cell_Temperature_374 : 23|16@0- (0.01,0) [0|0] "" Vector__XXX
 SG_ Cell_Temperature_375 : 39|16@0- (0.01,0) [0|0] "" Vector__XXX
 SG_ Cell_Temperature_376 : 55|16@0- (0.01,0) [0|0] "" Vector__XXX

BO_ 2327011422 wExt_Info_Temperatures_95: 8 wBMS
 SG_ Cell_Temperature_377 : 7|16@0- (0.01,0) [0|0] "" Vector__XXX
 SG_ Cell_Temperature_378 : 23|16@0- (0.01,0) [0|0] "" Vector__XXX
 SG_ Cell_Temperature_379 : 39|16@0- (0.01,0) [0|0] "" Vector__XXX
 SG_ Cell_Temperature_380 : 55|16@0- (0.01,0) [0|0] "" Vector__XXX

BO_ 2327011423 wExt_Info_Temperatures_96: 8 wBMS
 SG_ Cell_Temperature_381 : 7|16@0- (0.01,0) [0|0] "" Vector__XXX
 SG_ Cell_Temperature_382 : 23|16@0- (0.01,0) [0|0] "" Vector__XXX
 SG_ Cell_Temperature_383 : 39|16@0- (0.01,0) [0|0] "" Vector__XXX
 SG_ Cell_Temperature_384 : 55|16@0- (0.01,0) [0|0] "" Vector__XXX

BO_ 2327011424 wExt_Info_Temperatures_97: 8 wBMS
 SG_ Cell_Temperature_385 : 7|16@0- (0.01,0) [0|0] "" Vector__XXX
 SG_ Cell_Temperature_386 : 23|16@0- (0.01,0) [0|0] "" Vector__XXX
 SG_ Cell_Temperature_387 : 39|16@0- (0.01,0) [0|0] "" Vector__XXX
 SG_ Cell_Temperature_388 : 55|16@0- (0.01,0) [0|0] "" Vector__XXX

BO_ 2327011425 wExt_Info_Temperatures_98: 8 wBMS
 SG_ Cell_Temperature_389 : 7|16@0- (0.01,0) [0|0] "" Vector__XXX
 SG_ Cell_Temperature_390 : 23|16@0- (0.01,0) [0|0] "" Vector__XXX
 SG_ Cell_Temperature_391 : 39|16@0- (0.01,0) [0|0] "" Vector__XXX
 SG_ Cell_Temperature_392 : 55|16@0- (0.01,0) [0|0] "" Vector__XXX

BO_ 2327011426 wExt_Info_Temperatures_99: 8 wBMS
 SG_ Cell_Temperature_393 : 7|16@0- (0.01,0) [0|0] "" Vector__XXX
 SG_ Cell_Temperature_394 : 23|16@0- (0.01,0) [0|0] "" Vector__XXX
 SG_ Cell_Temperature_395 : 39|16@0- (0.01,0) [0|0] "" Vector__XXX
 SG_ Cell_Temperature_396 : 55|16@0- (0.01,0) [0|0] "" Vector__XXX

BO_ 2327011427 wExt_Info_Temperatures_100: 8 wBMS
 SG_ Cell_Temperature_397 : 7|16@0- (0.01,0) [0|0] "" Vector__XXX
 SG_ Cell_Temperature_398 : 23|16@0- (0.01,0) [0|0] "" Vector__XXX
 SG_ Cell_Temperature_399 : 39|16@0- (0.01,0) [0|0] "" Vector__XXX
 SG_ Cell_Temperature_400 : 55|16@0- (0.01,0) [0|0] "" Vector__XXX

BO_ 2327011428 wExt_Info_Temperatures_101: 8 wBMS
 SG_ Cell_Temperature_401 : 7|16@0- (0.01,0) [0|0] "" Vector__XXX
 SG_ Cell_Temperature_402 : 23|16@0- (0.01,0) [0|0] "" Vector__XXX
 SG_ Cell_Temperature_403 : 39|16@0- (0.01,0) [0|0] "" Vector__XXX
 SG_ Cell_Temperature_404 : 55|16@0- (0.01,0) [0|0] "" Vector__XXX

BO_ 2327011429 wExt_Info_Temperatures_102: 8 wBMS
 SG_ Cell_Temperature_405 : 7|16@0- (0.01,0) [0|0] "" Vector__XXX
 SG_ Cell_Temperature_406 : 23|16@0- (0.01,0) [0|0] "" Vector__XXX
 SG_ Cell_Temperature_407 : 39|16@0- (0.01,0) [0|0] "" Vector__XXX
 SG_ Cell_Temperature_408 : 55|16@0- (0.01,0) [0|0] "" Vector__XXX

BO_ 2327011430 wExt_Info_Temperatures_103: 8 wBMS
 SG_ Cell_Temperature_409 : 7|16@0- (0.01,0) [0|0] "" Vector__XXX
 SG_ Cell_Temperature_410 : 23|16@0- (0.01,0) [0|0] "" Vector__XXX
 SG_ Cell_Temperature_411 : 39|16@0- (0.01,0) [0|0] "" Vector__XXX
 SG_ Cell_Temperature_412 : 55|16@0- (0.01,0) [0|0] "" Vector__XXX

BO_ 2327011431 wExt_Info_Temperatures_104: 8 wBMS
 SG_ Cell_Temperature_413 : 7|16@0- (0.01,0) [0|0] "" Vector__XXX
 SG_ Cell_Temperature_414 : 23|16@0- (0.01,0) [0|0] "" Vector__XXX
 SG_ Cell_Temperature_415 : 39|16@0- (0.01,0) [0|0] "" Vector__XXX
 SG_ Cell_Temperature_416 : 55|16@0- (0.01,0) [0|0] "" Vector__XXX

BO_ 2327011432 wExt_Info_Temperatures_105: 8 wBMS
 SG_ Cell_Temperature_417 : 7|16@0- (0.01,0) [0|0] "" Vector__XXX
 SG_ Cell_Temperature_418 : 23|16@0- (0.01,0) [0|0] "" Vector__XXX
 SG_ Cell_Temperature_419 : 39|16@0- (0.01,0) [0|0] "" Vector__XXX
 SG_ Cell_Temperature_420 : 55|16@0- (0.01,0) [0|0] "" Vector__XXX

BO_ 2327011433 wExt_Info_Temperatures_106: 8 wBMS
 SG_ Cell_Temperature_421 : 7|16@0- (0.01,0) [0|0] "" Vector__XXX
 SG_ Cell_Temperature_422 : 23|16@0- (0.01,0) [0|0] "" Vector__XXX
 SG_ Cell_Temperature_423 : 39|16@0- (0.01,0) [0|0] "" Vector__XXX
 SG_ Cell_Temperature_424 : 55|16@0- (0.01,0) [0|0] "" Vector__XXX

BO_ 2327011434 wExt_Info_Temperatures_107: 8 wBMS
 SG_ Cell_Temperature_425 : 7|16@0- (0.01,0) [0|0] "" Vector__XXX
 SG_ Cell_Temperature_426 : 23|16@0- (0.01,0) [0|0] "" Vector__XXX
 SG_ Cell_Temperature_427 : 39|16@0- (0.01,0) [0|0] "" Vector__XXX
 SG_ Cell_Temperature_428 : 55|16@0- (0.01,0) [0|0] "" Vector__XXX

BO_ 2327011435 wExt_Info_Temperatures_108: 8 wBMS
 SG_ Cell_Temperature_429 : 7|16@0- (0.01,0) [0|0] "" Vector__XXX
 SG_ Cell_Temperature_430 : 23|16@0- (0.01,0) [0|0] "" Vector__XXX
 SG_ Cell_Temperature_431 : 39|16@0- (0.01,0) [0|0] "" Vector__XXX
 SG_ Cell_Temperature_432 : 55|16@0- (0.01,0) [0|0] "" Vector__XXX

BA_DEF_  "BusType" STRING ;
BA_DEF_ BO_  "MsgCycleTime" INT 0 65535;
BA_DEF_DEF_  "BusType" "CAN";
BA_DEF_DEF_  "MsgCycleTime" 0;
BA_ "MsgCycleTime" BO_ 2325962752 500;
BA_ "MsgCycleTime" BO_ 2325962753 500;
BA_ "MsgCycleTime" BO_ 2325962754 500;
BA_ "MsgCycleTime" BO_ 2325962755 500;
BA_ "MsgCycleTime" BO_ 2325962756 500;
BA_ "MsgCycleTime" BO_ 2325962757 500;
BA_ "MsgCycleTime" BO_ 2325962758 500;
BA_ "MsgCycleTime" BO_ 2325962759 500;
BA_ "MsgCycleTime" BO_ 2325962760 500;
BA_ "MsgCycleTime" BO_ 2325962761 500;
BA_ "MsgCycleTime" BO_ 2325962762 500;
BA_ "MsgCycleTime" BO_ 2325962763 500;
BA_ "MsgCycleTime" BO_ 2325962764 500;
BA_ "MsgCycleTime" BO_ 2325962765 500;
BA_ "MsgCycleTime" BO_ 2325962766 500;
BA_ "MsgCycleTime" BO_ 2325962767 500;
BA_ "MsgCycleTime" BO_ 2325962768 500;
BA_ "MsgCycleTime" BO_ 2325962769 500;
BA_ "MsgCycleTime" BO_ 2325962770 500;
BA_ "MsgCycleTime" BO_ 2325962771 500;
BA_ "MsgCycleTime" BO_ 2325962772 500;
BA_ "MsgCycleTime" BO_ 2325962773 500;
BA_ "MsgCycleTime" BO_ 2325962774 500;
BA_ "MsgCycleTime" BO_ 2325962775 500;
BA_ "MsgCycleTime" BO_ 2325962776 500;
BA_ "MsgCycleTime" BO_ 2325962777 500;
BA_ "MsgCycleTime" BO_ 2325962778 500;
BA_ "MsgCycleTime" BO_ 2325962779 500;
BA_ "MsgCycleTime" BO_ 2325962780 500;
BA_ "MsgCycleTime" BO_ 2325962781 500;
BA_ "MsgCycleTime" BO_ 2325962782 500;
BA_ "MsgCycleTime" BO_ 2325962783 500;
BA_ "MsgCycleTime" BO_ 2325962784 500;
BA_ "MsgCycleTime" BO_ 2325962785 500;
BA_ "MsgCycleTime" BO_ 2325962786 500;
BA_ "MsgCycleTime" BO_ 2325962787 500;
BA_ "MsgCycleTime" BO_ 2325962788 500;
BA_ "MsgCycleTime" BO_ 2325962789 500;
BA_ "MsgCycleTime" BO_ 2325962790 500;
BA_ "MsgCycleTime" BO_ 2325962791 500;
BA_ "MsgCycleTime" BO_ 2325962792 500;
BA_ "MsgCycleTime" BO_ 2325962793 500;
BA_ "MsgCycleTime" BO_ 2325962794 500;
BA_ "MsgCycleTime" BO_ 2325962795 500;
BA_ "MsgCycleTime" BO_ 2325962796 500;
BA_ "MsgCycleTime" BO_ 2325962797 500;
BA_ "MsgCycleTime" BO_ 2325962798 500;
BA_ "MsgCycleTime" BO_ 2325962799 500;
BA_ "MsgCycleTime" BO_ 2325962800 500;
BA_ "MsgCycleTime" BO_ 2325962801 500;
BA_ "MsgCycleTime" BO_ 2325962802 500;
BA_ "MsgCycleTime" BO_ 2325962803 500;
BA_ "MsgCycleTime" BO_ 2325962804 500;
BA_ "MsgCycleTime" BO_ 2325962805 500;
BA_ "MsgCycleTime" BO_ 2325962806 500;
BA_ "MsgCycleTime" BO_ 2325962807 500;
BA_ "MsgCycleTime" BO_ 2325962808 500;
BA_ "MsgCycleTime" BO_ 2325962809 500;
BA_ "MsgCycleTime" BO_ 2325962810 500;
BA_ "MsgCycleTime" BO_ 2325962811 500;
BA_ "MsgCycleTime" BO_ 2325962812 500;
BA_ "MsgCycleTime" BO_ 2325962813 500;
BA_ "MsgCycleTime" BO_ 2325962814 500;
BA_ "MsgCycleTime" BO_ 2325962815 500;
BA_ "MsgCycleTime" BO_ 2325962816 500;
BA_ "MsgCycleTime" BO_ 2325962817 500;
BA_ "MsgCycleTime" BO_ 2325962818 500;
BA_ "MsgCycleTime" BO_ 2325962819 500;
BA_ "MsgCycleTime" BO_ 2325962820 500;
BA_ "MsgCycleTime" BO_ 2325962821 500;
BA_ "MsgCycleTime" BO_ 2325962822 500;
BA_ "MsgCycleTime" BO_ 2325962823 500;
BA_ "MsgCycleTime" BO_ 2325962824 500;
BA_ "MsgCycleTime" BO_ 2325962825 500;
BA_ "MsgCycleTime" BO_ 2325962826 500;
BA_ "MsgCycleTime" BO_ 2325962827 500;
BA_ "MsgCycleTime" BO_ 2325962828 500;
BA_ "MsgCycleTime" BO_ 2325962829 500;
BA_ "MsgCycleTime" BO_ 2325962830 500;
BA_ "MsgCycleTime" BO_ 2325962831 500;
BA_ "MsgCycleTime" BO_ 2325962832 500;
BA_ "MsgCycleTime" BO_ 2325962833 500;
BA_ "MsgCycleTime" BO_ 2325962834 500;
BA_ "MsgCycleTime" BO_ 2325962835 500;
BA_ "MsgCycleTime" BO_ 2325962836 500;
BA_ "MsgCycleTime" BO_ 2325962837 500;
BA_ "MsgCycleTime" BO_ 2325962838 500;
BA_ "MsgCycleTime" BO_ 2325962839 500;
BA_ "MsgCycleTime" BO_ 2325962840 500;
BA_ "MsgCycleTime" BO_ 2325962841 500;
BA_ "MsgCycleTime" BO_ 2325962842 500;
BA_ "MsgCycleTime" BO_ 2325962843 500;
BA_ "MsgCycleTime" BO_ 2325962844 500;
BA_ "MsgCycleTime" BO_ 2325962845 500;
BA_ "MsgCycleTime" BO_ 2325962846 500;
BA_ "MsgCycleTime" BO_ 2325962847 500;
BA_ "MsgCycleTime" BO_ 2325962848 500;
BA_ "MsgCycleTime" BO_ 2325962849 500;
BA_ "MsgCycleTime" BO_ 2325962850 500;
BA_ "MsgCycleTime" BO_ 2325962851 500;
BA_ "MsgCycleTime" BO_ 2325962852 500;
BA_ "MsgCycleTime" BO_ 2325962853 500;
BA_ "MsgCycleTime" BO_ 2325962854 500;
BA_ "MsgCycleTime" BO_ 2325962855 500;
BA_ "MsgCycleTime" BO_ 2325962856 500;
BA_ "MsgCycleTime" BO_ 2325962857 500;
BA_ "MsgCycleTime" BO_ 2325962858 500;
BA_ "MsgCycleTime" BO_ 2325962859 500;
BA_ "MsgCycleTime" BO_ 2325962860 500;
BA_ "MsgCycleTime" BO_ 2325962861 500;
BA_ "MsgCycleTime" BO_ 2325962862 500;
BA_ "MsgCycleTime" BO_ 2325962863 500;
BA_ "MsgCycleTime" BO_ 2325962864 500;
BA_ "MsgCycleTime" BO_ 2325962865 500;
BA_ "MsgCycleTime" BO_ 2325962866 500;
BA_ "MsgCycleTime" BO_ 2325962867 500;
BA_ "MsgCycleTime" BO_ 2325962868 500;
BA_ "MsgCycleTime" BO_ 2325962869 500;
BA_ "MsgCycleTime" BO_ 2325962870 500;
BA_ "MsgCycleTime" BO_ 2325962871 500;
BA_ "MsgCycleTime" BO_ 2325962872 500;
BA_ "MsgCycleTime" BO_ 2325962873 500;
BA_ "MsgCycleTime" BO_ 2325962874 500;
BA_ "MsgCycleTime" BO_ 2325962875 500;
BA_ "MsgCycleTime" BO_ 2325962876 500;
BA_ "MsgCycleTime" BO_ 2325962877 500;
BA_ "MsgCycleTime" BO_ 2325962878 500;
BA_ "MsgCycleTime" BO_ 2325962879 500;
BA_ "MsgCycleTime" BO_ 2325962880 500;
BA_ "MsgCycleTime" BO_ 2325962881 500;
BA_ "MsgCycleTime" BO_ 2325962882 500;
BA_ "MsgCycleTime" BO_ 2325962883 500;
BA_ "MsgCycleTime" BO_ 2325962884 500;
BA_ "MsgCycleTime" BO_ 2325962885 500;
BA_ "MsgCycleTime" BO_ 2325962886 500;
BA_ "MsgCycleTime" BO_ 2325962887 500;
BA_ "MsgCycleTime" BO_ 2325962888 500;
BA_ "MsgCycleTime" BO_ 2325962889 500;
BA_ "MsgCycleTime" BO_ 2325962890 500;
BA_ "MsgCycleTime" BO_ 2325962891 500;
BA_ "MsgCycleTime" BO_ 2325962892 500;
BA_ "MsgCycleTime" BO_ 2325962893 500;
BA_ "MsgCycleTime" BO_ 2325962894 500;
BA_ "MsgCycleTime" BO_ 2325962895 500;
BA_ "MsgCycleTime" BO_ 2325962896 500;
BA_ "MsgCycleTime" BO_ 2325962897 500;
BA_ "MsgCycleTime" BO_ 2325962898 500;
BA_ "MsgCycleTime" BO_ 2325962899 500;
BA_ "MsgCycleTime" BO_ 2325962900 500;
BA_ "MsgCycleTime" BO_ 2325962901 500;
BA_ "MsgCycleTime" BO_ 2325962902 500;
BA_ "MsgCycleTime" BO_ 2325962903 500;
BA_ "MsgCycleTime" BO_ 2325962904 500;
BA_ "MsgCycleTime" BO_ 2325962905 500;
BA_ "MsgCycleTime" BO_ 2325962906 500;
BA_ "MsgCycleTime" BO_ 2325962907 500;
BA_ "MsgCycleTime" BO_ 2325962908 500;
BA_ "MsgCycleTime" BO_ 2325962909 500;
BA_ "MsgCycleTime" BO_ 2325962910 500;
BA_ "MsgCycleTime" BO_ 2325962911 500;
BA_ "MsgCycleTime" BO_ 2325962912 500;
BA_ "MsgCycleTime" BO_ 2325962913 500;
BA_ "MsgCycleTime" BO_ 2325962914 500;
BA_ "MsgCycleTime" BO_ 2325962915 500;
BA_ "MsgCycleTime" BO_ 2325962916 500;
BA_ "MsgCycleTime" BO_ 2325962917 500;
BA_ "MsgCycleTime" BO_ 2325962918 500;
BA_ "MsgCycleTime" BO_ 2325962919 500;
BA_ "MsgCycleTime" BO_ 2325962920 500;
BA_ "MsgCycleTime" BO_ 2325962921 500;
BA_ "MsgCycleTime" BO_ 2325962922 500;
BA_ "MsgCycleTime" BO_ 2325962923 500;
BA_ "MsgCycleTime" BO_ 2325962924 500;
BA_ "MsgCycleTime" BO_ 2325962925 500;
BA_ "MsgCycleTime" BO_ 2325962926 500;
BA_ "MsgCycleTime" BO_ 2325962927 500;
BA_ "MsgCycleTime" BO_ 2325962928 500;
BA_ "MsgCycleTime" BO_ 2325962929 500;
BA_ "MsgCycleTime" BO_ 2325962930 500;
BA_ "MsgCycleTime" BO_ 2325962931 500;
BA_ "MsgCycleTime" BO_ 2325962932 500;
BA_ "MsgCycleTime" BO_ 2325962933 500;
BA_ "MsgCycleTime" BO_ 2325962934 500;
BA_ "MsgCycleTime" BO_ 2325962935 500;
BA_ "MsgCycleTime" BO_ 2325962936 500;
BA_ "MsgCycleTime" BO_ 2325962937 500;
BA_ "MsgCycleTime" BO_ 2325962938 500;
BA_ "MsgCycleTime" BO_ 2325962939 500;
BA_ "MsgCycleTime" BO_ 2325962940 500;
BA_ "MsgCycleTime" BO_ 2325962941 500;
BA_ "MsgCycleTime" BO_ 2325962942 500;
BA_ "MsgCycleTime" BO_ 2325962943 500;
BA_ "MsgCycleTime" BO_ 2325962944 500;
BA_ "MsgCycleTime" BO_ 2325962945 500;
BA_ "MsgCycleTime" BO_ 2325962946 500;
BA_ "MsgCycleTime" BO_ 2325962947 500;
BA_ "MsgCycleTime" BO_ 2325962948 500;
BA_ "MsgCycleTime" BO_ 2325962949 500;
BA_ "MsgCycleTime" BO_ 2325962950 500;
BA_ "MsgCycleTime" BO_ 2325962951 500;
BA_ "MsgCycleTime" BO_ 2325962952 500;
BA_ "MsgCycleTime" BO_ 2325962953 500;
BA_ "MsgCycleTime" BO_ 2325962954 500;
BA_ "MsgCycleTime" BO_ 2325962955 500;
BA_ "MsgCycleTime" BO_ 2325962956 500;
BA_ "MsgCycleTime" BO_ 2325962957 500;
BA_ "MsgCycleTime" BO_ 2325962958 500;
BA_ "MsgCycleTime" BO_ 2325962959 500;
BA_ "MsgCycleTime" BO_ 2325962960 500;
BA_ "MsgCycleTime" BO_ 2325962961 500;
BA_ "MsgCycleTime" BO_ 2325962962 500;
BA_ "MsgCycleTime" BO_ 2325962963 500;
BA_ "MsgCycleTime" BO_ 2325962964 500;
BA_ "MsgCycleTime" BO_ 2325962965 500;
BA_ "MsgCycleTime" BO_ 2325962966 500;
BA_ "MsgCycleTime" BO_ 2325962967 500;
BA_ "MsgCycleTime" BO_ 2327011328 500;
BA_ "MsgCycleTime" BO_ 2327011329 500;
BA_ "MsgCycleTime" BO_ 2327011330 500;
BA_ "MsgCycleTime" BO_ 2327011331 500;
BA_ "MsgCycleTime" BO_ 2327011332 500;
BA_ "MsgCycleTime" BO_ 2327011333 500;
BA_ "MsgCycleTime" BO_ 2327011334 500;
BA_ "MsgCycleTime" BO_ 2327011335 500;
BA_ "MsgCycleTime" BO_ 2327011336 500;
BA_ "MsgCycleTime" BO_ 2327011337 500;
BA_ "MsgCycleTime" BO_ 2327011338 500;
BA_ "MsgCycleTime" BO_ 2327011339 500;
BA_ "MsgCycleTime" BO_ 2327011340 500;
BA_ "MsgCycleTime" BO_ 2327011341 500;
BA_ "MsgCycleTime" BO_ 2327011342 500;
BA_ "MsgCycleTime" BO_ 2327011343 500;
BA_ "MsgCycleTime" BO_ 2327011344 500;
BA_ "MsgCycleTime" BO_ 2327011345 500;
BA_ "MsgCycleTime" BO_ 2327011346 500;
BA_ "MsgCycleTime" BO_ 2327011347 500;
BA_ "MsgCycleTime" BO_ 2327011348 500;
BA_ "MsgCycleTime" BO_ 2327011349 500;
BA_ "MsgCycleTime" BO_ 2327011350 500;
BA_ "MsgCycleTime" BO_ 2327011351 500;
BA_ "MsgCycleTime" BO_ 2327011352 500;
BA_ "MsgCycleTime" BO_ 2327011353 500;
BA_ "MsgCycleTime" BO_ 2327011354 500;
BA_ "MsgCycleTime" BO_ 2327011355 500;
BA_ "MsgCycleTime" BO_ 2327011356 500;
BA_ "MsgCycleTime" BO_ 2327011357 500;
BA_ "MsgCycleTime" BO_ 2327011358 500;
BA_ "MsgCycleTime" BO_ 2327011359 500;
BA_ "MsgCycleTime" BO_ 2327011360 500;
BA_ "MsgCycleTime" BO_ 2327011361 500;
BA_ "MsgCycleTime" BO_ 2327011362 500;
BA_ "MsgCycleTime" BO_ 2327011363 500;
BA_ "MsgCycleTime" BO_ 2327011364 500;
BA_ "MsgCycleTime" BO_ 2327011365 500;
BA_ "MsgCycleTime" BO_ 2327011366 500;
BA_ "MsgCycleTime" BO_ 2327011367 500;
BA_ "MsgCycleTime" BO_ 2327011368 500;
BA_ "MsgCycleTime" BO_ 2327011369 500;
BA_ "MsgCycleTime" BO_ 2327011370 500;
BA_ "MsgCycleTime" BO_ 2327011371 500;
BA_ "MsgCycleTime" BO_ 2327011372 500;
BA_ "MsgCycleTime" BO_ 2327011373 500;
BA_ "MsgCycleTime" BO_ 2327011374 500;
BA_ "MsgCycleTime" BO_ 2327011375 500;
BA_ "MsgCycleTime" BO_ 2327011376 500;
BA_ "MsgCycleTime" BO_ 2327011377 500;
BA_ "MsgCycleTime" BO_ 2327011378 500;
BA_ "MsgCycleTime" BO_ 2327011379 500;
BA_ "MsgCycleTime" BO_ 2327011380 500;
BA_ "MsgCycleTime" BO_ 2327011381 500;
BA_ "MsgCycleTime" BO_ 2327011382 500;
BA_ "MsgCycleTime" BO_ 2327011383 500;
BA_ "MsgCycleTime" BO_ 2327011384 500;
BA_ "MsgCycleTime" BO_ 2327011385 500;
BA_ "MsgCycleTime" BO_ 2327011386 500;
BA_ "MsgCycleTime" BO_ 2327011387 500;
BA_ "MsgCycleTime" BO_ 2327011388 500;
BA_ "MsgCycleTime" BO_ 2327011389 500;
BA_ "MsgCycleTime" BO_ 2327011390 500;
BA_ "MsgCycleTime" BO_ 2327011391 500;
BA_ "MsgCycleTime" BO_ 2327011392 500;
BA_ "MsgCycleTime" BO_ 2327011393 500;
BA_ "MsgCycleTime" BO_ 2327011394 500;
BA_ "MsgCycleTime" BO_ 2327011395 500;
BA_ "MsgCycleTime" BO_ 2327011396 500;
BA_ "MsgCycleTime" BO_ 2327011397 500;
BA_ "MsgCycleTime" BO_ 2327011398 500;
BA_ "MsgCycleTime" BO_ 2327011399 500;
BA_ "MsgCycleTime" BO_ 2327011400 500;
BA_ "MsgCycleTime" BO_ 2327011401 500;
BA_ "MsgCycleTime" BO_ 2327011402 500;
BA_ "MsgCycleTime" BO_ 2327011403 500;
BA_ "MsgCycleTime" BO_ 2327011404 500;
BA_ "MsgCycleTime" BO_ 2327011405 500;
BA_ "MsgCycleTime" BO_ 2327011406 500;
BA_ "MsgCycleTime" BO_ 2327011407 500;
BA_ "MsgCycleTime" BO_ 2327011408 500;
BA_ "MsgCycleTime" BO_ 2327011409 500;
BA_ "MsgCycleTime" BO_ 2327011410 500;
BA_ "MsgCycleTime" BO_ 2327011411 500;
BA_ "MsgCycleTime" BO_ 2327011412 500;
BA_ "MsgCycleTime" BO_ 2327011413 500;
BA_ "MsgCycleTime" BO_ 2327011414 500;
BA_ "MsgCycleTime" BO_ 2327011415 500;
BA_ "MsgCycleTime" BO_ 2327011416 500;
BA_ "MsgCycleTime" BO_ 2327011417 500;
BA_ "MsgCycleTime" BO_ 2327011418 500;
BA_ "MsgCycleTime" BO_ 2327011419 500;
BA_ "MsgCycleTime" BO_ 2327011420 500;
BA_ "MsgCycleTime" BO_ 2327011421 500;
BA_ "MsgCycleTime" BO_ 2327011422 500;
BA_ "MsgCycleTime" BO_ 2327011423 500;
BA_ "MsgCycleTime" BO_ 2327011424 500;
BA_ "MsgCycleTime" BO_ 2327011425 500;
BA_ "MsgCycleTime" BO_ 2327011426 500;
BA_ "MsgCycleTime" BO_ 2327011427 500;
BA_ "MsgCycleTime" BO_ 2327011428 500;
BA_ "MsgCycleTime" BO_ 2327011429 500;
BA_ "MsgCycleTime" BO_ 2327011430 500;
BA_ "MsgCycleTime" BO_ 2327011431 500;
BA_ "MsgCycleTime" BO_ 2327011432 500;
BA_ "MsgCycleTime" BO_ 2327011433 500;
BA_ "MsgCycleTime" BO_ 2327011434 500;
BA_ "MsgCycleTime" BO_ 2327011435 500;
